VERSION ""

NS_ :

BS_:

BU_: Sound_A Ladegeraet_PAG_PF Motor_EDC17_Pirol PSM_Ant_Derivate GW_Routing_Derivate GW_Applikation_Derivate BMS_Hybrid Getriebe_Derivate LEH_Hybrid Motor_MED17_Hybrid Sound_I Tool Airbag Waehlhebel

BO_ 262 ESP_05_VW: 8 PSM_Ant_Derivate
 SG_ ESP_Status_Anfahrhilfe : 40|1@1+ (1,0) [0|1] ""  Motor_EDC17_Pirol,Motor_MED17_Hybrid,GW_Routing_Derivate
 SG_ ESP_Anforderung_EPB : 62|2@1+ (1,0) [0|3] ""  GW_Routing_Derivate
 SG_ ESP_Lenkeingriff_ADS : 28|1@1+ (1,0) [0|1] ""  GW_Routing_Derivate
 SG_ ESP_Bremsruck_AWV2 : 30|1@1+ (1,0) [0|1] ""  GW_Routing_Derivate
 SG_ ESP_Konsistenz_AWV2 : 31|1@1+ (1,0) [0|1] ""  GW_Routing_Derivate
 SG_ ESP_05_CHK : 0|8@1+ (1,0) [0|255] ""  Motor_EDC17_Pirol,Motor_MED17_Hybrid,GW_Routing_Derivate,Getriebe_Derivate
 SG_ ESP_05_BZ : 8|4@1+ (1,0) [0|15] ""  Motor_EDC17_Pirol,Motor_MED17_Hybrid,GW_Routing_Derivate,Getriebe_Derivate
 SG_ ESP_QBit_Bremsdruck : 12|1@1+ (1,0) [0|1] ""  Motor_EDC17_Pirol,Motor_MED17_Hybrid,GW_Routing_Derivate,Getriebe_Derivate
 SG_ ESP_QBit_Fahrer_bremst : 13|1@1+ (1,0) [0|1] ""  Motor_EDC17_Pirol,Motor_MED17_Hybrid,GW_Routing_Derivate
 SG_ ESP_Schwelle_Unterdruck : 14|2@1+ (1,0) [0|3] ""  Motor_EDC17_Pirol,Motor_MED17_Hybrid,GW_Routing_Derivate
 SG_ ESP_Bremsdruck : 16|10@1+ (0.3,-30) [-30|276.6] "Unit_Bar"  Motor_EDC17_Pirol,Motor_MED17_Hybrid,GW_Routing_Derivate,Getriebe_Derivate
 SG_ ESP_Fahrer_bremst : 26|1@1+ (1,0) [0|1] ""  Motor_EDC17_Pirol,Motor_MED17_Hybrid,GW_Routing_Derivate
 SG_ ESP_Verz_TSK_aktiv : 27|1@1+ (1,0) [0|1] ""  Motor_EDC17_Pirol,Getriebe_Derivate,Motor_MED17_Hybrid,GW_Routing_Derivate
 SG_ ESP_Konsistenz_TSK : 29|1@1+ (1,0) [0|1] ""  Motor_EDC17_Pirol,Motor_MED17_Hybrid,GW_Routing_Derivate
 SG_ ECD_Fehler : 32|1@1+ (1,0) [0|1] ""  Motor_EDC17_Pirol,Motor_MED17_Hybrid,GW_Routing_Derivate
 SG_ ECD_nicht_verfuegbar : 33|1@1+ (1,0) [0|1] ""  Motor_EDC17_Pirol,Motor_MED17_Hybrid,GW_Routing_Derivate
 SG_ ESP_Status_Bremsentemp : 34|1@1+ (1,0) [0|1] ""  Motor_EDC17_Pirol,Motor_MED17_Hybrid,GW_Routing_Derivate
 SG_ ESP_Autohold_Standby : 35|1@1+ (1,0) [0|1] ""  GW_Routing_Derivate
 SG_ ESP_HDC_Standby : 36|1@1+ (1,0) [0|1] ""  Motor_EDC17_Pirol,Motor_MED17_Hybrid,GW_Routing_Derivate
 SG_ ESP_HBA_aktiv : 37|1@1+ (1,0) [0|1] ""  GW_Routing_Derivate
 SG_ ESP_Prefill_ausgeloest : 38|1@1+ (1,0) [0|1] ""  GW_Routing_Derivate
 SG_ ESP_Rueckwaertsfahrt_erkannt : 39|1@1+ (1,0) [0|1] ""  GW_Routing_Derivate
 SG_ ESP_StartStopp_Info : 42|2@1+ (1,0) [0|3] ""  Motor_EDC17_Pirol,Motor_MED17_Hybrid,GW_Routing_Derivate
 SG_ ESP_Eingr_HL : 44|1@1+ (1,0) [0|1] ""  GW_Routing_Derivate
 SG_ ESP_Eingr_HR : 45|1@1+ (1,0) [0|1] ""  GW_Routing_Derivate
 SG_ ESP_Eingr_VL : 46|1@1+ (1,0) [0|1] ""  GW_Routing_Derivate
 SG_ ESP_Eingr_VR : 47|1@1+ (1,0) [0|1] ""  GW_Routing_Derivate
 SG_ ESP_BKV_Unterdruck : 48|8@1+ (4,0) [0|256] "Unit_MilliBar"  Motor_EDC17_Pirol,Motor_MED17_Hybrid,GW_Routing_Derivate
 SG_ ESP_Autohold_aktiv : 56|1@1+ (1,0) [0|1] ""  Motor_EDC17_Pirol,Motor_MED17_Hybrid,GW_Routing_Derivate
 SG_ ESP_FStatus_Anfahrhilfe : 57|1@1+ (1,0) [0|1] ""  GW_Routing_Derivate
 SG_ ESP_Verz_EPB_aktiv : 58|1@1+ (1,0) [0|1] ""  GW_Routing_Derivate,Getriebe_Derivate
 SG_ ECD_Bremslicht : 59|1@1+ (1,0) [0|1] ""  Motor_EDC17_Pirol,Motor_MED17_Hybrid,GW_Routing_Derivate
 SG_ ESP_Verzoeg_EPB_verf : 60|1@1+ (1,0) [0|1] ""  GW_Routing_Derivate
 SG_ ESP_Status_Bremsdruck : 61|1@1+ (1,0) [0|1] ""  Motor_EDC17_Pirol,Motor_MED17_Hybrid,GW_Routing_Derivate

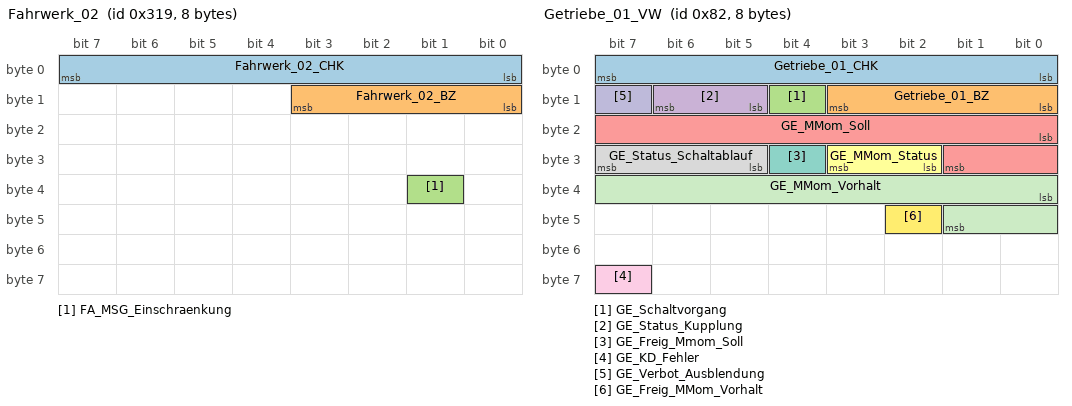
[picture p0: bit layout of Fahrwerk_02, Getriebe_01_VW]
BO_ 793 Fahrwerk_02: 8 GW_Routing_Derivate
 SG_ Fahrwerk_02_CHK : 0|8@1+ (1,0) [0|255] ""  Motor_EDC17_Pirol,Motor_MED17_Hybrid
 SG_ Fahrwerk_02_BZ : 8|4@1+ (1,0) [0|15] ""  Motor_EDC17_Pirol,Motor_MED17_Hybrid
 SG_ FA_MSG_Einschraenkung : 33|1@1+ (1,0) [0|1] ""  Motor_EDC17_Pirol,Motor_MED17_Hybrid

BO_ 924 Gateway_05_VW: 8 GW_Routing_Derivate
 SG_ KL_Beschlagsgefahr : 30|1@1+ (1,0) [0|1] "" Vector__XXX
 SG_ ESP_07_alt : 4|1@1+ (1,0) [0|1] "" Vector__XXX
 SG_ BCM1_GLW_Fernlicht_Anf : 31|1@1+ (1,0) [0|1] "" Vector__XXX
 SG_ BCM1_Gleitende_Leuchtw_Anf : 54|1@1+ (1,0) [0|1] "" Vector__XXX
 SG_ BCM1_Adaptive_Lichtvert_Anf : 53|1@1+ (1,0) [0|1] "" Vector__XXX
 SG_ ESP_Offroad_Modus : 56|1@1+ (1,0) [0|1] ""  Getriebe_Derivate
 SG_ Wischer_vorne_aktiv : 17|1@1+ (1,0) [0|1] ""  Motor_EDC17_Pirol,Motor_MED17_Hybrid
 SG_ HR_Tuer_geoeffnet : 52|1@1+ (1,0) [0|1] ""  Motor_EDC17_Pirol,Motor_MED17_Hybrid
 SG_ HL_Tuer_geoeffnet : 51|1@1+ (1,0) [0|1] ""  Motor_EDC17_Pirol,Motor_MED17_Hybrid
 SG_ FT_Sperrklinke : 35|1@1+ (1,0) [0|1] ""  Motor_EDC17_Pirol,Motor_MED17_Hybrid
 SG_ BT_Tuer_geoeffnet : 50|1@1+ (1,0) [0|1] ""  Motor_EDC17_Pirol,Motor_MED17_Hybrid
 SG_ BCM1_02_alt : 0|1@1+ (1,0) [0|1] ""  Motor_EDC17_Pirol,Motor_MED17_Hybrid
 SG_ BCM1_01_alt : 3|1@1+ (1,0) [0|1] ""  Motor_EDC17_Pirol,Motor_MED17_Hybrid
 SG_ FT_Tuer_geoeffnet : 33|1@1+ (1,0) [0|1] ""  Motor_EDC17_Pirol,Getriebe_Derivate,Motor_MED17_Hybrid
 SG_ BCM1_Rueckfahrlicht_Schalter : 18|1@1+ (1,0) [0|1] ""  Motor_EDC17_Pirol,Motor_MED17_Hybrid
 SG_ BCM1_MH_WIV_Schalter : 16|1@1+ (1,0) [0|1] ""  Motor_EDC17_Pirol,Motor_MED17_Hybrid
 SG_ BCM1_Aussen_Temp_ungef : 40|8@1+ (0.5,-50) [-50|76] "Unit_DegreCelsi"  LEH_Hybrid,BMS_Hybrid,Motor_EDC17_Pirol,Motor_MED17_Hybrid
 SG_ BCM2_03_PAG_alt : 11|1@1+ (1,0) [0|1] "" Vector__XXX
 SG_ Klima_02_alt : 2|1@1+ (1,0) [0|1] "" Vector__XXX
 SG_ KL_Zuheizer_Freigabe : 20|1@1+ (1,0) [0|1] "" Vector__XXX
 SG_ BCM_Handshake_STH : 34|1@1+ (1,0) [0|1] "" Vector__XXX
 SG_ Wischer_01_alt : 1|1@1+ (1,0) [0|1] ""  Motor_EDC17_Pirol,Motor_MED17_Hybrid
 SG_ TSG_BT_1_alt : 5|1@1+ (1,0) [0|1] ""  Motor_EDC17_Pirol,Motor_MED17_Hybrid
 SG_ TSG_HL_1_alt : 6|1@1+ (1,0) [0|1] ""  Motor_EDC17_Pirol,Motor_MED17_Hybrid
 SG_ TSG_HR_1_alt : 7|1@1+ (1,0) [0|1] ""  Motor_EDC17_Pirol,Motor_MED17_Hybrid
 SG_ Klima_Sensor_02_alt : 9|1@1+ (1,0) [0|1] ""  LEH_Hybrid,BMS_Hybrid,Motor_EDC17_Pirol,Motor_MED17_Hybrid
 SG_ TSG_FT_1_alt : 10|1@1+ (1,0) [0|1] ""  Motor_EDC17_Pirol,Getriebe_Derivate,Motor_MED17_Hybrid
 SG_ Parkhilfe_01_alt : 13|1@1+ (1,0) [0|1] ""  Motor_EDC17_Pirol,Motor_MED17_Hybrid
 SG_ Fahrwerk_02_alt : 14|1@1+ (1,0) [0|1] ""  Motor_EDC17_Pirol,Motor_MED17_Hybrid
 SG_ FA_StartStopp_Info : 26|2@1+ (1,0) [0|3] ""  Motor_EDC17_Pirol,Motor_MED17_Hybrid
 SG_ PH_StartStopp_Info : 28|2@1+ (1,0) [0|3] ""  Motor_EDC17_Pirol,Motor_MED17_Hybrid
 SG_ BCM1_OBD_FStatus_ATemp : 36|4@1+ (1,0) [0|15] ""  Motor_EDC17_Pirol,Motor_MED17_Hybrid
 SG_ BCM1_Schalter_StartStopp : 55|1@1+ (1,0) [0|1] ""  Motor_EDC17_Pirol,Motor_MED17_Hybrid

BO_ 1604 Gateway_11_VW: 8 GW_Routing_Derivate
 SG_ ESP_Diagnose : 38|1@1+ (1,0) [0|1] "" Vector__XXX
 SG_ ESP_04_alt : 7|1@1+ (1,0) [0|1] "" Vector__XXX
 SG_ ZV_Tankklappe_offen : 45|1@1+ (1,0) [0|1] "" Vector__XXX
 SG_ BCM_Tankwunsch : 43|2@1+ (1,0) [0|3] "" Vector__XXX
 SG_ ZV_verriegelt_extern_ist : 42|1@1+ (1,0) [0|1] ""  Ladegeraet_PAG_PF
 SG_ BCM2_02_alt : 4|1@1+ (1,0) [0|1] "" Vector__XXX
 SG_ Kessy_01_alt : 8|1@1+ (1,0) [0|1] ""  Ladegeraet_PAG_PF
 SG_ FFB_CarFinder : 41|1@1+ (1,0) [0|1] ""  Ladegeraet_PAG_PF
 SG_ FFB_Auf_Taste : 40|1@1+ (1,0) [0|1] ""  Ladegeraet_PAG_PF
 SG_ Dummy_Blinkmodi_01_alt : 15|1@1+ (1,0) [0|1] "" Vector__XXX
 SG_ BCM1_01_alt : 2|1@1+ (1,0) [0|1] "" Vector__XXX
 SG_ LV_Nebelschlusslicht_Anzeige : 30|1@1+ (1,0) [0|1] "" Vector__XXX
 SG_ LV_Abblendlicht_re_def : 26|1@1+ (1,0) [0|1] "" Vector__XXX
 SG_ LV_Abblendlicht_li_def : 25|1@1+ (1,0) [0|1] "" Vector__XXX
 SG_ BM_Autobahn : 18|1@1+ (1,0) [0|1] "" Vector__XXX
 SG_ BCM1_Touristen_Licht_Anf : 24|1@1+ (1,0) [0|1] "" Vector__XXX
 SG_ BCM1_Linksverkehr : 31|1@1+ (1,0) [0|1] "" Vector__XXX
 SG_ BCM1_Licht_Dunkelheit_aktiv : 29|1@1+ (1,0) [0|1] "" Vector__XXX
 SG_ BCM1_Allwetterlicht_Anf : 36|1@1+ (1,0) [0|1] "" Vector__XXX
 SG_ BCM1_MH_Schalter : 21|1@1+ (1,0) [0|1] ""  Motor_EDC17_Pirol,Motor_MED17_Hybrid
 SG_ BH_Blinker_re : 17|1@1+ (1,0) [0|1] ""  Motor_EDC17_Pirol,Motor_MED17_Hybrid
 SG_ BH_Blinker_li : 16|1@1+ (1,0) [0|1] ""  Motor_EDC17_Pirol,Motor_MED17_Hybrid
 SG_ SMLS_01_alt : 0|1@1+ (1,0) [0|1] ""  Motor_EDC17_Pirol,Motor_MED17_Hybrid
 SG_ BCM1_02_alt : 3|1@1+ (1,0) [0|1] ""  Ladegeraet_PAG_PF,Motor_EDC17_Pirol,Motor_MED17_Hybrid
 SG_ HYB_Anf_E_Mode_alt : 5|1@1+ (1,0) [0|1] ""  Motor_MED17_Hybrid
 SG_ HYB_Anf_E_Mode : 22|1@1+ (1,0) [0|1] ""  Motor_MED17_Hybrid

BO_ 130 Getriebe_01_VW: 8 Getriebe_Derivate
 SG_ Getriebe_01_CHK : 0|8@1+ (1,0) [0|255] ""  Motor_EDC17_Pirol,PSM_Ant_Derivate,GW_Routing_Derivate,Motor_MED17_Hybrid
 SG_ Getriebe_01_BZ : 8|4@1+ (1,0) [0|15] ""  Motor_EDC17_Pirol,PSM_Ant_Derivate,GW_Routing_Derivate,Motor_MED17_Hybrid
 SG_ GE_Schaltvorgang : 12|1@1+ (1,0) [0|1] ""  Motor_EDC17_Pirol,PSM_Ant_Derivate,GW_Routing_Derivate,Motor_MED17_Hybrid
 SG_ GE_Status_Kupplung : 13|2@1+ (1,0) [0|3] ""  Motor_EDC17_Pirol,PSM_Ant_Derivate,GW_Routing_Derivate,Motor_MED17_Hybrid
 SG_ GE_MMom_Soll : 16|10@1+ (1,0) [0|1021] ""  Motor_EDC17_Pirol,PSM_Ant_Derivate,GW_Routing_Derivate,Motor_MED17_Hybrid
 SG_ GE_MMom_Status : 26|2@1+ (1,0) [0|3] ""  Motor_EDC17_Pirol,PSM_Ant_Derivate,GW_Routing_Derivate,Motor_MED17_Hybrid
 SG_ GE_Freig_Mmom_Soll : 28|1@1+ (1,0) [0|1] ""  PSM_Ant_Derivate,GW_Routing_Derivate
 SG_ GE_Status_Schaltablauf : 29|3@1+ (1,0) [0|7] ""  PSM_Ant_Derivate,GW_Routing_Derivate
 SG_ GE_KD_Fehler : 63|1@1+ (1,0) [0|1] ""  PSM_Ant_Derivate,GW_Applikation_Derivate,GW_Routing_Derivate
 SG_ GE_Verbot_Ausblendung : 15|1@1+ (1,0) [0|1] ""  GW_Routing_Derivate,Motor_EDC17_Pirol,Motor_MED17_Hybrid
 SG_ GE_MMom_Vorhalt : 32|10@1+ (1,0) [0|1021] ""  GW_Routing_Derivate,Motor_EDC17_Pirol,Motor_MED17_Hybrid
 SG_ GE_Freig_MMom_Vorhalt : 42|1@1+ (1,0) [0|1] ""  GW_Routing_Derivate,Motor_EDC17_Pirol,Motor_MED17_Hybrid

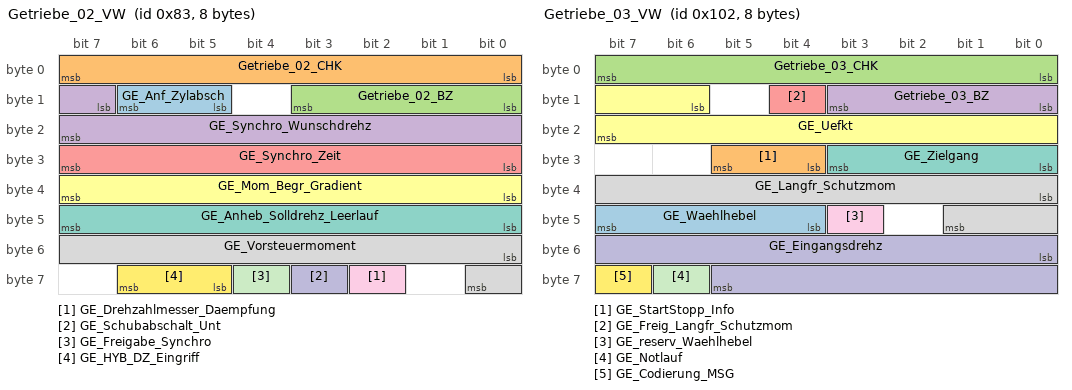
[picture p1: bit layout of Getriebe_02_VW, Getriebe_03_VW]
BO_ 131 Getriebe_02_VW: 8 Getriebe_Derivate
 SG_ GE_Anf_Zylabsch : 13|2@1+ (1,0) [0|3] "" Vector__XXX
 SG_ Getriebe_02_CHK : 0|8@1+ (1,0) [0|255] ""  Motor_EDC17_Pirol,Motor_MED17_Hybrid
 SG_ Getriebe_02_BZ : 8|4@1+ (1,0) [0|15] ""  Motor_EDC17_Pirol,Motor_MED17_Hybrid
 SG_ GE_Synchro_Wunschdrehz : 15|9@1+ (25,0) [0|12750] "Unit_MinutInver"  Motor_EDC17_Pirol,Motor_MED17_Hybrid
 SG_ GE_Synchro_Zeit : 24|8@1+ (20,0) [0|5080] "Unit_MilliSecon"  Motor_EDC17_Pirol,Motor_MED17_Hybrid
 SG_ GE_Mom_Begr_Gradient : 32|8@1+ (10,0) [0|2540] "Unit_NewtoMeterPerSecon"  Motor_EDC17_Pirol,Motor_MED17_Hybrid
 SG_ GE_Anheb_Solldrehz_Leerlauf : 40|8@1+ (10,0) [0|2540] "Unit_MinutInver"  Motor_EDC17_Pirol,Motor_MED17_Hybrid
 SG_ GE_Vorsteuermoment : 48|9@1+ (1,0) [0|509] ""  Motor_EDC17_Pirol,Motor_MED17_Hybrid
 SG_ GE_Drehzahlmesser_Daempfung : 58|1@1+ (1,0) [0|1] ""  Motor_EDC17_Pirol,Motor_MED17_Hybrid
 SG_ GE_Schubabschalt_Unt : 59|1@1+ (1,0) [0|1] ""  Motor_EDC17_Pirol,Motor_MED17_Hybrid
 SG_ GE_Freigabe_Synchro : 60|1@1+ (1,0) [0|1] ""  Motor_EDC17_Pirol,Motor_MED17_Hybrid
 SG_ GE_HYB_DZ_Eingriff : 61|2@1+ (1,0) [0|3] ""  Motor_MED17_Hybrid

BO_ 258 Getriebe_03_VW: 8 Getriebe_Derivate
 SG_ GE_Waehlhebel : 44|4@1+ (1,0) [0|15] ""  Motor_EDC17_Pirol,GW_Routing_Derivate,PSM_Ant_Derivate,Motor_MED17_Hybrid
 SG_ GE_StartStopp_Info : 28|2@1+ (1,0) [0|3] ""  Motor_EDC17_Pirol,GW_Routing_Derivate,PSM_Ant_Derivate,Motor_MED17_Hybrid
 SG_ Getriebe_03_CHK : 0|8@1+ (1,0) [0|255] ""  Motor_EDC17_Pirol,PSM_Ant_Derivate,GW_Routing_Derivate,Motor_MED17_Hybrid
 SG_ Getriebe_03_BZ : 8|4@1+ (1,0) [0|15] ""  Motor_EDC17_Pirol,PSM_Ant_Derivate,GW_Routing_Derivate,Motor_MED17_Hybrid
 SG_ GE_Freig_Langfr_Schutzmom : 12|1@1+ (1,0) [0|1] ""  Motor_EDC17_Pirol,PSM_Ant_Derivate,GW_Routing_Derivate,Motor_MED17_Hybrid
 SG_ GE_Uefkt : 14|10@1+ (0.1,0) [0|102.2] ""  Motor_EDC17_Pirol,PSM_Ant_Derivate,GW_Routing_Derivate,Motor_MED17_Hybrid
 SG_ GE_Zielgang : 24|4@1+ (1,0) [0|15] ""  Motor_EDC17_Pirol,PSM_Ant_Derivate,GW_Routing_Derivate,Motor_MED17_Hybrid
 SG_ GE_Langfr_Schutzmom : 32|10@1+ (1,0) [0|1021] ""  Motor_EDC17_Pirol,PSM_Ant_Derivate,GW_Routing_Derivate,Motor_MED17_Hybrid
 SG_ GE_reserv_Waehlhebel : 43|1@1+ (1,0) [0|1] ""  PSM_Ant_Derivate,GW_Routing_Derivate
 SG_ GE_Eingangsdrehz : 48|14@1+ (1,0) [0|16381] "Unit_MinutInver"  Motor_EDC17_Pirol,PSM_Ant_Derivate,GW_Routing_Derivate,Motor_MED17_Hybrid
 SG_ GE_Notlauf : 62|1@1+ (1,0) [0|1] ""  Motor_EDC17_Pirol,PSM_Ant_Derivate,GW_Routing_Derivate,Motor_MED17_Hybrid
 SG_ GE_Codierung_MSG : 63|1@1+ (1,0) [0|1] ""  PSM_Ant_Derivate,GW_Routing_Derivate

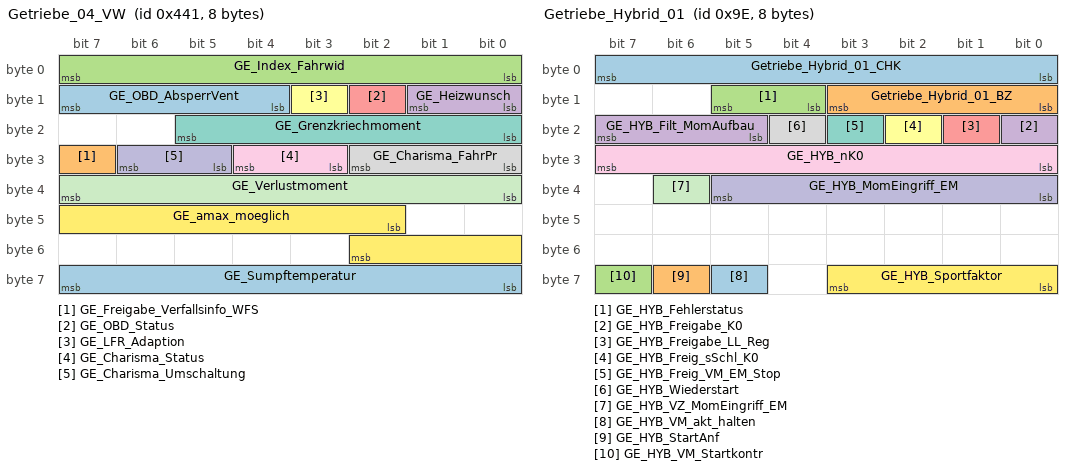
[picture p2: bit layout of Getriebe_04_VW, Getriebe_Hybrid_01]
BO_ 1089 Getriebe_04_VW: 8 Getriebe_Derivate
 SG_ GE_OBD_AbsperrVent : 12|4@1+ (1,0) [0|15] ""  GW_Routing_Derivate,Motor_EDC17_Pirol,Motor_MED17_Hybrid
 SG_ GE_Freigabe_Verfallsinfo_WFS : 31|1@1+ (1,0) [0|1] ""  GW_Routing_Derivate
 SG_ GE_Index_Fahrwid : 0|8@1+ (0.249,-31.623) [-31.623|31.623] ""  GW_Routing_Derivate,Motor_EDC17_Pirol,PSM_Ant_Derivate,Motor_MED17_Hybrid
 SG_ GE_Heizwunsch : 8|2@1+ (1,0) [0|3] ""  GW_Routing_Derivate,PSM_Ant_Derivate,Motor_MED17_Hybrid,Motor_EDC17_Pirol
 SG_ GE_OBD_Status : 10|1@1+ (1,0) [0|1] ""  GW_Routing_Derivate,Motor_EDC17_Pirol,PSM_Ant_Derivate,Motor_MED17_Hybrid
 SG_ GE_LFR_Adaption : 11|1@1+ (1,0) [0|1] ""  GW_Routing_Derivate,Motor_EDC17_Pirol,PSM_Ant_Derivate,Motor_MED17_Hybrid
 SG_ GE_Grenzkriechmoment : 16|6@1+ (2,0) [0|122] ""  GW_Routing_Derivate,PSM_Ant_Derivate
 SG_ GE_Charisma_FahrPr : 24|3@1+ (1,0) [0|7] ""  GW_Routing_Derivate
 SG_ GE_Charisma_Status : 27|2@1+ (1,0) [0|3] ""  GW_Routing_Derivate,PSM_Ant_Derivate
 SG_ GE_Charisma_Umschaltung : 29|2@1+ (1,0) [0|3] ""  GW_Routing_Derivate
 SG_ GE_Verlustmoment : 32|8@1+ (1,0) [0|254] ""  GW_Routing_Derivate,Motor_EDC17_Pirol,PSM_Ant_Derivate,Motor_MED17_Hybrid
 SG_ GE_amax_moeglich : 42|9@1+ (0.024,-2.016) [-2.016|10.224] "Unit_MeterPerSeconSquar"  GW_Routing_Derivate,Motor_EDC17_Pirol,PSM_Ant_Derivate,Motor_MED17_Hybrid
 SG_ GE_Sumpftemperatur : 56|8@1+ (1,-58) [-58|196] "Unit_DegreCelsi"  GW_Routing_Derivate,BMS_Hybrid,Motor_EDC17_Pirol,PSM_Ant_Derivate,Motor_MED17_Hybrid

BO_ 158 Getriebe_Hybrid_01: 8 Getriebe_Derivate
 SG_ Getriebe_Hybrid_01_CHK : 0|8@1+ (1,0) [0|255] "" Vector__XXX
 SG_ Getriebe_Hybrid_01_BZ : 8|4@1+ (1,0) [0|15] ""  Motor_MED17_Hybrid
 SG_ GE_HYB_Fehlerstatus : 12|2@1+ (1,0) [0|3] ""  Motor_MED17_Hybrid
 SG_ GE_HYB_Freigabe_K0 : 16|1@1+ (1,0) [0|1] ""  Motor_MED17_Hybrid
 SG_ GE_HYB_Freigabe_LL_Reg : 17|1@1+ (1,0) [0|1] ""  Motor_MED17_Hybrid
 SG_ GE_HYB_Freig_sSchl_K0 : 18|1@1+ (1,0) [0|1] ""  Motor_MED17_Hybrid
 SG_ GE_HYB_Freig_VM_EM_Stop : 19|1@1+ (1,0) [0|1] ""  Motor_MED17_Hybrid
 SG_ GE_HYB_Wiederstart : 20|1@1+ (1,0) [0|1] ""  Motor_MED17_Hybrid
 SG_ GE_HYB_nK0 : 24|8@1+ (25,0) [0|6350] "Unit_MinutInver" Vector__XXX
 SG_ GE_HYB_MomEingriff_EM : 32|6@1+ (0.5,0) [0|31.5] "Unit_NewtoMeter" Vector__XXX
 SG_ GE_HYB_VZ_MomEingriff_EM : 38|1@1+ (1,0) [0|1] "" Vector__XXX
 SG_ GE_HYB_Sportfaktor : 56|4@1+ (1,0) [0|15] ""  Motor_MED17_Hybrid
 SG_ GE_HYB_VM_akt_halten : 61|1@1+ (1,0) [0|1] ""  Motor_MED17_Hybrid
 SG_ GE_HYB_StartAnf : 62|1@1+ (1,0) [0|1] ""  Motor_MED17_Hybrid
 SG_ GE_HYB_VM_Startkontr : 63|1@1+ (1,0) [0|1] ""  Motor_MED17_Hybrid
 SG_ GE_HYB_Filt_MomAufbau : 21|3@1+ (1,0) [0|7] "" Vector__XXX

BO_ 2022 ISO_EMotor_01_Req: 8 GW_Routing_Derivate
 SG_ ISO_EMotor_01_Req_Data : 0|64@1+ (1,0) [0|1] ""  LEH_Hybrid

BO_ 2030 ISO_EMotor_01_Resp: 8 LEH_Hybrid
 SG_ ISO_EMotor_01_Resp_Data : 0|64@1+ (1,0) [0|1] ""  GW_Routing_Derivate

BO_ 2021 ISO_Hybrid_01_Req: 8 GW_Routing_Derivate
 SG_ ISO_Hybrid_01_Req_Data : 0|64@1+ (1,0) [0|1] ""  BMS_Hybrid

BO_ 2029 ISO_Hybrid_01_Resp: 8 BMS_Hybrid
 SG_ ISO_Hybrid_01_Resp_Data : 0|64@1+ (1,0) [0|1] ""  GW_Routing_Derivate

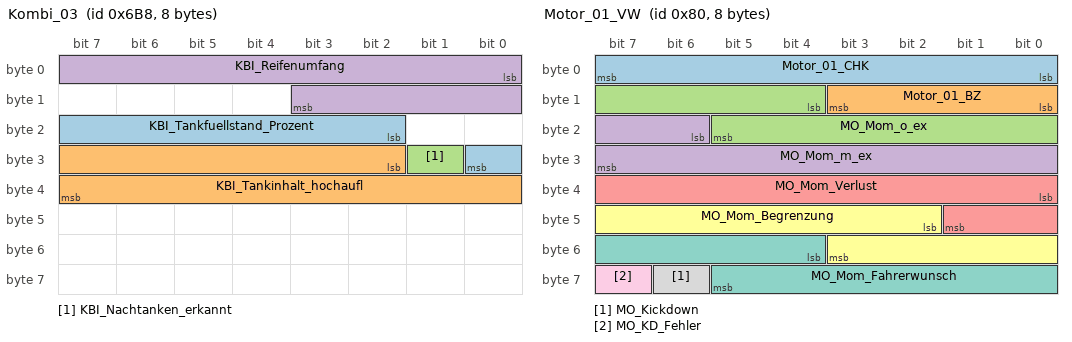
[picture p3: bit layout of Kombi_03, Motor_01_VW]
BO_ 1720 Kombi_03: 8 GW_Routing_Derivate
 SG_ KBI_Tankfuellstand_Prozent : 18|7@1+ (1,0) [0|100] "Unit_PerCent" Vector__XXX
 SG_ KBI_Tankinhalt_hochaufl : 26|14@1+ (0.01,0) [0|163.81] "Unit_Liter"  BMS_Hybrid
 SG_ KBI_Nachtanken_erkannt : 25|1@1+ (1,0) [0|1] ""  BMS_Hybrid
 SG_ KBI_Reifenumfang : 0|12@1+ (1,0) [0|4095] "Unit_MilliMeter"  Motor_MED17_Hybrid,PSM_Ant_Derivate

BO_ 128 Motor_01_VW: 8 Motor_MED17_Hybrid
 SG_ Motor_01_CHK : 0|8@1+ (1,0) [0|255] ""  PSM_Ant_Derivate,GW_Routing_Derivate,Getriebe_Derivate
 SG_ Motor_01_BZ : 8|4@1+ (1,0) [0|15] ""  PSM_Ant_Derivate,GW_Routing_Derivate,Getriebe_Derivate
 SG_ MO_Mom_o_ex : 12|10@1+ (1,0) [0|1021] ""  Sound_A,Sound_I,PSM_Ant_Derivate,GW_Routing_Derivate,Getriebe_Derivate
 SG_ MO_Mom_m_ex : 22|10@1+ (1,0) [0|1021] ""  PSM_Ant_Derivate,GW_Routing_Derivate,Getriebe_Derivate
 SG_ MO_Mom_Verlust : 32|10@1+ (1,0) [0|1021] ""  Sound_A,Sound_I,PSM_Ant_Derivate,GW_Routing_Derivate,Getriebe_Derivate
 SG_ MO_Mom_Begrenzung : 42|10@1+ (1,0) [0|1021] ""  PSM_Ant_Derivate,GW_Routing_Derivate,Getriebe_Derivate
 SG_ MO_Mom_Fahrerwunsch : 52|10@1+ (1,0) [0|1021] ""  PSM_Ant_Derivate,GW_Routing_Derivate,Getriebe_Derivate
 SG_ MO_Kickdown : 62|1@1+ (1,0) [0|1] ""  PSM_Ant_Derivate,GW_Routing_Derivate,Getriebe_Derivate
 SG_ MO_KD_Fehler : 63|1@1+ (1,0) [0|1] ""  PSM_Ant_Derivate,GW_Applikation_Derivate,GW_Routing_Derivate

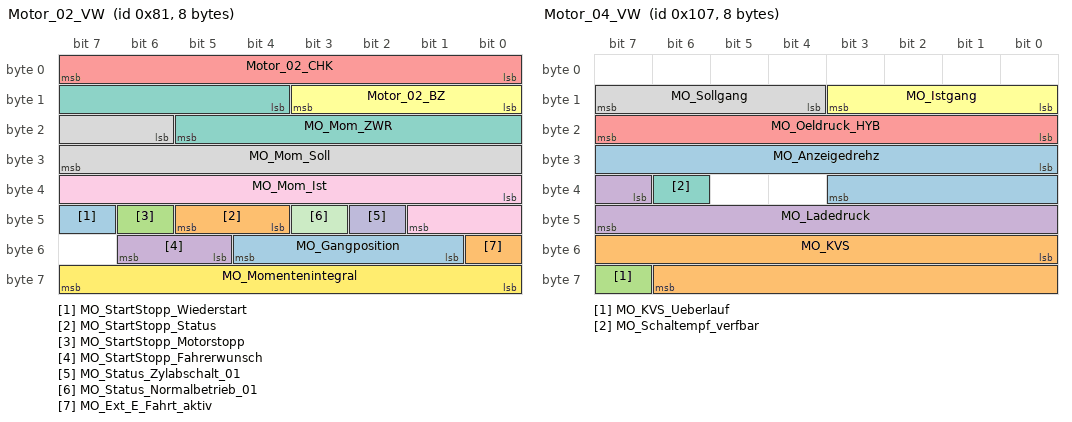
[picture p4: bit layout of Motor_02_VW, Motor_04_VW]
BO_ 129 Motor_02_VW: 8 Motor_MED17_Hybrid
 SG_ MO_StartStopp_Wiederstart : 47|1@1+ (1,0) [0|1] ""  GW_Routing_Derivate,PSM_Ant_Derivate,GW_Applikation_Derivate,Getriebe_Derivate
 SG_ MO_StartStopp_Status : 44|2@1+ (1,0) [0|3] ""  GW_Routing_Derivate,PSM_Ant_Derivate,GW_Applikation_Derivate
 SG_ MO_StartStopp_Motorstopp : 46|1@1+ (1,0) [0|1] ""  GW_Routing_Derivate,LEH_Hybrid,PSM_Ant_Derivate,GW_Applikation_Derivate,Getriebe_Derivate
 SG_ MO_StartStopp_Fahrerwunsch : 53|2@1+ (1,0) [0|3] ""  GW_Routing_Derivate
 SG_ Motor_02_CHK : 0|8@1+ (1,0) [0|255] ""  PSM_Ant_Derivate,GW_Routing_Derivate,Getriebe_Derivate
 SG_ Motor_02_BZ : 8|4@1+ (1,0) [0|15] ""  PSM_Ant_Derivate,GW_Routing_Derivate,Getriebe_Derivate
 SG_ MO_Mom_ZWR : 12|10@1+ (1,0) [0|1021] ""  PSM_Ant_Derivate,Getriebe_Derivate
 SG_ MO_Mom_Soll : 22|10@1+ (1,0) [0|1021] ""  PSM_Ant_Derivate
 SG_ MO_Mom_Ist : 32|10@1+ (1,0) [0|1021] ""  PSM_Ant_Derivate,Getriebe_Derivate
 SG_ MO_Status_Zylabschalt_01 : 42|1@1+ (1,0) [0|1] ""  PSM_Ant_Derivate
 SG_ MO_Status_Normalbetrieb_01 : 43|1@1+ (1,0) [0|1] ""  PSM_Ant_Derivate,Getriebe_Derivate
 SG_ MO_Momentenintegral : 56|8@1+ (0.3921,0) [0|99.9855] ""  PSM_Ant_Derivate,Getriebe_Derivate
 SG_ MO_Gangposition : 49|4@1+ (1,0) [0|15] "" Vector__XXX
 SG_ MO_Ext_E_Fahrt_aktiv : 48|1@1+ (1,0) [0|1] ""  Getriebe_Derivate,GW_Routing_Derivate

BO_ 261 Motor_03_VW: 8 Motor_MED17_Hybrid
 SG_ MO_QBit_Motormomente : 13|1@1+ (1,0) [0|1] ""  Getriebe_Derivate,GW_Routing_Derivate,PSM_Ant_Derivate
 SG_ Motor_03_CHK : 0|8@1+ (1,0) [0|255] ""  BMS_Hybrid,PSM_Ant_Derivate,LEH_Hybrid,GW_Routing_Derivate,Getriebe_Derivate
 SG_ Motor_03_BZ : 8|4@1+ (1,0) [0|15] ""  BMS_Hybrid,PSM_Ant_Derivate,LEH_Hybrid,GW_Routing_Derivate,Getriebe_Derivate
 SG_ MO_QBit_Fahrpedalwerte_01 : 12|1@1+ (1,0) [0|1] ""  BMS_Hybrid,PSM_Ant_Derivate,GW_Routing_Derivate,Getriebe_Derivate
 SG_ MO_QBit_Fahrer_bremst : 14|1@1+ (1,0) [0|1] ""  PSM_Ant_Derivate,GW_Routing_Derivate,Getriebe_Derivate
 SG_ MO_QBit_Drehzahl_01 : 15|1@1+ (1,0) [0|1] ""  PSM_Ant_Derivate,BMS_Hybrid,GW_Routing_Derivate,Getriebe_Derivate,LEH_Hybrid
 SG_ MO_Drehzahl_01 : 16|16@1+ (0.25,0) [0|16383] "Unit_MinutInver"  Sound_A,Sound_I,PSM_Ant_Derivate,BMS_Hybrid,GW_Applikation_Derivate,GW_Routing_Derivate,Getriebe_Derivate,LEH_Hybrid
 SG_ MO_Moment_im_Leerlauf : 32|1@1+ (1,0) [0|1] ""  PSM_Ant_Derivate,GW_Routing_Derivate,Getriebe_Derivate
 SG_ MO_Interlock : 33|1@1+ (1,0) [0|1] ""  PSM_Ant_Derivate,GW_Routing_Derivate
 SG_ MO_BLS : 34|1@1+ (1,0) [0|1] ""  PSM_Ant_Derivate,GW_Routing_Derivate,Getriebe_Derivate
 SG_ MO_Fahrer_bremst : 35|1@1+ (1,0) [0|1] ""  PSM_Ant_Derivate,GW_Routing_Derivate,Getriebe_Derivate
 SG_ MO_Konsistenz_Bremsped : 36|1@1+ (1,0) [0|1] ""  PSM_Ant_Derivate,GW_Routing_Derivate
 SG_ MO_Kuppl_schalter : 37|1@1+ (1,0) [0|1] ""  PSM_Ant_Derivate,GW_Routing_Derivate
 SG_ MO_Timeout_ESP : 38|1@1+ (1,0) [0|1] ""  PSM_Ant_Derivate,GW_Routing_Derivate
 SG_ MO_Motor_laeuft : 39|1@1+ (1,0) [0|1] ""  PSM_Ant_Derivate,GW_Applikation_Derivate,GW_Routing_Derivate,Getriebe_Derivate
 SG_ MO_Solldrehz_Leerlauf : 40|8@1+ (10,0) [0|2540] "Unit_MinutInver"  PSM_Ant_Derivate,GW_Routing_Derivate,Getriebe_Derivate,GW_Applikation_Derivate
 SG_ MO_Fahrpedalrohwert_01 : 48|8@1+ (0.4,0) [0|101.6] "Unit_PerCent"  Sound_A,Sound_I,BMS_Hybrid,PSM_Ant_Derivate,GW_Routing_Derivate,Getriebe_Derivate
 SG_ MO_erste_Ungenauschwelle : 56|1@1+ (1,0) [0|1] ""  PSM_Ant_Derivate,GW_Routing_Derivate,Getriebe_Derivate
 SG_ MO_QBit_Stressfaktor : 57|1@1+ (1,0) [0|1] ""  PSM_Ant_Derivate,GW_Routing_Derivate
 SG_ MO_Stressfaktor : 58|6@1+ (1.6,0) [0|100.8] "Unit_PerCent"  PSM_Ant_Derivate,GW_Routing_Derivate

BO_ 263 Motor_04_VW: 8 Motor_MED17_Hybrid
 SG_ MO_Anzeigedrehz : 24|12@1+ (3,0) [0|12282] "U/min"  PSM_Ant_Derivate,GW_Routing_Derivate
 SG_ MO_KVS : 48|15@1+ (1,0) [0|32767] "Unit_MicroLiter"  BMS_Hybrid,PSM_Ant_Derivate,GW_Routing_Derivate
 SG_ MO_KVS_Ueberlauf : 63|1@1+ (1,0) [0|1] ""  BMS_Hybrid,PSM_Ant_Derivate,GW_Routing_Derivate
 SG_ MO_Ladedruck : 39|9@1+ (0.01,0) [0|5.1] "Unit_Bar"  GW_Routing_Derivate,PSM_Ant_Derivate
 SG_ MO_Oeldruck_HYB : 16|8@1+ (0.04,0) [0|10] "Uni_Bar"  GW_Routing_Derivate
 SG_ MO_Istgang : 8|4@1+ (1,0) [0|15] "" Vector__XXX
 SG_ MO_Schaltempf_verfbar : 38|1@1+ (1,0) [0|1] "" Vector__XXX
 SG_ MO_Sollgang : 12|4@1+ (1,0) [0|15] "" Vector__XXX

BO_ 782 Motor_05_VW: 8 Motor_MED17_Hybrid
 SG_ MO_Handshake_STH : 47|1@1+ (1,0) [0|1] ""  GW_Routing_Derivate
 SG_ Motor_05_CHK : 0|8@1+ (1,0) [0|255] ""  GW_Routing_Derivate,Getriebe_Derivate
 SG_ Motor_05_BZ : 8|4@1+ (1,0) [0|15] ""  GW_Routing_Derivate,Getriebe_Derivate
 SG_ MO_EKlKomLeiRed : 12|2@1+ (1,0) [0|3] ""  GW_Routing_Derivate
 SG_ MO_Freig_Reku : 14|2@1+ (1,0) [0|3] ""  BMS_Hybrid,GW_Routing_Derivate,GW_Applikation_Derivate
 SG_ MO_Klima_Eingr : 16|2@1+ (1,0) [0|3] ""  GW_Routing_Derivate
 SG_ MO_Status_Normalbetrieb_02 : 18|1@1+ (1,0) [0|1] ""  GW_Routing_Derivate
 SG_ MO_Schaltbeeinfl_Leistungsbegr : 19|1@1+ (1,0) [0|1] ""  GW_Routing_Derivate
 SG_ MO_Schaltbeeinfl_Partikelfilter : 20|1@1+ (1,0) [0|1] ""  GW_Routing_Derivate,Getriebe_Derivate
 SG_ MO_Prio_MIN_Wunschdrehzahl : 21|1@1+ (1,0) [0|1] ""  GW_Routing_Derivate,Getriebe_Derivate
 SG_ MO_Freig_Anlass : 22|1@1+ (1,0) [0|1] ""  GW_Routing_Derivate
 SG_ MO_Aussp_Anlass : 23|1@1+ (1,0) [0|1] ""  GW_Routing_Derivate
 SG_ MO_MAX_Wunschdrehzahl : 24|9@1+ (25,0) [0|12750] "Unit_MinutInver"  GW_Routing_Derivate,Getriebe_Derivate
 SG_ MO_Prio_MAX_Wunschdrehzahl : 33|1@1+ (1,0) [0|1] ""  GW_Routing_Derivate,Getriebe_Derivate
 SG_ MO_Luftpfad_aktiv : 34|1@1+ (1,0) [0|1] ""  GW_Routing_Derivate
 SG_ MO_v_Begrenz_Aktiv : 35|1@1+ (1,0) [0|1] ""  GW_Routing_Derivate
 SG_ MO_v_Begrenz_Aktivierbar : 36|1@1+ (1,0) [0|1] ""  GW_Routing_Derivate
 SG_ MO_Verbot_EKP : 37|1@1+ (1,0) [0|1] ""  GW_Routing_Derivate
 SG_ MO_Anf_Pruefimpuls : 38|1@1+ (1,0) [0|1] ""  GW_Routing_Derivate
 SG_ MO_Anf_KL75 : 39|1@1+ (1,0) [0|1] ""  GW_Routing_Derivate
 SG_ MO_Charisma_FahrPr : 40|3@1+ (1,0) [0|7] ""  GW_Routing_Derivate
 SG_ MO_Charisma_Status : 43|2@1+ (1,0) [0|3] ""  PSM_Ant_Derivate,GW_Routing_Derivate
 SG_ MO_Charisma_Umschaltung : 45|2@1+ (1,0) [0|3] ""  GW_Routing_Derivate
 SG_ MO_MIN_Wunschdrehzahl : 48|8@1+ (25,0) [0|6350] "Unit_MinutInver"  GW_Routing_Derivate,Getriebe_Derivate
 SG_ MO_Drehzahlbeeinflussung : 56|8@1+ (0.39,0) [0|99.45] "Unit_PerCent"  GW_Routing_Derivate

BO_ 1088 Motor_06_VW: 8 Motor_MED17_Hybrid
 SG_ MO_Kat_Warnung : 22|1@1+ (1,0) [0|1] ""  GW_Routing_Derivate
 SG_ MO_ITM_Warnung_Pumpe : 11|1@1+ (1,0) [0|1] ""  GW_Routing_Derivate
 SG_ MO_HYB_Text_4 : 31|1@1+ (1,0) [0|1] ""  GW_Routing_Derivate
 SG_ MO_HYB_Status_HV_Ladung : 8|3@1+ (1,0) [0|7] ""  GW_Routing_Derivate
 SG_ MO_Zustand_HWP : 20|2@1+ (1,0) [0|3] ""  GW_Routing_Derivate
 SG_ MO_Kuehlerluefter_MUX M : 0|1@1+ (1,0) [0|1] ""  GW_Routing_Derivate
 SG_ MO_Kuehlerluefter_1 m0 : 1|7@1+ (1,0) [0|100] "Unit_PerCent"  GW_Routing_Derivate
 SG_ MO_Kuehlerluefter_2 m1 : 1|7@1+ (1,0) [0|100] "Unit_PerCent"  GW_Routing_Derivate
 SG_ WIV_Anzeige_aktiv : 12|1@1+ (1,0) [0|1] ""  GW_Routing_Derivate
 SG_ WIV_Oelmin_Warn : 13|1@1+ (1,0) [0|1] ""  GW_Routing_Derivate
 SG_ WIV_Sensorfehler : 14|1@1+ (1,0) [0|1] ""  GW_Routing_Derivate
 SG_ WIV_Schieflage : 15|1@1+ (1,0) [0|1] ""  GW_Routing_Derivate
 SG_ WIV_Oelstand : 16|4@1+ (12.5,0) [0|100] "Unit_PerCent"  GW_Routing_Derivate
 SG_ WIV_Oelsystem_aktiv : 24|1@1+ (1,0) [0|1] ""  GW_Routing_Derivate
 SG_ WIV_nicht_betriebswarm : 25|1@1+ (1,0) [0|1] ""  GW_Routing_Derivate
 SG_ WIV_Ueberfuell_Warn : 26|1@1+ (1,0) [0|1] ""  GW_Routing_Derivate
 SG_ WIV_laufender_Motor : 27|1@1+ (1,0) [0|1] ""  GW_Routing_Derivate
 SG_ MO_Text_Motorstart : 32|4@1+ (1,0) [0|15] ""  GW_Routing_Derivate
 SG_ MO_Text_MSG_Werkstatt : 40|1@1+ (1,0) [0|1] ""  GW_Routing_Derivate
 SG_ MO_Text_Partikelfil_Reg : 41|1@1+ (1,0) [0|1] ""  GW_Routing_Derivate
 SG_ MO_Text_Fehler_Kraftstoffsys : 42|1@1+ (1,0) [0|1] ""  GW_Routing_Derivate
 SG_ WIV_Oelmenge : 43|5@1+ (125,0) [0|3875] "Unit_MilliLiter"  GW_Routing_Derivate
 SG_ MO_Systemlampe : 48|1@1+ (1,0) [0|1] ""  GW_Routing_Derivate
 SG_ MO_OBD2_Lampe : 49|1@1+ (1,0) [0|1] ""  GW_Routing_Derivate
 SG_ MO_Heissleuchte : 50|1@1+ (1,0) [0|1] ""  GW_Routing_Derivate
 SG_ MO_Partikel_Lampe : 51|1@1+ (1,0) [0|1] ""  GW_Routing_Derivate
 SG_ MO_Winterfahrprog : 52|1@1+ (1,0) [0|1] ""  GW_Routing_Derivate
 SG_ WIV_Oelstand_nicht_vorhanden : 53|1@1+ (1,0) [0|1] ""  GW_Routing_Derivate
 SG_ WIV_nachfuellanzeige_ein : 54|1@1+ (1,0) [0|1] ""  GW_Routing_Derivate
 SG_ WIV_Ueberfuell_deaktiv : 55|1@1+ (1,0) [0|1] ""  GW_Routing_Derivate
 SG_ WIV_Unterfuell_Warn : 56|1@1+ (1,0) [0|1] ""  GW_Routing_Derivate
 SG_ MO_Tankdeckel_Lampe : 57|1@1+ (1,0) [0|1] ""  GW_Routing_Derivate
 SG_ MO_Text_Tankdeckelwarn : 58|1@1+ (1,0) [0|1] ""  GW_Routing_Derivate
 SG_ WIV_Enable_Oeldr_Motor : 59|1@1+ (1,0) [0|1] ""  GW_Routing_Derivate
 SG_ WIV_Oeldr_Warn_Motor : 60|1@1+ (1,0) [0|1] ""  GW_Routing_Derivate
 SG_ MO_Avus_Motorschutz : 61|2@1+ (1,0) [0|3] ""  GW_Routing_Derivate
 SG_ MO_HYB_Fahrbereitschaft : 63|1@1+ (1,0) [0|1] ""  Sound_A,Sound_I,BMS_Hybrid,GW_Applikation_Derivate,GW_Routing_Derivate
 SG_ WIV_Oeldyn_avl : 39|1@1+ (1,0) [0|1] ""  GW_Routing_Derivate
 SG_ MO_HYB_Text_7 : 38|1@1+ (1,0) [0|1] ""  GW_Routing_Derivate
 SG_ MO_HYB_Text_6 : 37|1@1+ (1,0) [0|1] ""  GW_Routing_Derivate
 SG_ MO_HYB_Text_5 : 36|1@1+ (1,0) [0|1] ""  GW_Routing_Derivate
 SG_ MO_HYB_Text_3 : 30|1@1+ (1,0) [0|1] ""  GW_Routing_Derivate
 SG_ MO_HYB_Text_2 : 29|1@1+ (1,0) [0|1] ""  GW_Routing_Derivate
 SG_ MO_HYB_Text_1 : 28|1@1+ (1,0) [0|1] ""  GW_Routing_Derivate

BO_ 1600 Motor_07_VW: 8 Motor_MED17_Hybrid
 SG_ MO_Nachlaufzeit_Heizungspumpe : 58|6@1+ (15,0) [0|945] "Unit_Secon"  GW_Routing_Derivate
 SG_ MO_Kennfeldk : 40|1@1+ (1,0) [0|1] ""  GW_Routing_Derivate
 SG_ MO_QBit_Ansaugluft_Temp : 0|1@1+ (1,0) [0|1] ""  GW_Routing_Derivate
 SG_ MO_QBit_Oel_Temp : 1|1@1+ (1,0) [0|1] ""  GW_Routing_Derivate
 SG_ MO_QBit_Kuehlmittel_Temp : 2|1@1+ (1,0) [0|1] ""  GW_Routing_Derivate,Getriebe_Derivate,LEH_Hybrid
 SG_ MO_Stellgliedtest_Soundaktuator : 3|1@1+ (1,0) [0|1] ""  GW_Routing_Derivate
 SG_ MO_HYB_Fehler_HV_Netz : 4|1@1+ (1,0) [0|1] ""  GW_Applikation_Derivate,GW_Routing_Derivate
 SG_ MO_Absperrventil_oeffnen : 6|2@1+ (1,0) [0|3] ""  GW_Routing_Derivate
 SG_ MO_Ansaugluft_Temp : 8|8@1+ (0.75,-48) [-48|141.75] "Unit_DegreCelsi"  GW_Routing_Derivate,Getriebe_Derivate
 SG_ MO_Oel_Temp : 16|8@1+ (1,-60) [-60|193] "Unit_DegreCelsi"  GW_Routing_Derivate
 SG_ MO_Kuehlmittel_Temp : 24|8@1+ (0.75,-48) [-48|141.75] "Unit_DegreCelsi"  BMS_Hybrid,GW_Applikation_Derivate,GW_Routing_Derivate,Getriebe_Derivate,LEH_Hybrid
 SG_ MO_Hoeheninfo : 32|8@1+ (0.00781,0) [0|1.98374] ""  GW_Routing_Derivate,Getriebe_Derivate
 SG_ MO_Versionsinfo : 41|6@1+ (1,0) [0|63] ""  Getriebe_Derivate,GW_Routing_Derivate
 SG_ MO_Getriebe_kuehlen : 47|1@1+ (1,0) [0|1] ""  Getriebe_Derivate,GW_Routing_Derivate
 SG_ MO_Mom_Traegheit_02 : 48|5@1+ (0.01,0) [0|0.31] "Unit_KiloGramMeterSquar"  GW_Routing_Derivate
 SG_ MO_Heizungspumpenansteuerung : 53|4@1+ (10,0) [0|100] "Unit_PerCent"  GW_Routing_Derivate
 SG_ MO_SpannungsAnf : 57|1@1+ (1,0) [0|1] ""  GW_Applikation_Derivate,GW_Routing_Derivate
 SG_ MO_aktives_Getriebeheizen : 5|1@1+ (1,0) [0|1] ""  Getriebe_Derivate,GW_Routing_Derivate

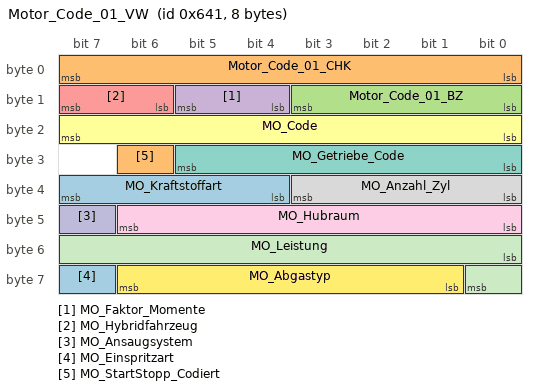
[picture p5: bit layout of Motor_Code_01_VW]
BO_ 1601 Motor_Code_01_VW: 8 Motor_MED17_Hybrid
 SG_ MO_Kraftstoffart : 36|4@1+ (1,0) [0|15] ""  PSM_Ant_Derivate,GW_Routing_Derivate,Getriebe_Derivate
 SG_ Motor_Code_01_CHK : 0|8@1+ (1,0) [0|255] ""  PSM_Ant_Derivate,LEH_Hybrid,GW_Routing_Derivate,Getriebe_Derivate
 SG_ Motor_Code_01_BZ : 8|4@1+ (1,0) [0|15] ""  PSM_Ant_Derivate,LEH_Hybrid,GW_Routing_Derivate,Getriebe_Derivate
 SG_ MO_Faktor_Momente : 12|2@1+ (1,0) [0|3] ""  PSM_Ant_Derivate,GW_Routing_Derivate,Getriebe_Derivate
 SG_ MO_Hybridfahrzeug : 14|2@1+ (1,0) [0|3] ""  PSM_Ant_Derivate,GW_Routing_Derivate
 SG_ MO_Code : 16|8@1+ (1,0) [0|255] ""  PSM_Ant_Derivate,GW_Routing_Derivate,Getriebe_Derivate
 SG_ MO_Getriebe_Code : 24|6@1+ (1,0) [0|63] ""  PSM_Ant_Derivate,GW_Routing_Derivate,Getriebe_Derivate
 SG_ MO_Anzahl_Zyl : 32|4@1+ (1,0) [0|15] ""  GW_Routing_Derivate
 SG_ MO_Hubraum : 40|7@1+ (0.1,0) [0|12.7] "Unit_Liter"  GW_Routing_Derivate
 SG_ MO_Ansaugsystem : 47|1@1+ (1,0) [0|1] ""  GW_Routing_Derivate
 SG_ MO_Leistung : 48|9@1+ (1,0) [0|511] "Unit_KiloWatt"  GW_Routing_Derivate,Getriebe_Derivate
 SG_ MO_Abgastyp : 57|6@1+ (1,0) [0|63] ""  LEH_Hybrid,BMS_Hybrid,GW_Routing_Derivate,Getriebe_Derivate
 SG_ MO_Einspritzart : 63|1@1+ (1,0) [0|1] ""  GW_Routing_Derivate
 SG_ MO_StartStopp_Codiert : 30|1@1+ (1,0) [0|1] ""  GW_Routing_Derivate,Getriebe_Derivate

BO_TX_BU_ 128 : Motor_EDC17_Pirol,Motor_MED17_Hybrid;
BO_TX_BU_ 129 : Motor_EDC17_Pirol,Motor_MED17_Hybrid;
BO_TX_BU_ 261 : Motor_EDC17_Pirol,Motor_MED17_Hybrid;
BO_TX_BU_ 263 : Motor_EDC17_Pirol,Motor_MED17_Hybrid;
BO_TX_BU_ 782 : Motor_EDC17_Pirol,Motor_MED17_Hybrid;
BO_TX_BU_ 1088 : Motor_EDC17_Pirol,Motor_MED17_Hybrid;
BO_TX_BU_ 1600 : Motor_EDC17_Pirol,Motor_MED17_Hybrid;
BO_TX_BU_ 1601 : Motor_EDC17_Pirol,Motor_MED17_Hybrid;
CM_ SG_ 262 ESP_Status_Anfahrhilfe "Funktionsstatus des Berganfahrassistenten
MQB: Auswertung im Getriebe zwecks Standabkopplung";
CM_ SG_ 262 ESP_Anforderung_EPB "ESP fordert von der EPB Öffnen bzw. Schliessen an. Notwendig wegen Hillholder-Funktion im ESP.
";
CM_ SG_ 262 ESP_Lenkeingriff_ADS "Gilt nicht für PAG G1 Hybrid.
Im Falle eines fahrzeugstabilisierenden Lenkeingriffs des ADS-Systems soll ACC/GRA deaktiviert werden.";
CM_ SG_ 262 ESP_Bremsruck_AWV2 "Das Signal dient als Rückmeldung zum ACC, dass ein angeforderter AWV2-Bremsruck durchgeführt wird. Die positive Rückmeldung löst u.a. eine entsprechende Fahrerinformation im Kombiinstrument aus";
CM_ SG_ 262 ESP_Konsistenz_AWV2 "Rückmeldung zum Sender einer AWV-Anforderung (ACC-Steuergerät) bezüglich Prüfung der Checksumme, des Botschaftszählers, des langen Timeout und DLC.
";
CM_ SG_ 262 ESP_05_CHK "Berechnung siehe Lastenheft 'Kommunikationsabsicherung für FlexRay und CAN'
Endwerte siehe 'Kommunikationsabsicherung für FlexRay und CAN / Anhang C: Tabelle S-PDU Kennungen'";
CM_ SG_ 262 ESP_QBit_Bremsdruck "QBit des Bremsdrucks";
CM_ SG_ 262 ESP_QBit_Fahrer_bremst "Gültigkeit der redundanten Bremspedalinformation vom ESP SG

0x1 = eingeschränkte Signalgüte

Im B8 gilt die Signalspezifikation LAH8K0907AF: 05-08-23_Lastenheft_Bremslichtinfo_B8_V6.4_yellow.pdf - Bremslichtinfo

Im D4 gilt die Signalspezifikation ";
CM_ SG_ 262 ESP_Schwelle_Unterdruck "Gilt nicht für PAG G1 Hybrid.
Vorhalt VW für HBV-Projekte";
CM_ SG_ 262 ESP_Bremsdruck "Bremsdruck / Vordruck durch Fahrervorgabe (Pvor). Bei aktivem Druckaufbau (Stabilisierungseingriffe) kein Pvor
";
CM_ SG_ 262 ESP_Fahrer_bremst "Bit gibt die Information aus, ob der Fahrer gebremst hat oder nicht. Redundante Bremsinformation vom ESP, wird bei Audi im B8 bedient!

Schwelle außerhalb Regelung 12bar, in Regelung 30bar

Im B8 gilt die Signalspezifikation LAH8K0907AF: 05-08-23_Last";
CM_ SG_ 262 ESP_Verz_TSK_aktiv "Rückmeldeinformation an den Triebsstrangkoordinator/ACC, dass die ECD-Verzögerungsanforderung aktuell umgesetzt wird";
CM_ SG_ 262 ESP_Konsistenz_TSK "Rückmeldung zum Sender einer Verzögerungsanforderung (Triebstrangskoordinator) bezüglich Prüfung der Checksumme, des Botschaftszählers, des langen Timeout und DLC. Wird auch gesetzt bei Verzögerungsanforderung größer einer applizierbaren Schwelle.
";
CM_ SG_ 262 ECD_Fehler "ESP kann die Verzögerungsregelung/Bremsenregelung aufgrund eines internen Fehlers nicht ausführen, mit Fehlereintrag im ESP.
";
CM_ SG_ 262 ECD_nicht_verfuegbar "ESP kann die Verzögerungsregelung/Bremsenregelung temporär nicht ausführen (z.B. Netzwerkmanagement-Betriebe - KL15 Aus; v<18km/h; ESP in Diagnose, ...), ohne Fehlereintrag im ESP.

";
CM_ SG_ 262 ESP_Status_Bremsentemp "ECD-Bremsscheibentemperaturmodell. Rückmeldung für Sender einer ECD Verzögerungsanforderung, ohne Fehlereintrag im ESP";
CM_ SG_ 262 ESP_Autohold_Standby "Rückmeldung an EPB, dass der Fahrer die Funktion Autohold mindestens einmal angefordert hat. Im Fall eines ESP-Ausfalles oder einer Übernahmeaufforderung erfolgt die EPB-Zuschaltung nur nach Setzen dieses Bits. Bit wird gesetzt nach Betätigung des Autohol";
CM_ SG_ 262 ESP_HDC_Standby "für Q5 und B8 allroad:
Flag wird vom ESP gesetzt, wenn über den HDC-Taster die HDC-Funktion eingeschalten wurde";
CM_ SG_ 262 ESP_HBA_aktiv "Signal gibt an, ob der hydraulische Bremsassistent im Regler aktiviert wurde";
CM_ SG_ 262 ESP_Prefill_ausgeloest "zeigt, ob die Funktion Prefill (aufgrund Fahrpedalgradient) ausgelöst wird; zeigt keinen Funktionszustand bezüglich Fehlerstilllegung";
CM_ SG_ 262 ESP_Rueckwaertsfahrt_erkannt "nur im Q5: ESP gibt Info, ob Rückwärtsfahrt über internen Algorithmus sicher erkannt";
CM_ SG_ 262 ESP_StartStopp_Info "Stopp-Freigabe und Start-Anforderung an den Start-Stopp-Koordinator";
CM_ SG_ 262 ESP_Eingr_HL "Flag wird vom ESP gesetzt, sobald aufgrund eines ESP-Eingriffs am Rad aktiv Druck aufgebaut wird.
Frühestens mit öffnen des Ventils und spätestens bei einem Bremsmoment von 100Nm. Flag bleibt solange gesetzt wie ein Bremsmoment von mehr als 100Nm anliegt";
CM_ SG_ 262 ESP_Eingr_HR "Flag wird vom ESP gesetzt, sobald aufgrund eines ESP-Eingriffs am Rad aktiv Druck aufgebaut wird.
Frühestens mit öffnen des Ventils und spätestens bei einem Bremsmoment von 100Nm. Flag bleibt solange gesetzt wie ein Bremsmoment von mehr als 100Nm anliegt";
CM_ SG_ 262 ESP_Eingr_VL "Flag wird vom ESP gesetzt, sobald aufgrund eines ESP-Eingriffs am Rad aktiv Druck aufgebaut wird.
Frühestens mit öffnen des Ventils und spätestens bei einem Bremsmoment von 100Nm. Flag bleibt solange gesetzt wie ein Bremsmoment von mehr als 100Nm anliegt";
CM_ SG_ 262 ESP_Eingr_VR "Flag wird vom ESP gesetzt, sobald aufgrund eines ESP-Eingriffs am Rad aktiv Druck aufgebaut wird.
Frühestens mit öffnen des Ventils und spätestens bei einem Bremsmoment von 100Nm. Flag bleibt solange gesetzt wie ein Bremsmoment von mehr als 100Nm anliegt";
CM_ SG_ 262 ESP_BKV_Unterdruck "Der maximale Wert wird auf 1016 mbar begrenzr (Vorhalt für HBV-Projekte VW)";
CM_ SG_ 262 ESP_Autohold_aktiv "Rückmeldung an EPB, dass Autohold aktiv ist. Einführung mit Hillholder-Konzept im B8.";
CM_ SG_ 262 ESP_FStatus_Anfahrhilfe "Bei gesetztem Fehler steht die Hillhold-Funktion nicht zur Verfügung
B8: Bit wird nur im Fehlerfall HHC in VL300-Fzg. gesetzt";
CM_ SG_ 262 ESP_Verz_EPB_aktiv "Bei gesetztem Bit wird die Verzögerungsanforderung von EPB umgesetzt.";
CM_ SG_ 262 ECD_Bremslicht "Bremslichtansteuerung durch ECD-Funktion.
Im B8 gilt die Signalspezifikation LAH8K0907AF: 05-08-23_Lastenheft_Bremslichtinfo_B8_V6.4_yellow.pdf - Bremslichtinfo
(in Gateway_01_VW: Signal wird nur im Panamera H/P bedient)";
CM_ SG_ 262 ESP_Verzoeg_EPB_verf "Bei gesetztem Bit ist der Verzögerungsregeler für EPB verfügbar.";
CM_ SG_ 262 ESP_Status_Bremsdruck "Bei gesetztem Bit liegt p > ca. 2 bar an, hervorgerufen durch Fahrer, ASR, FZR, ECD, Bremsregler ... bei Abfall des Bits ist p < X bar, bei aktivem ECD-Eingriff Ende des Eingriffs 
";
CM_ BO_ 793 "wird im G1P+G1H von MED/EDC nicht verwendet";
CM_ SG_ 793 Fahrwerk_02_CHK "Berechnung siehe Lastenheft 'Kommunikationsabsicherung für FlexRay und CAN'
Endwerte siehe 'Kommunikationsabsicherung für FlexRay und CAN / Anhang C: Tabelle S-PDU Kennungen'";
CM_ SG_ 793 FA_MSG_Einschraenkung "Eingriff im Motor-SG (z.B.: v-Begrenzung im Hochniveau)

Wird im D4 nicht bedient";
CM_ SG_ 924 KL_Beschlagsgefahr "Beschlagsgefahr auf der Frontscheibe im Bereich des Spiegelfusses. Dient zur präventiven Ansteuerung der  Kamera-Scheibenheizung, um Kamera-Blindheit zu vermeiden
PHEV: volle Leistungsfreigabe HV Heizer und HV EKK bei Scheibenbeschlag ";
CM_ SG_ 924 ESP_07_alt "Veraltet Bit für die Signale:

Botschaft Gateway_05:
ESP_Codierung_ADS

Botschaft Gateway_06:
ESP_Codierung_ADS
";
CM_ SG_ 924 BCM1_GLW_Fernlicht_Anf "Harte Fernlichtanforderung von BCM1 an die Funktion 'gleitende Leuchtweite' im AFS-SG
(Signal wird im Panamera nicht bedient)";
CM_ SG_ 924 BCM1_Gleitende_Leuchtw_Anf "Funktion 'Gleitende Leuchtweite' im AFS-SG  freischalten
(Signal wird im Panamera nicht bedient)";
CM_ SG_ 924 BCM1_Adaptive_Lichtvert_Anf "Funktion 'Adaptive Lichtverteilung' im AFS-SG  Ein- und Ausschalten
(Signal wird im Panamera nicht bedient)";
CM_ SG_ 924 ESP_Offroad_Modus "Nur VW526: Bei Offroad-Fahrzeugen kann über einen Schalter ein Offroadmodus gewählt werden, dieser wird hier angezeigt. Bei Offroad Plus- Fahrzeugen wird hier der Offroadmodus indirekt durch das Verteilergetriebe vorgegeben (ALR_Offroad = 1) und eingespie";
CM_ SG_ 924 Wischer_vorne_aktiv "Status: Wischer vorne";
CM_ SG_ 924 HR_Tuer_geoeffnet "Tuer HR geoeffnet";
CM_ SG_ 924 HL_Tuer_geoeffnet "Tuer HL geoeffnet";
CM_ SG_ 924 BT_Tuer_geoeffnet "Beifahrertuer geoeffnet";
CM_ SG_ 924 BCM1_02_alt "Veraltet Bit für die Signale:

Botschaft Gateway_05:
BCM1_MH_WIV_Schalter
BCM1_Oeldruck_Schalter
BCM1_Oeldruck_Schalter_2

Botschaft Gateway_11:
LV_Abblendlicht_Anzeige
LV_Abblendlicht_li_def
LV_Abblendlicht_re_def

Botschaft Gateway_07:
LV_F";
CM_ SG_ 924 BCM1_01_alt "Veraltet Bit für die Signale:

Botschaft Gateway_04:
BCM1_Charisma_Text_1
BCM1_Charisma_Text_2

Botschaft Gateway_05:
BCM1_Rueckfahrlicht_Schalter
BCM1_Vorwaertsgang_eingelegt
BCM1_RFahrlicht_Fzg_Anf

Botschaft Gateway_07:
BCM1_Rueckfahrlicht_";
CM_ SG_ 924 FT_Tuer_geoeffnet "Fahrertuer geoeffnet";
CM_ SG_ 924 BCM1_Rueckfahrlicht_Schalter "Rückwärtsganginformation (unabhängig von Automatikgetriebe oder Handschalter)
(Quellsignal ist das Signal 'S_RF_Licht' vom BCM2. Es wird im BCM2 aus dem Signal 'Poshebel' und dem HW-Eingang S_RF_Licht gebildet.)";
CM_ SG_ 924 BCM1_MH_WIV_Schalter "Gilt nicht für PAG Panamera Basis. Wird konstant mit 0 gesendet.
Bewerteter Motorhaubenkontakt fuer WIV";
CM_ SG_ 924 BCM1_Aussen_Temp_ungef "ungefilterter Wert des Aussentemperatursensors
Quelle der Information ist die Bedien-Klimaeinheit BKE mit dem Signal 'KL_Atemp_ungef'
Das BCM1 muss dieses Signal weiterverarbeiten um die Wohlfühlumgebung für die Empfänger (TSG) zu ermöglichen";
CM_ SG_ 924 BCM2_03_PAG_alt "Ungültige Signale

für Botschaft: Gateway_05
BCM_Handshake_STH";
CM_ SG_ 924 Klima_02_alt "Ungueltige Signale:  KL_Zuheizer_Freigabe";
CM_ SG_ 924 KL_Zuheizer_Freigabe "Freigabe Zuheizer";
CM_ SG_ 924 BCM_Handshake_STH "Bestätigung für Kraftstoffpumpenanst
CAN Antr. im G1 nicht weckfähig->Handshake mit STH kann nicht stattfinden
Workaround für Panamera: Signal wird vom BCM2 gesendet
Zum E2 ist CAN Antrieb weckfähig->Signal kann direkt von der DME gesendet werden";
CM_ SG_ 924 Wischer_01_alt "Veraltet Bit für die Signale:

Botschaft Gateway_04:
Wischer_vorne_defekt

Botschaft Gateway_05:
Wischer_vorne_aktiv

Botschaft Gateway_07:
Wischer_vorne_aktiv";
CM_ SG_ 924 TSG_BT_1_alt "Veraltet Bit für die Signale:

Botschaft Gateway_05:
BT_Tuer_geoeffnet";
CM_ SG_ 924 TSG_HL_1_alt "Veraltet Bit für die Signale:

Botschaft Gateway_05:
HL_Tuer_geoeffnet";
CM_ SG_ 924 TSG_HR_1_alt "Veraltet Bit für die Signale:

Botschaft Gateway_05:
HR_Tuer_geoeffnet

MOST:";
CM_ SG_ 924 Klima_Sensor_02_alt "Veraltet Bit für die Signale:
Gateway_04:
BCM1_FStatus_Aussentemp_ungef
BCM1_Aussen_Temp_ungef
Gateway_05:
BCM1_FStatus_Aussentemp_ungef
BCM1_Aussen_Temp_ungef
BCM1_OBD_FStatus_ATemp
Gateway_07:
BCM1_Aussen_Temp_ungef
BCM1_FStatus_Au..";
CM_ SG_ 924 TSG_FT_1_alt "Veraltet Bit für die Signale:

Botschaft Gateway_04:
FT_Kisi_Fehler

Botschaft Gateway_05:
FT_Tuer_geoeffnet
FT_Sperrklinke

Botschaft Gateway_09:
FT_Tuer_geoeffnet";
CM_ SG_ 924 Parkhilfe_01_alt "Veraltet Bit für die Signale:

Botschaft Gateway_09:
PH_Anf_Audioabsenkung
";
CM_ SG_ 924 Fahrwerk_02_alt "Veraltet-Bit für die Signale:

Botschaft Charisma_02:
QS_Charisma_FahrPr
QS_Charisma_Status
QS_Charisma_Umschaltung";
CM_ SG_ 924 FA_StartStopp_Info "Stopp-Freigabe und Start-Anforderung an den Start-Stopp-Koordinator";
CM_ SG_ 924 PH_StartStopp_Info "Stopp-Freigabe und Start-Anforderung an den Start-Stopp-Koordinator";
CM_ SG_ 924 BCM1_OBD_FStatus_ATemp "Fehlerstatus Umgebungstemperatursensor (OBD relevanter Sensor)
";
CM_ SG_ 924 BCM1_Schalter_StartStopp "Deaktivierung Start/Stopp über Fahrer";
CM_ BO_ 1604 "langsame Gatewaybotschaft für den ACAN";
CM_ SG_ 1604 ESP_Diagnose "Nach Diagnoseende wird ein SW-Reset ausgelöst welcher einen Kommunikatiosausfall für max. 150ms verursacht. Dies ist bei SG mit verschärfter Timeoutüberwachung (nicht nach Konzern-LH) zu beachten.";
CM_ SG_ 1604 ESP_04_alt "Veraltet Bit für die Signale:

Botschaft Gateway_02:
ESP_Wegimp_VA
ESP_QBit_Wegimp_VA
ESP_Wegimp_Ueberlauf
ESP_Zaehnezahl
ESP_Diagnose
";
CM_ SG_ 1604 ZV_Tankklappe_offen "Öffnungsstatus der Tankklappe";
CM_ SG_ 1604 BCM_Tankwunsch "Tankwunsch (Fahrer betätigt Tankdeckeltaster)";
CM_ SG_ 1604 ZV_verriegelt_extern_ist "Istzustand: Verriegelung Fahrzeug aussen";
CM_ SG_ 1604 BCM2_02_alt "Veraltet Bit für die Signale:

Botschaft Gateway_11:
BCM2_P_verriegelt
ZV_verriegelt_extern_ist
ZV_Tankklappe_offen
BCM_Tankwunsch";
CM_ SG_ 1604 Kessy_01_alt "Veraltet Bit für die Signale: FFB_Auf_Taste, FFB_CarFinder
";
CM_ SG_ 1604 FFB_CarFinder "Car Finder Funktion (Blinken ohne zu entriegeln)";
CM_ SG_ 1604 FFB_Auf_Taste "Auf-Taste Funkschluessel";
CM_ SG_ 1604 Dummy_Blinkmodi_01_alt "Dummy-Veraltet-Bit für Ausfall Signal BM_Autobahn.
Grund: PAG Gateway benötigt Veraltet-Bit für Ausfall Botschaft Blinkmodi_01, die aber nicht zyklisch gesendet wird
";
CM_ SG_ 1604 BCM1_01_alt "Veraltet Bit für die Signale:

Botschaft Gateway_04:
BCM1_Charisma_Text_1
BCM1_Charisma_Text_2

Botschaft Gateway_05:
BCM1_Rueckfahrlicht_Schalter
BCM1_Vorwaertsgang_eingelegt
BCM1_RFahrlicht_Fzg_Anf

Botschaft Gateway_07:
BCM1_Rueckfahrlicht_";
CM_ SG_ 1604 LV_Nebelschlusslicht_Anzeige "Nebelschlusslicht aktiv";
CM_ SG_ 1604 LV_Abblendlicht_re_def "Fehlerstatus Abblendlicht vorne rechts";
CM_ SG_ 1604 LV_Abblendlicht_li_def "Fehlerstatus Abblendlicht vorne links";
CM_ SG_ 1604 BM_Autobahn "Status Autobahnblinken";
CM_ SG_ 1604 BCM1_Touristen_Licht_Anf "Anforderung: Touristenlicht (Sollzustand)
(Signal wird im Panamera nicht bedient)";
CM_ SG_ 1604 BCM1_Linksverkehr "Information über Aufbauzustand des Fzg:
(Signal wird im Panamera nicht bedient)";
CM_ SG_ 1604 BCM1_Licht_Dunkelheit_aktiv "Licht aktiv aufgrund von Dunkelheit (nicht bei Autobahn-, Tagfahr- oder Regenlicht)
(Signal wird im Panamera nicht bedient)";
CM_ SG_ 1604 BCM1_Allwetterlicht_Anf "Anforderung eines Allwetterlichts (über AFS-SG realisiert) bei AUDI: Licht für schlechte Sichtverhältnisse
(Signal wird im Panamera nicht bedient)";
CM_ SG_ 1604 BCM1_MH_Schalter "Motorhaubenkontakt";
CM_ SG_ 1604 BH_Blinker_re "Blinkerhebel Richtung rechts";
CM_ SG_ 1604 BH_Blinker_li "Blinkerhebel Richtung links";
CM_ SG_ 1604 SMLS_01_alt "Veraltet Bit für die Signale:

Botschaft Gateway_07:
BH_Blinker_li
BH_Blinker_re
LDW_Taster
LDW_Taster_Fehler
LDW_Vib_Lenkrad_Fehler
BH_Fernlicht

Botschaft Gateway_11:
BH_Blinker_li
BH_Blinker_re
";
CM_ SG_ 1604 BCM1_02_alt "Veraltet Bit für die Signale:

Botschaft Gateway_05:
BCM1_MH_WIV_Schalter
BCM1_Oeldruck_Schalter
BCM1_Oeldruck_Schalter_2

Botschaft Gateway_11:
LV_Abblendlicht_Anzeige
LV_Abblendlicht_li_def
LV_Abblendlicht_re_def

Botschaft Gateway_07:
LV_F";
CM_ SG_ 1604 HYB_Anf_E_Mode_alt "funktionales Veraltet-Bit für Hybrid-Taster
Ungueltige Signale: HYB_Anf_E_Mode
";
CM_ SG_ 1604 HYB_Anf_E_Mode "E-Taste (Hybrid)
(Signal wird im Panamera nicht vom BCM1 bedient, sondern von der BKE (Klima_08_PAG))";
CM_ SG_ 130 Getriebe_01_CHK "Berechnung siehe Lastenheft 'Kommunikationsabsicherung für FlexRay und CAN'
Endwerte siehe 'Kommunikationsabsicherung für FlexRay und CAN / Anhang C: Tabelle S-PDU Kennungen'";
CM_ SG_ 130 GE_Status_Kupplung "Auch für Anfahrkupplung beim VL30 und Kupplung beim Ecodrive (geregelt bedeutet in diesem Fall die Kupplung ist nicht vollständig getrennt bzw. hat Schlupf) genutzt; bei starken Verstellwegen wird 'geöffnet' gesendet (VQ250)";
CM_ SG_ 130 GE_MMom_Soll "Achtung:
Einheitenloser CAN-Wert.
Faktor in MO_Faktor_Momente in Motor_Code_01 beachten!

Getriebeeingriff an den Motor. Indiziertes Moment.";
CM_ SG_ 130 GE_MMom_Status "Qualifiziert GE_MMom_Soll";
CM_ SG_ 130 GE_Freig_Mmom_Soll "Entfall des Signals in v698, da nicht mehr benötigt";
CM_ SG_ 130 GE_Verbot_Ausblendung "Verbot Einspritzausblendung für komfortable Schaltungen";
CM_ SG_ 130 GE_MMom_Vorhalt "Anforderung einer Momentenreserve durch das Getriebe, inneres Moment, gilt nur mit Freigabe durch 
GE_Freig_MMom_Vorhalt

Achtung!
Einheitenloser CAN-Wert.
Faktor in MO_Faktor_Momente in Motor_Code_01 beachten!";
CM_ SG_ 130 GE_Freig_MMom_Vorhalt "Freigabe für die Anforderung einer Momentenreserve durch das Getriebe über das Signal GE_MMom_Vorhalt";
CM_ SG_ 131 GE_Anf_Zylabsch "GE_Anforderung_Zylinderabschaltung
Getriebe-Koordination Zylinderumschaltung TMB / VMB (Teilmotorbetrieb / Vollmotorbetrieb)";
CM_ SG_ 131 Getriebe_02_CHK "Berechnung siehe Lastenheft 'Kommunikationsabsicherung für FlexRay und CAN'
Endwerte siehe 'Kommunikationsabsicherung für FlexRay und CAN / Anhang C: Tabelle S-PDU Kennungen'";
CM_ SG_ 131 GE_Mom_Begr_Gradient "Drehmomenten-Gradientenbegrenzung für Teillastanfahrten mit dem VL30-Getriebe und Standabkopplung beim 5HPx, 6HPx. Wird auch während Schaltungen verwendet.";
CM_ SG_ 131 GE_Anheb_Solldrehz_Leerlauf "Wunschvorgabewert des Getriebes an den Motor, die Leerlaufdrehzahl auf den gesendeten Betrag x anzuheben (Vorgabe des Absolutwertes)";
CM_ SG_ 131 GE_Vorsteuermoment "Achtung:
Einheitenloser CAN-Wert.
Faktor in MO_Faktor_Momente in Motor_Code_01 beachten!

Vorsteuermoment für Leerlaufdrehzahlregler im Motor";
CM_ SG_ 131 GE_Drehzahlmesser_Daempfung "Beim DQ-Getriebe kann die Anzeigedämpfung des Drehzahlmessers beim Schalten geändert werden.";
CM_ SG_ 131 GE_Schubabschalt_Unt "Wenn die Schubabschalt-Unterstützung aktiv ist, wird vom VL300-Steuergerät sichergestellt, daß die Kupplung nicht schlagartig geöffnet wird.";
CM_ SG_ 131 GE_Freigabe_Synchro "Freigabe Synchronisations-Wunschdrehzahl und Synchronisationszeit";
CM_ SG_ 131 GE_HYB_DZ_Eingriff "Freigabebedingung für Drehzahleingriff-Hybrid";
CM_ SG_ 258 GE_Waehlhebel "Getriebeposition (Nicht Wählhebelposition!)
Die im Getriebe aktive Fahrstufe entspricht nicht unter allen Umständen der phy. Wählhebelpos.
Unterschied zu 'GE_poshebel' in Getriebe_01 ist die Wertetabelle (= wie VW/Audi für Wohlfuehlumgebung Komf.-SG)";
CM_ SG_ 258 GE_StartStopp_Info "Start/Stop-Info, Veto";
CM_ SG_ 258 Getriebe_03_CHK "Berechnung siehe Lastenheft 'Kommunikationsabsicherung für FlexRay und CAN'
Endwerte siehe 'Kommunikationsabsicherung für FlexRay und CAN / Anhang C: Tabelle S-PDU Kennungen'";
CM_ SG_ 258 GE_Freig_Langfr_Schutzmom "Freigabeflag für das langfristige Schutzmoment";
CM_ SG_ 258 GE_Uefkt "Übertragungsfunktion vom Getriebe

Wandlerverstärkung x Drehzahlverhältnis

Beim Kupplungsautomat (VL, DL) ist der Faktor 1";
CM_ SG_ 258 GE_Zielgang "Zielgang, wenn Schaltung aktiv ist. Ansonsten wird der aktuell eingelegte Gang ausgegeben. 

0x9 - 0xA = tbd
0xD = tbd.
";
CM_ SG_ 258 GE_Langfr_Schutzmom "Achtung:
Einheitenloser CAN-Wert.
Faktor in MO_Faktor_Momente in Motor_Code_01 beachten!

geführter Getriebeschutz";
CM_ SG_ 258 GE_reserv_Waehlhebel "reserviert falls künftig Erweiterung von GE_Waehlhebel nötig";
CM_ SG_ 258 GE_Eingangsdrehz "Wird gesendet, um das Lastschlagverhalten bei Schaltvorgängen zu verbessern.";
CM_ SG_ 258 GE_Codierung_MSG "Wenn das Getriebe bei der Codierplausibilisierung zum Motor einen Fehler erkennt wird das Bit auf 0x1 gesetzt. ESP wirft daraufhin die Funktion ab.";
CM_ SG_ 1089 GE_OBD_AbsperrVent "Das Getriebesteuergerät führt eine elektrische Diagnose des von ihm angesteuerten Absperrventils für den Öl-Wasser-Wärmetauscher durch und übermittelt das Ergebnis an das MSG (Standard-4Bit-OBD-Status, nicht alle Zustände müssen genutzt werden; so sind z.";
CM_ SG_ 1089 GE_Freigabe_Verfallsinfo_WFS "WFS";
CM_ SG_ 1089 GE_Index_Fahrwid "Auf % Steigung am Berg normiert";
CM_ SG_ 1089 GE_OBD_Status "Dieses Bit steuert die MIL-Lampe an (Motorsteuergerät reicht diese Info an Kombi weiter).";
CM_ SG_ 1089 GE_LFR_Adaption "Da das VL30-Getriebe im Stillstand unter gewissen Randbedingungen wechselnde Kupplungsmomente einstellt (z.B. Hillholder), sollte die Leerlaufauffüllungsadaption im Motorsteuergerät für diese Zustände gesperrt werden. 

";
CM_ SG_ 1089 GE_Grenzkriechmoment "Achtung:
Einheitenloser CAN-Wert.
Faktor in MO_Faktor_Momente in Motor_Code_01 beachten!

Es gilt: Signalspec GE_Grenzkriechmoment v1.0

Maximales Kupplungs-/Wandlermoment im Leerlauf. Darin sind motorische Umwelteinflüsse enthalten. CAN-Wert = 0,5 ";
CM_ SG_ 1089 GE_Charisma_FahrPr "Aktuelles Fahrprogramm des Charisma-Teilnehmers

Achtung neue Modusnamen (wie im MMI):

0x1 = Komfort = Comfort
0x2 = Dynamik = Auto
0x3 = Sport = Dynamic";
CM_ SG_ 1089 GE_Charisma_Status "Charisma Systemstatus des Charisma-Teilnehmers";
CM_ SG_ 1089 GE_Charisma_Umschaltung "Erkennung  Umschaltaufforderung des Charisma-Teilnehmers";
CM_ SG_ 1089 GE_Verlustmoment "Achtung:
Einheitenloser CAN-Wert.
Faktor in MO_Faktor_Momente in Motor_Code_01 beachten!

Es gilt: Signalspec GE_Verlustmoment v1.0

Verlustmoment inklusive Pumpenaufnahmemoment (Rechenwert aus CAN-Werten und Kennfeldern ermittelt). Inhalt wird alle";
CM_ SG_ 1089 GE_amax_moeglich "Fzg mit Stufenautomat: Maximale mögliche Beschleunigung bei der jetzigen Übersetzung (Übertragungsfunktion), bezogen auf Begrenzungsmoment, Fahrzeugmasse, Fahrwiderstandsindex und Motor Stressfaktor

Fzg mit stufenlosem Getriebe: Maximale mögliche Besch";
CM_ SG_ 1089 GE_Sumpftemperatur "Getriebesumpftemperatur wird über den Temperatursensor auf der Getriebeplatine ermittelt. Die absolute Sumpftemperatur wird vom Motor empfangen, um entsprechende Kühlleistung für das Getriebe einzustellen.";
CM_ BO_ 158 "Motor - Getriebe - Schnittstelle auf CAN-Antrieb (PL72H)";
CM_ SG_ 158 Getriebe_Hybrid_01_CHK "Berechnung siehe Lastenheft 'Kommunikationsabsicherung für FlexRay und CAN'
Endwerte siehe 'Kommunikationsabsicherung für FlexRay und CAN / Anhang C: Tabelle S-PDU Kennungen'


";
CM_ SG_ 158 Getriebe_Hybrid_01_BZ "überlaufender 4bit Botschaftszaehler; wird in jeder Sendebotschaft inkrementiert";
CM_ SG_ 158 GE_HYB_Fehlerstatus "Hybrid-spezifische Fehlerstati
PQ3x: Fehlerstatus x1b signalisiert, dass der Druck zum Öffnen der K0 nicht ausreicht (nach Kl15 ein)
PL71: Fehlerstatus x1b signalisiert eine unzureichende Druckversorgung durch die EOP.
Fehlerstatus 1xb : Verhinderung u";
CM_ SG_ 158 GE_HYB_Freigabe_K0 "PQ3x: Bit ist Zwangsanforderung für Status der K0
0 = K0 auf
1 = K0 zu
PL72: Übergang von 0 nach 1 (bzw von 1 nach 0) ist Teil des Wiederstart- (Stop-) Handshakes
0 = Freigabe K0 öffnen
1 = Freigabe K0 schließen";
CM_ SG_ 158 GE_HYB_Freigabe_LL_Reg "GSG gibt hier die Aktivierung einer DZ-Regelung von VM und/oder EM frei. (Verhinderung Selbstbeschleuniger)";
CM_ SG_ 158 GE_HYB_Freig_sSchl_K0 "PL72 Hybrid: GSG zeigt an, dass K0 bei Wiederstart schnell geschlossen werden soll (Zweck: Verwendung des folgenden DZ-Sprunges zur Synchronisierung)";
CM_ SG_ 158 GE_HYB_Freig_VM_EM_Stop "Signalisiert Bereitschaft GSG, dass VM gestoppt werden darf (Soft Stop) oder dass EM gestoppt werden darf (Übergang EM-Fahren => EMFahrbereitschaft)";
CM_ SG_ 158 GE_HYB_Wiederstart "Getriebe zeigt an, ob Wiederstart aktiv ist.";
CM_ SG_ 158 GE_HYB_nK0 "Nur PQ3x Hybrid:
GSG teilt MSG mit, auf welcher DZ die EM nach schnellem Schließen der K0 und nach DZAngleichung durch das GSG landen wird.
Wenn Signal 'Wiederstart' nicht aktiv: EM-Drehzahl wird gespiegelt.
Wenn Signal 'Wiederstart' aktiv: DZ, auf der";
CM_ SG_ 158 GE_HYB_MomEingriff_EM "Nur PQ3x Hybrid: Direkter Eingriff des GSG auf EM.
Ist der Betrag des Absolutwertes des Eingriffsmomentes in Nm. Verwendet zur Dämpfung des Triebstranges nach Impulsstart, wenn VM-Momente noch ungenau sind.
E-Gas-Sicherheit: begrenzt auf 30 Nm, zusätzli";
CM_ SG_ 158 GE_HYB_VZ_MomEingriff_EM "PQ3x Hybrid:Vorzeichen für Getriebeeingriff auf EM (MomEingriff_EM)";
CM_ SG_ 158 GE_HYB_Sportfaktor "Sportlichkeitsfaktor Getriebe, zur Verwendung in der Hybrid-Fahrstrategie
0 = nicht sportlich
1..15 = sportlich";
CM_ SG_ 158 GE_HYB_VM_akt_halten "Im elektrischen Fahren/Tipp: Übergang von 0 auf 1 zeigt VM-Startanforderung des GSG an.
Empfehlung GSG an MSG, dass VM aktiv gehalten werden soll. Verwendbar z.B. bei den Funktionen 'fast off (Gang halten)' oder bei 'Rückschaltung bei Bremsen'.";
CM_ SG_ 158 GE_HYB_StartAnf "Auslösen des VM_Widerstart bei EM-Betrieb";
CM_ SG_ 158 GE_HYB_VM_Startkontr "Freigabe der Wiederstartkontrolle";
CM_ SG_ 158 GE_HYB_Filt_MomAufbau "Faktor, der im MSG zur Berechnung der Filterkonstanten für den Fahrerwunschmomentenaufbau im Impulsstart verwendet wird.";
CM_ SG_ 1720 KBI_Tankfuellstand_Prozent "Tankfüllstand in %";
CM_ SG_ 1720 KBI_Tankinhalt_hochaufl "angezeigter Tankinhalt hochauflösend zur Restreichweitenberechnung";
CM_ SG_ 1720 KBI_Nachtanken_erkannt "Statusinformation Nachtankmodus";
CM_ SG_ 1720 KBI_Reifenumfang "Mittlerer Radumfang aus der K-Zahl gerechnet in Millimeter.  Byte 2 Bit 5,4 reserviert, Byte 2 Bit 3..0 und Byte 1 Bit 7..0; Wertebereich 0..4096 mm
";
CM_ SG_ 128 Motor_01_CHK "Berechnung siehe Lastenheft 'Kommunikationsabsicherung für FlexRay und CAN'
Endwerte siehe 'Kommunikationsabsicherung für FlexRay und CAN / Anhang C: Tabelle S-PDU Kennungen'";
CM_ SG_ 128 MO_Mom_o_ex "Achtung:
Einheitenloser CAN-Wert.
Faktor in MO_Faktor_Momente in Motor_Code_01 beachten!

Indiziertes Motormoment ohne externe Eingriffe (ASR, MSR, Getriebe ...) aber inklusive integrierter GRA";
CM_ SG_ 128 MO_Mom_m_ex "Achtung:
Einheitenloser CAN-Wert.
Faktor in MO_Faktor_Momente in Motor_Code_01 beachten!

Indiziertes Motormoment, d.h. idealisiertes berechnetes Moment ohne mechanische Verluste, aber mit externen Eingriffen.";
CM_ SG_ 128 MO_Mom_Verlust "Achtung:
Einheitenloser CAN-Wert.
Faktor in MO_Faktor_Momente in Motor_Code_01 beachten!

Beinhaltet z.Zt. Reibung vom Motor und Klimakompressor, beim TDI z.T. auch die Generatorverluste";
CM_ SG_ 128 MO_Mom_Begrenzung "Achtung:
Einheitenloser CAN-Wert.
Faktor in MO_Faktor_Momente in Motor_Code_01 beachten!

Inneres maximal mögliches Moment bei einer Drehzahl (z.B. Rauchbegrenzung oder Fehlerfall)";
CM_ SG_ 128 MO_Mom_Fahrerwunsch "Achtung:
Einheitenloser CAN-Wert.
Faktor in MO_Faktor_Momente in Motor_Code_01 beachten!

Moment vor Filter, nutzbar zur Zug- / Schuberkennung beim Getriebe (beim Diesel identisch mit innerem Moment ohne externe Eingriffe)";
CM_ SG_ 128 MO_Kickdown "Es gilt: Signalspec MO_Kickdown v1.0";
CM_ SG_ 128 MO_KD_Fehler "Kundendienstfehlerspeicherbit";
CM_ SG_ 129 MO_StartStopp_Wiederstart "Motorwiederstart durch Start/Stopp-Koordinator";
CM_ SG_ 129 MO_StartStopp_Status "St/St-Koordinator Systemstatus
zu Wert=1: Fehlerstatus erkannt oder Sicherheitsabschaltung aktiv (zeitabh. Grösse 1. innerhalb von 500ms kein Verbau St/St-Funktion 2. Nach Ablauf der Zeit kein St/St im aktuellen Fahrzyklus)
Initialwert ab Matrix 5.2=2";
CM_ SG_ 129 MO_StartStopp_Motorstopp "Motor-Stopp durch Start/Stopp-Koordinator";
CM_ SG_ 129 MO_StartStopp_Fahrerwunsch "Fahreraktivität Start/Stop";
CM_ SG_ 129 Motor_02_CHK "Berechnung siehe Lastenheft 'Kommunikationsabsicherung für FlexRay und CAN'
Endwerte siehe 'Kommunikationsabsicherung für FlexRay und CAN / Anhang C: Tabelle S-PDU Kennungen'";
CM_ SG_ 129 MO_Mom_ZWR "Minimales Motormoment bei Zündwinkelrücknahme.

Achtung:
Einheitenloser CAN-Wert.
Faktor in MO_Faktor_Momente in Motor_Code_01 beachten!";
CM_ SG_ 129 MO_Mom_Soll "Achtung:
Einheitenloser CAN-Wert.
Faktor in MO_Faktor_Momente in Motor_Code_01 beachten!

Sollmoment ohne P und D Anteil des Leerlaufreglers, ohne Antiruckelfunktion und ohne Getriebeeingriff";
CM_ SG_ 129 MO_Mom_Ist "Achtung:
Einheitenloser CAN-Wert.
Faktor in MO_Faktor_Momente in Motor_Code_01 beachten!

Istmoment ohne P und D Anteil des Leerlaufreglers, ohne Antiruckelfunktion und ohne Getriebeeingriff";
CM_ SG_ 129 MO_Status_Zylabschalt_01 "Statusbit: Motor ist in Zylinderabschaltregelung";
CM_ SG_ 129 MO_Status_Normalbetrieb_01 "Das Motorsteuergerät sendet das Informationsbit, wenn die Initialisierungsphase des Steuergerätes abgeschlossen ist. Zusätzlich muss die Klemme 15 eingeschalten sein und eine applizierbare Mindestdrehzahlschwelle (Kennlinie in Abh. von der Kühlwassertempe";
CM_ SG_ 129 MO_Momentenintegral "100 %  entspricht volle Verfügbarkeit aktuell vorhanden. 0 % entspricht Integral bis Limit gefüllt, erhöhender Eingriff kann aktuell nicht berücksichtigt werden oder erhöhender Eingriff ist in diesem Projekt nicht möglich (applikativ deaktiviert) oder auf";
CM_ SG_ 129 MO_Gangposition "Stellung des Wählhebels in der Schaltgasse des Handschaltgetriebes.
(Signal wird im Panamera nicht bedient)";
CM_ SG_ 129 MO_Ext_E_Fahrt_aktiv "Rückmeldung E-Taster (Hybrid-Signal, wird im E2H in der Motor_K_02 gesendet.)
(Signal wird nur im Panamera Hybrid bedient)";
CM_ BO_ 261 "Motor_03:

Im B8/Q5: 20ms

sonst: 10ms";
CM_ SG_ 261 MO_QBit_Motormomente "AUDI D4: Zykluszeit: 10ms (siehe Zykluszeit schnell/Cycletime Fast)

Ungenaue Momentenangaben, weil die Momente aus Ersatzwerten berechnet wurden (z.B. HFM ausgefallen). Qualifizierungsbit für die Motormomente.

Achtung:
Reduktion der Zykluszeit Moto";
CM_ SG_ 261 Motor_03_CHK "Berechnung siehe Lastenheft 'Kommunikationsabsicherung für FlexRay und CAN'
Endwerte siehe 'Kommunikationsabsicherung für FlexRay und CAN / Anhang C: Tabelle S-PDU Kennungen'";
CM_ SG_ 261 Motor_03_BZ "AUDI D4: Zykluszeit: 10ms (siehe Zykluszeit schnell/Cycletime Fast)

Achtung:
Reduktion der Zykluszeit Motor_03 auf 10ms geplant.
Projektabhängig soll künftig mit 10ms gesendet werden.
Empfänger die in weiteren Konzern-Projekten eingesetzt werden müs";
CM_ SG_ 261 MO_QBit_Fahrpedalwerte_01 "AUDI D4: Zykluszeit: 10ms (siehe Zykluszeit schnell/Cycletime Fast)

QBit für beide Fahrpedalwerte des Motors (Fahrpedalrohsignal für ESP, EPB, ACC; Fahrpedalwert für Getriebe)

Achtung:
Reduktion der Zykluszeit Motor_03 auf 10ms geplant.
Projektabh";
CM_ SG_ 261 MO_QBit_Fahrer_bremst "AUDI D4: Zykluszeit: 10ms (siehe Zykluszeit schnell/Cycletime Fast)

Achtung:
Reduktion der Zykluszeit Motor_03 auf 10ms geplant.
Projektabhängig soll künftig mit 10ms gesendet werden.
Empfänger die in weiteren Konzern-Projekten eingesetzt werden müs";
CM_ SG_ 261 MO_QBit_Drehzahl_01 "AUDI D4: Zykluszeit: 10ms (siehe Zykluszeit schnell/Cycletime Fast)

Achtung:
Reduktion der Zykluszeit Motor_03 auf 10ms geplant.
Projektabhängig soll künftig mit 10ms gesendet werden.
Empfänger die in weiteren Konzern-Projekten eingesetzt werden müs";
CM_ SG_ 261 MO_Drehzahl_01 "AUDI D4: Zykluszeit: 10ms (siehe Zykluszeit schnell/Cycletime Fast)

Im Fehlerfall wird die Motordrehzahl über die Nockenwellendrehzahl als Ersatzgrösse ausgegeben

Achtung:
Reduktion der Zykluszeit Motor_03 auf 10ms geplant.
Projektabhängig soll kü";
CM_ SG_ 261 MO_Moment_im_Leerlauf "AUDI D4: Zykluszeit: 10ms (siehe Zykluszeit schnell/Cycletime Fast)

Achtung:
Einheitenloser CAN-Wert.
Faktor in MO_Faktor_Momente in Motor_Code_01 beachten!

Motorbetriebszustand ist Leerlauf, keine Momentenerhöhung durch Fahrpedal, ACC, GRA+

Ac";
CM_ SG_ 261 MO_Interlock "Das Motorsteuergerät gibt die Information aus, ab wann der Kupplungsschalter durch das Motorsteuergerät als getreten gesehen wird.
Bei Systemen für Start Stopp muss das Interlocksignal für einen Start durch das MSG generiert werden, sobald der Schalthebe";
CM_ SG_ 261 MO_BLS "AUDI D4: Zykluszeit: 10ms (siehe Zykluszeit schnell/Cycletime Fast)

Ungefiltertes Rohsignal des Bremslichtschalters, nur wenn HW-Eingang bestückt und ausgewertet wird. Bei Motoren ohne genutzten HW-Eingang wird kein Ersatzwert (bspw. SW-Signal über CAN";
CM_ SG_ 261 MO_Fahrer_bremst "Redundante Bremsinformation vom Motor. Im B8 wird in diesem Bit der Wert der ESP-CAN-Information 'ESP_Fahrer_bremst' ausgegeben.
Achtung:
Reduktion der Zykluszeit Motor_03 auf 10ms
(in Gateway_01_VW: Signal wird nur im Panamera H/P bedient)";
CM_ SG_ 261 MO_Konsistenz_Bremsped "AUDI D4: Zykluszeit: 10ms (siehe Zykluszeit schnell/Cycletime Fast)

Siehe 'Funktionsspezifikation Bremslichtinfo B8'

Achtung:
Reduktion der Zykluszeit Motor_03 auf 10ms geplant.
Projektabhängig soll künftig mit 10ms gesendet werden.
Empfänger die";
CM_ SG_ 261 MO_Kuppl_schalter "AUDI D4: Zykluszeit: 10ms (siehe Zykluszeit schnell/Cycletime Fast)

Nur Handschalter; aktiv, wenn Schalter verbaut; sonst konstant auf '0' gesetzt; Bit wird gesetzt, wenn Kupplungspedal betätigt wird (Kupplungsschalter hoch), Triebstrang kann noch eing";
CM_ SG_ 261 MO_Timeout_ESP "AUDI D4: Zykluszeit: 10ms (siehe Zykluszeit schnell/Cycletime Fast)

500 ms Timeout auf Bremsen-Botschaft ist >= 1 mal aufgelaufen, Löschen des Bits nach Neustart (KL15).

Achtung:
Reduktion der Zykluszeit Motor_03 auf 10ms geplant.
Projektabhängig ";
CM_ SG_ 261 MO_Motor_laeuft "AUDI D4: Zykluszeit: 10ms (siehe Zykluszeit schnell/Cycletime Fast)

Es gilt: Signalspec MO_Motor_laeuft v1.0

Dieses Bit signalisiert, dass der Motor autark läuft und mechanisch belastbar ist. Das Bit wird abhängig von den Umgebungsbedingungen gesetz";
CM_ SG_ 261 MO_Solldrehz_Leerlauf "AUDI D4: Zykluszeit: 10ms (siehe Zykluszeit schnell/Cycletime Fast)

Leerlaufsolldrehzahl, die im Motor eingestellt ist. Der Motor paßt aufgrund der Anforderung von anderen
Steuergeräten seine Leerlaufsolldrehzahl an, bspw. Kat-Heizen, Anforderung vom ";
CM_ SG_ 261 MO_Fahrpedalrohwert_01 "AUDI D4: Zykluszeit: 10ms (siehe Zykluszeit schnell/Cycletime Fast)

Stellung des Fahrpedales (Rohwert, ohne Überlagerung durch GRA-Eingriffe etc.)

Die Funktionen zur Berechung des Fahrpedalrohwerts laufen im 10ms Raster. Der Fahrpedalwert berechnet ";
CM_ SG_ 261 MO_erste_Ungenauschwelle "AUDI D4: Zykluszeit: 10ms (siehe Zykluszeit schnell/Cycletime Fast)

Zusätzliche Ungenauigkeit (zur Grundungenauigkeit). Motormomente ungenau >8% (kleinste Ungenauschwelle)

Achtung:
Reduktion der Zykluszeit Motor_03 auf 10ms geplant.
Projektabhängi";
CM_ SG_ 261 MO_QBit_Stressfaktor "AUDI D4: Zykluszeit: 10ms (siehe Zykluszeit schnell/Cycletime Fast)

Achtung:
Reduktion der Zykluszeit Motor_03 auf 10ms geplant.
Projektabhängig soll künftig mit 10ms gesendet werden.
Empfänger die in weiteren Konzern-Projekten eingesetzt werden müs";
CM_ SG_ 261 MO_Stressfaktor "AUDI D4: Zykluszeit: 10ms (siehe Zykluszeit schnell/Cycletime Fast)

Berücksichtigung von Höhe und Ansauglufttemperatur im aktuellen Betriebspunkt. Berücksichtigung bei Berechnung der ACC-Sollbeschleunigung. Fehlerwert existiert nicht, 0x3F ist gültiger";
CM_ SG_ 263 MO_Anzeigedrehz "Ausgabe einer gefilterten Anzeigendrehzahl während des Starts für die Ausgabe im Drehzahlmesser des Kombiinstruments.";
CM_ SG_ 263 MO_KVS "Motorsteuergerätinterner Verbrauchszähler, der vom Kombi zyklisch ausgelesen wird, um die Einspritzmenge zur Verbrauchsmessung aufzusummieren; aus diesem Zählerstand werden Momentan- und Durchschnittsverbrauch berechnet; das Überlauf-Bit ist zu berücksich";
CM_ SG_ 263 MO_KVS_Ueberlauf "Der motorsteuergeräteinterne Verbrauchszähler ist mindestens einmal übergelaufen. Dieses Bit wird genutzt, um erkennen zu können, daß das Motorsteuergerät aus dem Reset-Zustand hochläuft.";
CM_ SG_ 263 MO_Ladedruck "Zur Anzeige im Kombi, z.Zt. nur Porsche Colorado und PQ35 Biturbo, ab B8 Vorhalt";
CM_ SG_ 263 MO_Oeldruck_HYB "Öldruck analog zur Anzeige
(Signal wird im Panamera nicht bedient)";
CM_ SG_ 263 MO_Istgang "Wenn Motor die WBA-Botschaft sendet wird in diesem Signal der aktuelle Gang ausgegeben (= Istgang des Schaltgetriebes). Nur falls WBA_Senderkennung = 01 (MSG).
(Signal wird im Panamera nicht bedient)";
CM_ SG_ 263 MO_Schaltempf_verfbar "Info, ob Schaltempfehlung im Fzg. verfügbar. Statischer Wert, ändert sich für ein Fzg nicht - nur falls WBA_Senderkennung = 01 (MSG)
(Signal wird im Panamera nicht bedient)";
CM_ SG_ 263 MO_Sollgang "Motor sendet den Sollgang in den der Fahrer schalten soll. Wird im Kombi als Hochschaltempfehlung hervorgehoben. Nur falls WBA_Senderkennung = 01 (MSG)
(Signal wird im Panamera nicht bedient)";
CM_ SG_ 782 MO_Handshake_STH "Es gilt: Signalspec MO_Handshake v1.0

Handshake zwischen MSG und STH. Wenn das MSG die EKP aufgrund einer STH-Anforderung ansteuert und kein Fehlereintrag bzgl. EKP/KPE/NDR vorliegt, wird das Bit gesetzt.";
CM_ SG_ 782 Motor_05_CHK "Berechnung siehe Lastenheft 'Kommunikationsabsicherung für FlexRay und CAN'
Endwerte siehe 'Kommunikationsabsicherung für FlexRay und CAN / Anhang C: Tabelle S-PDU Kennungen'";
CM_ SG_ 782 MO_EKlKomLeiRed "Anforderung an die Klimasteuerung, die Leistungsaufnahme des E-Kompressors bei schlechtem SOC und in bestimmten Fahrsituationen zu begrenzen...
(Signal wird nur im Hybrid bedient)";
CM_ SG_ 782 MO_Freig_Reku "Empfehlung des Motor-SG's zur Spannungsabsenkung/-anhebung für den Rekuperationsbetrieb";
CM_ SG_ 782 MO_Klima_Eingr "Eingriffe des Motor bei der Klima";
CM_ SG_ 782 MO_Status_Normalbetrieb_02 "Signal ausschließlich für AUDI B8.
Auch im B8 nur GSG Empfänger dieses Signales.
Alle weiteren Fahrzeuge verwenden das Signal in Motor_02.
(Signal wird im Panamera nicht bedient)";
CM_ SG_ 782 MO_Schaltbeeinfl_Leistungsbegr "Schaltbeeinflussung an das Getriebe wegen Leistungsbegrenzung";
CM_ SG_ 782 MO_Schaltbeeinfl_Partikelfilter "Schaltbeeinflussung an das Getriebe wegen Partikelfilter-Regeneration
(Signal wird nur im Panamera Pirol bedient)
";
CM_ SG_ 782 MO_Prio_MIN_Wunschdrehzahl "Motorwunschdrehzahl ist als Zwang oder als Wunsch an das Getriebe zu interpretieren";
CM_ SG_ 782 MO_Freig_Anlass "Bit wird gesetzt, wenn der Motor beim Automatikstart gestartet werden darf (Motorstillstand, Emissionsmaßnahmen sind erfüllt).";
CM_ SG_ 782 MO_Aussp_Anlass "Bit wird gesetzt, wenn der Motorhochlauf ohne Anlasserunterstützung beendet werden kann oder ein Start-Timeout erreicht wurde.
(in Gateway_01_VW: Signal wird nur im Panamera H/P bedient)";
CM_ SG_ 782 MO_MAX_Wunschdrehzahl "Wenn das Bit 'MO_Prio_MAX_Wunschdrehzahl' gesetzt wird, wird hier vom Motor-SG eine wegen Partikelfilterregeneration bedingte minimale Motordrehzahl ausgegeben, die das Getriebe-SG nicht unterschreiten darf...
(Signal wird nur im Panamera Pirol bedient)";
CM_ SG_ 782 MO_Prio_MAX_Wunschdrehzahl "Motorwunschdrehzahl in Byte 4 ist als Zwang oder als Wunsch an das Getriebe zu interpretieren
(Signal wird nur im Panamera Pirol bedient)";
CM_ SG_ 782 MO_Luftpfad_aktiv "Getriebeeingriff wird zusätzlich zum Zündungspfad auch über den Luftpfad umgesetzt, kommt zu B8 neu in die PL48-Getriebe";
CM_ SG_ 782 MO_v_Begrenz_Aktiv "Motor begrenzt aktuell die Geschwindigkeit des Fahrzeugs; Reaktion auf externe oder interne Anforderung
(Signal wird im Panamera nicht bedient)";
CM_ SG_ 782 MO_v_Begrenz_Aktivierbar "Fehlerbit wird vom Motor-SG gesetzt, wenn dieses nicht in dieGeschwindigkeits-begrenzung gehen kann, ein Fehler während der v-Begrenzung auftritt oder v > v_Begrenzung - v_Delta";
CM_ SG_ 782 MO_Verbot_EKP "Es gilt: Signalspec MO_Verbot_EKP V1.1
MSG sendet Verbot der EKP-Ansteuerung an das BCM
(Signal wird im Panamera nicht bedient)";
CM_ SG_ 782 MO_Anf_Pruefimpuls "Es gilt: Signalspec MO_Anf_Pruefimpuls v1.1
Anforderung des MSG an das BCM  zum Senden eines Prüfimpulses zur Diagnose der Wakeup-Leitung auf Dauerlow
(Signal wird im Panamera nicht bedient)";
CM_ SG_ 782 MO_Anf_KL75 "Information wann die Kl. 75 während des Startvorgangs abgeschaltet werden soll. Umsetzung durch BCM2.";
CM_ SG_ 782 MO_Charisma_FahrPr "Aktuelles Fahrprogramm des Charisma-Teilnehmers

Achtung neue Modusnamen (wie im MMI):

0x1 = Komfort = Comfort
0x2 = Dynamik = Auto
0x3 = Sport = Dynamic";
CM_ SG_ 782 MO_Charisma_Status "Charisma Systemstatus des Charisma-Teilnehmers";
CM_ SG_ 782 MO_Charisma_Umschaltung "Erkennung  Umschaltaufforderung des Charisma-Teilnehmers";
CM_ SG_ 782 MO_MIN_Wunschdrehzahl "Wenn das Bit 'MO_Prio_MIN_Wunschdrehzahl' gesetzt wird, wird vom Motor-SG wegen Partikelfilterregeneration wird eine minimale Motordrehzahl ausgegeben, die das Getriebe-SG nicht unterschreiten darf.
(Signal wird nur im Panamera Pirol bedient)";
CM_ SG_ 782 MO_Drehzahlbeeinflussung "Mit diesem Faktor kann das Motorsteuergerät die vom CVT-Getriebe einzustellende Sollmotodrehzahl beeinflussen. Im CVT-Steuergerät ist ein verbrauchsoptimales Kennfeld und ein abgasoptimiertes Kennfeld abgelegt. Mit dem Wert von 0-100% wird zwischen diesen";
CM_ BO_ 1088 "Botschaft von MED17 (G1Hybrid)";
CM_ SG_ 1088 MO_Kat_Warnung "Das Signal lässt im Kombi des LB83x eine Warnlampe angehen um eine Überhitzung des Katalysators zu signalisieren
(Signal wird im Panamera nicht bedient)";
CM_ SG_ 1088 MO_ITM_Warnung_Pumpe "Textanzeige: 'Motor sofort abstellen, geschaltete Wasserpumpe defekt / klemmt'";
CM_ SG_ 1088 MO_HYB_Text_4 "Textanzeige: E-Mode unterbrochen (passiv)
(Signal wird nur im Panamera Hybrid bedient)";
CM_ SG_ 1088 MO_HYB_Status_HV_Ladung "Statusanzeige für Funktion HV-Ladung über 12V-Seite
(Signal wird im Panamera nicht bedient)";
CM_ SG_ 1088 MO_Zustand_HWP "Rückmeldung des  Ansteuerzustand der Hauptwasserpumpe an das Klima-SG .
Der Zustand 'HWP fördert' wird übermittelt, wenn die Schaufeln der Hauptwasserpumpe frei drehen können und die Motordrehzahl und damit die Wasserpumpendrehzahl größer als Null ist. B";
CM_ SG_ 1088 MO_Kuehlerluefter_MUX "Multiplexer für das Signal 'MO_Kuehlerlüfter'";
CM_ SG_ 1088 MO_Kuehlerluefter_1 "Ansteuertastverhaeltnis (PWM) der Kuehlerluefterendstufe 1";
CM_ SG_ 1088 MO_Kuehlerluefter_2 "Ansteuertastverhaeltnis (PWM) der Kuehlerluefterendstufe 2";
CM_ SG_ 1088 WIV_Anzeige_aktiv "Peilstabsanzeigefunktion aktiv";
CM_ SG_ 1088 WIV_Oelmin_Warn "Min-Warnung";
CM_ SG_ 1088 WIV_Sensorfehler "Ölstand/Öltemperatursensor (TOG) defekt";
CM_ SG_ 1088 WIV_Schieflage "Fahrzeug steht nicht waagerecht, Messung ungenau";
CM_ SG_ 1088 WIV_Oelstand "8 Segmente zur Balkenanzeige des Ölstands";
CM_ SG_ 1088 WIV_Oelsystem_aktiv "Gesamtölsystem aktiv (entspricht Ölsensor verbaut)";
CM_ SG_ 1088 WIV_nicht_betriebswarm "Motor nicht betriebswarm, Messung ungenau";
CM_ SG_ 1088 WIV_Ueberfuell_Warn "Überfüllungswarnung";
CM_ SG_ 1088 WIV_laufender_Motor "Messung bei laufendem Motor nicht möglich";
CM_ SG_ 1088 MO_Text_Motorstart "Anzeigetexte für Start/Stopp und Motor-Start
";
CM_ SG_ 1088 MO_Text_MSG_Werkstatt "Über dieses Bit wird im Kombi ein Fehlerklartextanzeige erzeugt werden: 'Motorsteuergerät Werkstatt'.
(Signal wird im Panamera nicht bedient)
";
CM_ SG_ 1088 MO_Text_Partikelfil_Reg "Über dieses Bit im Kombi wird ein Klartextanzeige erzeugt werden: 'Partikelfilter benötigt Regeneration'.
(Signal wird nur im Panamera Pirol bedient)
";
CM_ SG_ 1088 MO_Text_Fehler_Kraftstoffsys "Über dieses Bit wird im Kombi ein Fehlerklartextanzeige erzeugt wird: 'Fehler im Kraftstoffsystem'.	
(Signal wird im Panamera nicht bedient)";
CM_ SG_ 1088 WIV_Oelmenge "Ölmenge zwischen Min und Max";
CM_ SG_ 1088 MO_Systemlampe "EGas Systemlampe (EPC) oder Vorglühlampe im Kombi, Kombi steuert immer gleiche
LED an, nur über Ziffernblatt wird die EPC von der Vorglühlampe differenziert";
CM_ SG_ 1088 MO_OBD2_Lampe "OBD bzw. MIL-Lampe wird vom Motorsteuergerät angesteuert, die Information in der Getriebe1 Botschaft (Byte 6, Bit 7...4) wird 
vom Motorsteuergerät an das Kombi weitergereicht";
CM_ SG_ 1088 MO_Heissleuchte "Ansteuerung der Kühlwassertemperatur-Heißleuchte (Sensor nur noch am Motorsteuergerät): Temperaturschaltschwellen mit Hysterese (bei VW D1/Colorado Kombi derzeit noch nicht genutzt).";
CM_ SG_ 1088 MO_Partikel_Lampe "Partikelfilter-Lampe wird eingeschaltet
(Signal wird nur im Panamera Pirol bedient)";
CM_ SG_ 1088 WIV_Oelstand_nicht_vorhanden "Kein aktueller Ölstand vorhanden";
CM_ SG_ 1088 WIV_nachfuellanzeige_ein "Steuert das Aufblenden der Nachfüllanzeige im Kombi, nach Klemme 15 ein und geöffneter Motorhaube";
CM_ SG_ 1088 WIV_Ueberfuell_deaktiv "Anzeige 'Check Oil' im Kombiinstrument ohne Aufruf durch Kunden
Signalbezeichnung in NIP 5.0 'WIV_Check_Oil'

";
CM_ SG_ 1088 WIV_Unterfuell_Warn "Unterfüllungswarnung";
CM_ SG_ 1088 MO_Tankdeckel_Lampe "Ansteuerung Tankdeckel-Warnlampe Kombiinstrument (nur Ottomotoren) z.Zt. Vorhalt VW
(Signal wird nur im Panamera Hybrid bedient)";
CM_ SG_ 1088 MO_Text_Tankdeckelwarn "Textbit der Tankdeckelwarnung, z.Zt. Vorhalt VW
(Signal wird nur im Panamera Hybrid bedient)";
CM_ SG_ 1088 WIV_Enable_Oeldr_Motor "Schaltet die interne Öldruckauswertung im Kombiinstrument ab und aktiviert die Auswertung des Bits 'WIV_Oeldr_Warn_Motor'";
CM_ SG_ 1088 WIV_Oeldr_Warn_Motor "Löst im Kombiinstrument die rote Prio1-Öldruckwarnung (inkl. 3xBeep) aus; die Warnauslösung erfolgt nur bei gleichzeitig gesetztem 'WIV_Enable_Oeldr_Motor'";
CM_ SG_ 1088 MO_Avus_Motorschutz "Warntexten zum Kombi für den Fall des Avus-Notlauf. Priowarnung, kann parallel mit anderen Warnungen 
im Mitteldisplay angezeigt werden.";
CM_ SG_ 1088 MO_HYB_Fahrbereitschaft "Signal steuert u.a. in der Lenkhilfe zusammen mit weiteren Informationen den Modewechsel in den 'Drivemode'
Grüne Anzeige im Kombiinstrument zur Signalisierung der Bereitschaft des Hybridsystems.
(Signal wird nur im Panamera Hybrid bedient)";
CM_ SG_ 1088 WIV_Oeldyn_avl "Ölstand aus dynamischer Messung vorhanden
(Signal wird im Panamera nicht bedient)";
CM_ SG_ 1088 MO_HYB_Text_7 "Textanzeige: Traktionsbatterie wird geladen bitte Motor nicht abstellen
(Signal wird nur im Panamera Hybrid bedient)";
CM_ SG_ 1088 MO_HYB_Text_6 "Textanzeige: Elektrisches Fahren zur Zeit nicht möglich
(Signal wird nur im Panamera Hybrid bedient)";
CM_ SG_ 1088 MO_HYB_Text_5 "Textanzeige: Hybrid-Funktionen nicht verfügbar
(Signal wird nur im Panamera Hybrid bedient)";
CM_ SG_ 1088 MO_HYB_Text_3 "Textanzeige: Bitte Motor erneut Starten
(Signal wird nur im Panamera Hybrid bedient)";
CM_ SG_ 1088 MO_HYB_Text_2 "Textanzeige: Fehler Hybridystem
bitte Werkstatt aufsuchen
(Signal wird nur im Panamera Hybrid bedient)";
CM_ SG_ 1088 MO_HYB_Text_1 "Textanzeige: Fehler Hybridsystem
bitte Fahrzeug an sicherem Ort anhalten
(Signal wird nur im Panamera Hybrid bedient)";
CM_ SG_ 1600 MO_Nachlaufzeit_Heizungspumpe "Nachlaufzeit für Heizungspumpe für Turboladerschutz";
CM_ SG_ 1600 MO_Kennfeldk "Die Kennfeldkühlung ist in diesem Fahrzeug verbaut und hat keinen Systemfehler";
CM_ SG_ 1600 MO_QBit_Ansaugluft_Temp "
";
CM_ SG_ 1600 MO_QBit_Kuehlmittel_Temp "
";
CM_ SG_ 1600 MO_Stellgliedtest_Soundaktuator "Ansteuerung des Stellgliedtest
(Signal wird im Panamera nicht bedient)";
CM_ SG_ 1600 MO_HYB_Fehler_HV_Netz "Im HV-Bordnetz ist fehlerbedingt kein generatorischer Betrieb möglich. Das 12V-Bordnetz wird über den DC/DC-Wandler allein aus der Traktionsbatterie gespeist. Um diesen Zustand möglichst lange...
(Signal wird nur im Panamera Hybrid bedient)";
CM_ SG_ 1600 MO_Absperrventil_oeffnen "Signal an Klima-SG das Absperrrventil anzusteuern. Ab D4 auch 0x3 Ventil_schließen.";
CM_ SG_ 1600 MO_Ansaugluft_Temp "In Fahrzeugen ohne Außentemperatur vom Kombi kann aus der Ansauglufttemperatur auf die Außentemperatur geschlossen werden. Beim SDI ist das mit einer gewissen Genauigkeit gegeben. Genutzt wird es vom ASG.";
CM_ SG_ 1600 MO_Oel_Temp "Realer Meßbereich ca. -40..150 Grad";
CM_ SG_ 1600 MO_Kuehlmittel_Temp "Kuehlmitteltemperatur";
CM_ SG_ 1600 MO_Hoeheninfo "Korrekturfaktor Höhe (1 entspricht 1013 mbar)";
CM_ SG_ 1600 MO_Versionsinfo "Versioninformation vom Motor zur Steuerung bei inkompatiblen KMatrix-Änderung bzw. Einführung von neuen Funktionen, die in den Empfängern verriegelt werden müssen. Freilaufender Zähler, der nach Änderungsereignis festgelegt wird. Zu jedem Ereignis wird ei";
CM_ SG_ 1600 MO_Getriebe_kuehlen "Anforderung Getriebekühlventilansteuerung";
CM_ SG_ 1600 MO_Mom_Traegheit_02 "Massenträgheit des Motors (J) in kgm²
Bei Handschaltern wird das Zweimassenschwungrad mit berücksichtigt.
Bei eingebautem Getriebesteuergerät wird nur das Motorträgheitsmoment angegeben (Ohne Anteile des Massenschwungrades).";
CM_ SG_ 1600 MO_Heizungspumpenansteuerung "Anforderung Heizungspumpenansteuerung ";
CM_ SG_ 1600 MO_SpannungsAnf "Forderung des Motor-SGs zur Spannungsanhebung";
CM_ SG_ 1600 MO_aktives_Getriebeheizen "Information für Getriebe, ob ein Ventil für Getriebheizen angesteuert werden muss";
CM_ SG_ 1601 MO_Kraftstoffart "Kraftstoffart";
CM_ SG_ 1601 Motor_Code_01_CHK "Berechnung siehe Lastenheft 'Kommunikationsabsicherung für FlexRay und CAN'
Endwerte siehe 'Kommunikationsabsicherung für FlexRay und CAN / Anhang C: Tabelle S-PDU Kennungen'


";
CM_ SG_ 1601 MO_Faktor_Momente "Dieses Bit schaltet den Wertebereich aller Momente vom Motor, Getriebe, TSK, ESP ... um! Die Momente besitzen somit einen variablen Wertebereich, weil sich durch den Faktor die Momente sowohl in Auflösung als auch Maximalwerten ändert.

Defaultwert ist ";
CM_ SG_ 1601 MO_Hybridfahrzeug "Anhand dieses Signals plausibilisiert die Lenkhilfe das Bit Fahrbereitschaft
(Signal wird nur im Panamera Hybrid bedient)";
CM_ SG_ 1601 MO_Code "Motorcodierinformation für Getriebe. Überwachung auf Falschverbau.






";
CM_ SG_ 1601 MO_Getriebe_Code "Getriebecodierung des Motors 

0x0 - 0x1 = tbd. 
0x3 = tbd. 
0x5 - 0x9 = tbd. 
0xB - 0xE = tbd.
0x10 - 3F =tbd.";
CM_ SG_ 1601 MO_Abgastyp "Bit 0:

0x0 = kein EOBD
0x1 = EOBD

Bit 1:

0x0 = kein OBD (US-Norm)
0x1 = OBD (US-Norm)

0x4 -0x3f=tdb. 
";
CM_ SG_ 1601 MO_StartStopp_Codiert "Funktion 'StartStopp' im aktuellen Klemmenzyklus verbaut
(entspricht Status LV_VAR_STST)";
BA_DEF_ SG_  "DERIVATE_Pruefung" ENUM  "offen","geprüft";
BA_DEF_ SG_  "HYB_Rx_Baureihe" ENUM  "G1+Derivate","nur G1","nur Derivate";
BA_DEF_ SG_  "HYB_Rx_Verwendung" ENUM  "DERIV_Rout","DERIV_Calc","DERIV_Rout+DERIV_Calc";
BA_DEF_ SG_  "GenSigSwitchedByIgnition" ENUM  "No","Yes";
BA_DEF_ SG_  "GenSigEnvVarType" ENUM  "int","float","undef";
BA_DEF_ SG_  "GenSigAutoGenSnd" ENUM  "No","Yes";
BA_DEF_ SG_  "GenSigAutoGenDsp" ENUM  "No","Yes";
BA_DEF_ SG_  "GenSigActiveRepetitions" INT -2147483648 2147483647;
BA_DEF_ SG_  "GenSigFuncType" ENUM  "NoFunction","MsgCounter","CRC-8","XOR","XOR-2","DatedBit","SW-Kl15","CHK","Constant","Protocol";
BA_DEF_ SG_  "Info_BCM_HutHut_Kommunikation" ENUM  "Nein","Ja";
BA_DEF_ SG_  "NWM-WakeupAllowed" ENUM  "No","Yes";
BA_DEF_ SG_  "GenSigInactiveValue" STRING ;
BA_DEF_ SG_  "GenSigMissingSourceValue" INT 0 2147483647;
BA_DEF_ SG_  "GenSigStartValue" INT 0 0;
BA_DEF_ SG_  "Fehlerwert" HEX 0 2147483647;
BA_DEF_ SG_  "Bemerkung" STRING ;
BA_DEF_ SG_  "GenSigSendType" ENUM  "Cyclic","OnWrite","OnWriteWithRepetition","OnChange","OnChangeWithRepetition","IfActive","IfActiveWithRepetition","NoSigSendType";
BA_DEF_ BO_  "NmMessage" ENUM  "No","Yes";
BA_DEF_ BO_  "GenMsgAutoGenSnd" ENUM  "No","Yes";
BA_DEF_ BO_  "GenMsgAutoGenDsp" ENUM  "No","Yes";
BA_DEF_ BO_  "MsgType" ENUM  "Broadcast","Event","NM ","NMH","TP2.0","ISO-TP ","BAP","EID";
BA_DEF_ BO_  "GenMsgChkConstant" HEX 0 4095;
BA_DEF_ BO_  "sim_GenMsgILSupport" ENUM  "No","Yes";
BA_DEF_ BO_  "NWM-Botschaft" ENUM  "No","Yes";
BA_DEF_ BO_  "VAGTP20_StatConnection" ENUM  "No","Yes";
BA_DEF_ BO_  "VAGTP20_DynSetup" ENUM  "No","Yes";
BA_DEF_ BO_  "VAGTP20_DynConnection" ENUM  "No","Yes";
BA_DEF_ BO_  "VAGTP20_API" HEX 0 255;
BA_DEF_ BO_  "Direkt_1zu1" ENUM  "Nein","Ja";
BA_DEF_ BO_  "GenMsgSendType" ENUM  "Cyclic","NotUsed","NotUsed","NotUsed","NotUsed","NotUsed","NotUsed","IfActive","NoMsgSendType","NotUsed";
BA_DEF_ BO_  "DiagResponse" ENUM  "No","Yes";
BA_DEF_ BO_  "DiagRequest" ENUM  "No","Yes";
BA_DEF_ BO_  "GenMsgDelayTime" INT 0 65535;
BA_DEF_ BO_  "GenMsgStartDelayTime" INT 0 65535;
BA_DEF_ BO_  "GenMsgILSupport" ENUM  "No","Yes";
BA_DEF_ BO_  "NmhMessage" ENUM  "No","Yes";
BA_DEF_ BO_  "GenMsgNrOfRepetition" INT 0 65535;
BA_DEF_ BO_  "GenMsgCycleTimeFast" INT 0 65535;
BA_DEF_ BO_  "DiagState" ENUM  "No","Yes";
BA_DEF_ BO_  "GenMsgCycleTime" INT 0 65535;
BA_DEF_REL_ BU_BO_REL_  "HYB_Tx_Verwendung" ENUM  "Rout","Calc";
BA_DEF_REL_ BU_BO_REL_  "HYB_Tx_Baureihe" ENUM  "G1+Derivate","G1","Derivate","vector_leerstring";
BA_DEF_REL_ BU_SG_REL_  "GenSigTimeoutTime" INT 0 65535;
BA_DEF_DEF_REL_ "HYB_Tx_Verwendung" "Rout";
BA_DEF_DEF_REL_ "HYB_Tx_Baureihe" "G1+Derivate";
BA_DEF_DEF_  "DERIVATE_Pruefung" "offen";
BA_DEF_DEF_  "HYB_Rx_Baureihe" "G1+Derivate";
BA_DEF_DEF_  "HYB_Rx_Verwendung" "DERIV_Rout";
BA_DEF_DEF_  "GenSigSwitchedByIgnition" "No";
BA_DEF_DEF_  "GenSigEnvVarType" "undef";
BA_DEF_DEF_  "GenSigAutoGenSnd" "No";
BA_DEF_DEF_  "GenSigAutoGenDsp" "No";
BA_DEF_DEF_  "GenSigActiveRepetitions" 0;
BA_DEF_DEF_  "GenSigFuncType" "NoFunction";
BA_DEF_DEF_  "Info_BCM_HutHut_Kommunikation" "Nein";
BA_DEF_DEF_  "NWM-WakeupAllowed" "Yes";
BA_DEF_DEF_  "GenSigInactiveValue" "0";
BA_DEF_DEF_  "GenSigMissingSourceValue" 0;
BA_DEF_DEF_  "GenSigStartValue" 0;
BA_DEF_DEF_  "Fehlerwert" 0;
BA_DEF_DEF_  "Bemerkung" "";
BA_DEF_DEF_  "GenSigSendType" "Cyclic";
BA_DEF_DEF_  "NmMessage" "No";
BA_DEF_DEF_  "GenMsgAutoGenSnd" "Yes";
BA_DEF_DEF_  "GenMsgAutoGenDsp" "Yes";
BA_DEF_DEF_  "MsgType" "Broadcast";
BA_DEF_DEF_  "GenMsgChkConstant" 0;
BA_DEF_DEF_  "sim_GenMsgILSupport" "No";
BA_DEF_DEF_  "NWM-Botschaft" "No";
BA_DEF_DEF_  "VAGTP20_StatConnection" "No";
BA_DEF_DEF_  "VAGTP20_DynSetup" "No";
BA_DEF_DEF_  "VAGTP20_DynConnection" "No";
BA_DEF_DEF_  "VAGTP20_API" 1;
BA_DEF_DEF_  "Direkt_1zu1" "Nein";
BA_DEF_DEF_  "GenMsgSendType" "Cyclic";
BA_DEF_DEF_  "DiagResponse" "No";
BA_DEF_DEF_  "DiagRequest" "No";
BA_DEF_DEF_  "GenMsgDelayTime" 0;
BA_DEF_DEF_  "GenMsgStartDelayTime" 0;
BA_DEF_DEF_  "GenMsgILSupport" "No";
BA_DEF_DEF_  "NmhMessage" "No";
BA_DEF_DEF_  "GenMsgNrOfRepetition" 0;
BA_DEF_DEF_  "GenMsgCycleTimeFast" 0;
BA_DEF_DEF_  "DiagState" "No";
BA_DEF_DEF_  "GenMsgCycleTime" 0;
BA_DEF_DEF_REL_ "GenSigTimeoutTime" 0;
BA_ "GenMsgChkConstant" BO_ 262 7;
BA_ "sim_GenMsgILSupport" BO_ 262 1;
BA_ "VAGTP20_API" BO_ 262 0;
BA_ "Direkt_1zu1" BO_ 262 1;
BA_ "GenMsgILSupport" BO_ 262 1;
BA_ "GenMsgCycleTime" BO_ 262 20;
BA_ "GenMsgChkConstant" BO_ 793 26;
BA_ "VAGTP20_API" BO_ 793 0;
BA_ "Direkt_1zu1" BO_ 793 1;
BA_ "GenMsgILSupport" BO_ 793 1;
BA_ "GenMsgCycleTime" BO_ 793 40;
BA_ "VAGTP20_API" BO_ 924 0;
BA_ "GenMsgDelayTime" BO_ 924 10;
BA_ "GenMsgILSupport" BO_ 924 1;
BA_ "GenMsgCycleTime" BO_ 924 100;
BA_ "VAGTP20_API" BO_ 1604 0;
BA_ "GenMsgDelayTime" BO_ 1604 50;
BA_ "GenMsgILSupport" BO_ 1604 1;
BA_ "GenMsgCycleTime" BO_ 1604 500;
BA_ "GenMsgChkConstant" BO_ 130 130;
BA_ "sim_GenMsgILSupport" BO_ 130 1;
BA_ "VAGTP20_API" BO_ 130 0;
BA_ "Direkt_1zu1" BO_ 130 1;
BA_ "GenMsgILSupport" BO_ 130 1;
BA_ "GenMsgCycleTime" BO_ 130 10;
BA_ "GenMsgChkConstant" BO_ 131 131;
BA_ "sim_GenMsgILSupport" BO_ 131 1;
BA_ "VAGTP20_API" BO_ 131 0;
BA_ "Direkt_1zu1" BO_ 131 1;
BA_ "GenMsgILSupport" BO_ 131 1;
BA_ "GenMsgCycleTime" BO_ 131 10;
BA_ "GenMsgChkConstant" BO_ 258 3;
BA_ "sim_GenMsgILSupport" BO_ 258 1;
BA_ "VAGTP20_API" BO_ 258 0;
BA_ "Direkt_1zu1" BO_ 258 1;
BA_ "GenMsgILSupport" BO_ 258 1;
BA_ "GenMsgCycleTime" BO_ 258 20;
BA_ "sim_GenMsgILSupport" BO_ 1089 1;
BA_ "VAGTP20_API" BO_ 1089 0;
BA_ "GenMsgILSupport" BO_ 1089 1;
BA_ "GenMsgCycleTime" BO_ 1089 100;
BA_ "GenMsgChkConstant" BO_ 158 158;
BA_ "sim_GenMsgILSupport" BO_ 158 1;
BA_ "VAGTP20_API" BO_ 158 0;
BA_ "Direkt_1zu1" BO_ 158 1;
BA_ "GenMsgILSupport" BO_ 158 1;
BA_ "GenMsgCycleTime" BO_ 158 20;
BA_ "MsgType" BO_ 2022 5;
BA_ "VAGTP20_API" BO_ 2022 0;
BA_ "Direkt_1zu1" BO_ 2022 1;
BA_ "GenMsgSendType" BO_ 2022 8;
BA_ "DiagRequest" BO_ 2022 1;
BA_ "MsgType" BO_ 2030 5;
BA_ "VAGTP20_API" BO_ 2030 0;
BA_ "Direkt_1zu1" BO_ 2030 1;
BA_ "GenMsgSendType" BO_ 2030 8;
BA_ "DiagResponse" BO_ 2030 1;
BA_ "MsgType" BO_ 2021 5;
BA_ "VAGTP20_API" BO_ 2021 0;
BA_ "Direkt_1zu1" BO_ 2021 1;
BA_ "GenMsgSendType" BO_ 2021 8;
BA_ "DiagRequest" BO_ 2021 1;
BA_ "MsgType" BO_ 2029 5;
BA_ "VAGTP20_API" BO_ 2029 0;
BA_ "Direkt_1zu1" BO_ 2029 1;
BA_ "GenMsgSendType" BO_ 2029 8;
BA_ "DiagResponse" BO_ 2029 1;
BA_ "VAGTP20_API" BO_ 1720 0;
BA_ "GenMsgILSupport" BO_ 1720 1;
BA_ "GenMsgCycleTime" BO_ 1720 1000;
BA_ "GenMsgChkConstant" BO_ 128 128;
BA_ "sim_GenMsgILSupport" BO_ 128 1;
BA_ "VAGTP20_API" BO_ 128 0;
BA_ "Direkt_1zu1" BO_ 128 1;
BA_ "GenMsgILSupport" BO_ 128 1;
BA_ "GenMsgCycleTime" BO_ 128 10;
BA_ "GenMsgChkConstant" BO_ 129 129;
BA_ "sim_GenMsgILSupport" BO_ 129 1;
BA_ "VAGTP20_API" BO_ 129 0;
BA_ "Direkt_1zu1" BO_ 129 1;
BA_ "GenMsgILSupport" BO_ 129 1;
BA_ "GenMsgCycleTime" BO_ 129 10;
BA_ "GenMsgChkConstant" BO_ 261 4;
BA_ "sim_GenMsgILSupport" BO_ 261 1;
BA_ "VAGTP20_API" BO_ 261 0;
BA_ "Direkt_1zu1" BO_ 261 1;
BA_ "GenMsgILSupport" BO_ 261 1;
BA_ "GenMsgCycleTime" BO_ 261 10;
BA_ "sim_GenMsgILSupport" BO_ 263 1;
BA_ "VAGTP20_API" BO_ 263 0;
BA_ "GenMsgILSupport" BO_ 263 1;
BA_ "GenMsgCycleTime" BO_ 263 20;
BA_ "GenMsgChkConstant" BO_ 782 13;
BA_ "sim_GenMsgILSupport" BO_ 782 1;
BA_ "VAGTP20_API" BO_ 782 0;
BA_ "Direkt_1zu1" BO_ 782 1;
BA_ "GenMsgILSupport" BO_ 782 1;
BA_ "GenMsgCycleTime" BO_ 782 50;
BA_ "sim_GenMsgILSupport" BO_ 1088 1;
BA_ "VAGTP20_API" BO_ 1088 0;
BA_ "GenMsgILSupport" BO_ 1088 1;
BA_ "GenMsgCycleTime" BO_ 1088 100;
BA_ "sim_GenMsgILSupport" BO_ 1600 1;
BA_ "VAGTP20_API" BO_ 1600 0;
BA_ "GenMsgILSupport" BO_ 1600 1;
BA_ "GenMsgCycleTime" BO_ 1600 500;
BA_ "GenMsgChkConstant" BO_ 1601 71;
BA_ "sim_GenMsgILSupport" BO_ 1601 1;
BA_ "VAGTP20_API" BO_ 1601 0;
BA_ "Direkt_1zu1" BO_ 1601 1;
BA_ "GenMsgILSupport" BO_ 1601 1;
BA_ "GenMsgCycleTime" BO_ 1601 1000;
BA_ "NWM-WakeupAllowed" SG_ 262 ESP_Status_Anfahrhilfe 0;
BA_ "GenSigFuncType" SG_ 262 ESP_05_CHK 3;
BA_ "GenSigFuncType" SG_ 262 ESP_05_BZ 1;
BA_ "GenSigStartValue" SG_ 262 ESP_QBit_Bremsdruck 1;
BA_ "GenSigStartValue" SG_ 262 ESP_QBit_Fahrer_bremst 1;
BA_ "GenSigStartValue" SG_ 262 ESP_Bremsdruck 100;
BA_ "Fehlerwert" SG_ 262 ESP_Bremsdruck 1023;
BA_ "GenSigStartValue" SG_ 262 ECD_nicht_verfuegbar 1;
BA_ "Fehlerwert" SG_ 262 ESP_BKV_Unterdruck 255;
BA_ "GenSigFuncType" SG_ 793 Fahrwerk_02_CHK 4;
BA_ "GenSigFuncType" SG_ 793 Fahrwerk_02_BZ 1;
BA_ "NWM-WakeupAllowed" SG_ 924 KL_Beschlagsgefahr 0;
BA_ "GenSigFuncType" SG_ 924 ESP_07_alt 5;
BA_ "NWM-WakeupAllowed" SG_ 924 ESP_07_alt 0;
BA_ "GenSigStartValue" SG_ 924 ESP_07_alt 1;
BA_ "NWM-WakeupAllowed" SG_ 924 BCM1_GLW_Fernlicht_Anf 0;
BA_ "NWM-WakeupAllowed" SG_ 924 BCM1_Gleitende_Leuchtw_Anf 0;
BA_ "NWM-WakeupAllowed" SG_ 924 BCM1_Adaptive_Lichtvert_Anf 0;
BA_ "NWM-WakeupAllowed" SG_ 924 ESP_Offroad_Modus 0;
BA_ "GenSigSendType" SG_ 924 Wischer_vorne_aktiv 3;
BA_ "GenSigSendType" SG_ 924 HR_Tuer_geoeffnet 3;
BA_ "GenSigSendType" SG_ 924 HL_Tuer_geoeffnet 3;
BA_ "GenSigSendType" SG_ 924 BT_Tuer_geoeffnet 3;
BA_ "GenSigStartValue" SG_ 924 BCM1_02_alt 1;
BA_ "GenSigStartValue" SG_ 924 BCM1_01_alt 1;
BA_ "GenSigSendType" SG_ 924 FT_Tuer_geoeffnet 3;
BA_ "GenSigSendType" SG_ 924 BCM1_MH_WIV_Schalter 3;
BA_ "GenSigStartValue" SG_ 924 BCM1_Aussen_Temp_ungef 254;
BA_ "Fehlerwert" SG_ 924 BCM1_Aussen_Temp_ungef 255;
BA_ "GenSigStartValue" SG_ 924 BCM2_03_PAG_alt 1;
BA_ "GenSigStartValue" SG_ 924 Klima_02_alt 1;
BA_ "GenSigSendType" SG_ 924 KL_Zuheizer_Freigabe 3;
BA_ "GenSigSendType" SG_ 924 BCM_Handshake_STH 3;
BA_ "GenSigStartValue" SG_ 924 Wischer_01_alt 1;
BA_ "GenSigStartValue" SG_ 924 TSG_BT_1_alt 1;
BA_ "GenSigStartValue" SG_ 924 TSG_HL_1_alt 1;
BA_ "GenSigStartValue" SG_ 924 TSG_HR_1_alt 1;
BA_ "GenSigStartValue" SG_ 924 Klima_Sensor_02_alt 1;
BA_ "GenSigStartValue" SG_ 924 TSG_FT_1_alt 1;
BA_ "GenSigStartValue" SG_ 924 Parkhilfe_01_alt 1;
BA_ "GenSigStartValue" SG_ 924 Fahrwerk_02_alt 1;
BA_ "GenSigSendType" SG_ 924 PH_StartStopp_Info 3;
BA_ "GenSigStartValue" SG_ 924 BCM1_Schalter_StartStopp 1;
BA_ "NWM-WakeupAllowed" SG_ 1604 ESP_04_alt 0;
BA_ "GenSigStartValue" SG_ 1604 ESP_04_alt 1;
BA_ "GenSigSendType" SG_ 1604 ZV_Tankklappe_offen 3;
BA_ "NWM-WakeupAllowed" SG_ 1604 ZV_Tankklappe_offen 0;
BA_ "GenSigSendType" SG_ 1604 BCM_Tankwunsch 3;
BA_ "NWM-WakeupAllowed" SG_ 1604 BCM_Tankwunsch 0;
BA_ "GenSigSendType" SG_ 1604 ZV_verriegelt_extern_ist 3;
BA_ "GenSigStartValue" SG_ 1604 BCM2_02_alt 1;
BA_ "NWM-WakeupAllowed" SG_ 1604 Kessy_01_alt 0;
BA_ "GenSigStartValue" SG_ 1604 Kessy_01_alt 1;
BA_ "GenSigSendType" SG_ 1604 FFB_CarFinder 3;
BA_ "GenSigActiveRepetitions" SG_ 1604 FFB_CarFinder 10;
BA_ "NWM-WakeupAllowed" SG_ 1604 FFB_CarFinder 0;
BA_ "GenSigSendType" SG_ 1604 FFB_Auf_Taste 3;
BA_ "GenSigActiveRepetitions" SG_ 1604 FFB_Auf_Taste 10;
BA_ "GenSigStartValue" SG_ 1604 Dummy_Blinkmodi_01_alt 1;
BA_ "GenSigStartValue" SG_ 1604 BCM1_01_alt 1;
BA_ "NWM-WakeupAllowed" SG_ 1604 BCM1_Linksverkehr 0;
BA_ "NWM-WakeupAllowed" SG_ 1604 BCM1_Licht_Dunkelheit_aktiv 0;
BA_ "NWM-WakeupAllowed" SG_ 1604 BCM1_Allwetterlicht_Anf 0;
BA_ "GenSigSendType" SG_ 1604 BCM1_MH_Schalter 3;
BA_ "GenSigSendType" SG_ 1604 BH_Blinker_re 3;
BA_ "GenSigSendType" SG_ 1604 BH_Blinker_li 3;
BA_ "GenSigStartValue" SG_ 1604 SMLS_01_alt 1;
BA_ "GenSigStartValue" SG_ 1604 BCM1_02_alt 1;
BA_ "GenSigStartValue" SG_ 1604 HYB_Anf_E_Mode_alt 1;
BA_ "GenSigSendType" SG_ 1604 HYB_Anf_E_Mode 3;
BA_ "GenSigFuncType" SG_ 130 Getriebe_01_CHK 4;
BA_ "GenSigFuncType" SG_ 130 Getriebe_01_BZ 1;
BA_ "Fehlerwert" SG_ 130 GE_Status_Kupplung 3;
BA_ "GenSigStartValue" SG_ 130 GE_MMom_Soll 1022;
BA_ "Fehlerwert" SG_ 130 GE_MMom_Soll 1023;
BA_ "NWM-WakeupAllowed" SG_ 130 GE_Verbot_Ausblendung 0;
BA_ "NWM-WakeupAllowed" SG_ 130 GE_MMom_Vorhalt 0;
BA_ "GenSigStartValue" SG_ 130 GE_MMom_Vorhalt 1022;
BA_ "Fehlerwert" SG_ 130 GE_MMom_Vorhalt 1023;
BA_ "NWM-WakeupAllowed" SG_ 130 GE_Freig_MMom_Vorhalt 0;
BA_ "NWM-WakeupAllowed" SG_ 131 GE_Anf_Zylabsch 0;
BA_ "GenSigFuncType" SG_ 131 Getriebe_02_CHK 4;
BA_ "GenSigFuncType" SG_ 131 Getriebe_02_BZ 1;
BA_ "Fehlerwert" SG_ 131 GE_Synchro_Wunschdrehz 511;
BA_ "Fehlerwert" SG_ 131 GE_Synchro_Zeit 255;
BA_ "GenSigStartValue" SG_ 131 GE_Mom_Begr_Gradient 255;
BA_ "Fehlerwert" SG_ 131 GE_Anheb_Solldrehz_Leerlauf 255;
BA_ "GenSigStartValue" SG_ 131 GE_Vorsteuermoment 510;
BA_ "Fehlerwert" SG_ 131 GE_Vorsteuermoment 511;
BA_ "GenSigMissingSourceValue" SG_ 258 GE_Waehlhebel 15;
BA_ "GenSigStartValue" SG_ 258 GE_Waehlhebel 1;
BA_ "Fehlerwert" SG_ 258 GE_Waehlhebel 15;
BA_ "Bemerkung" SG_ 258 GE_Waehlhebel "Die im Getriebe aktive Fahrstufe entspricht nicht unter allen Umständen der physikalischen Wählhebelposition.";
BA_ "GenSigFuncType" SG_ 258 Getriebe_03_CHK 4;
BA_ "GenSigFuncType" SG_ 258 Getriebe_03_BZ 1;
BA_ "Fehlerwert" SG_ 258 GE_Uefkt 1023;
BA_ "Fehlerwert" SG_ 258 GE_Zielgang 15;
BA_ "GenSigStartValue" SG_ 258 GE_Langfr_Schutzmom 1022;
BA_ "Fehlerwert" SG_ 258 GE_Langfr_Schutzmom 1023;
BA_ "GenSigStartValue" SG_ 258 GE_Eingangsdrehz 16382;
BA_ "Fehlerwert" SG_ 258 GE_Eingangsdrehz 16383;
BA_ "NWM-WakeupAllowed" SG_ 1089 GE_OBD_AbsperrVent 0;
BA_ "NWM-WakeupAllowed" SG_ 1089 GE_Freigabe_Verfallsinfo_WFS 0;
BA_ "GenSigStartValue" SG_ 1089 GE_Index_Fahrwid 127;
BA_ "Fehlerwert" SG_ 1089 GE_Index_Fahrwid 255;
BA_ "GenSigStartValue" SG_ 1089 GE_Heizwunsch 1;
BA_ "GenSigStartValue" SG_ 1089 GE_Grenzkriechmoment 62;
BA_ "Fehlerwert" SG_ 1089 GE_Grenzkriechmoment 63;
BA_ "Fehlerwert" SG_ 1089 GE_Verlustmoment 255;
BA_ "GenSigStartValue" SG_ 1089 GE_amax_moeglich 84;
BA_ "Fehlerwert" SG_ 1089 GE_Sumpftemperatur 255;
BA_ "GenSigFuncType" SG_ 158 Getriebe_Hybrid_01_CHK 4;
BA_ "GenSigFuncType" SG_ 158 Getriebe_Hybrid_01_BZ 1;
BA_ "Fehlerwert" SG_ 158 GE_HYB_nK0 255;
BA_ "NWM-WakeupAllowed" SG_ 158 GE_HYB_Filt_MomAufbau 0;
BA_ "GenSigSendType" SG_ 2022 ISO_EMotor_01_Req_Data 7;
BA_ "GenSigSendType" SG_ 2030 ISO_EMotor_01_Resp_Data 7;
BA_ "GenSigSendType" SG_ 2021 ISO_Hybrid_01_Req_Data 7;
BA_ "GenSigSendType" SG_ 2029 ISO_Hybrid_01_Resp_Data 7;
BA_ "NWM-WakeupAllowed" SG_ 1720 KBI_Tankfuellstand_Prozent 0;
BA_ "GenSigStartValue" SG_ 1720 KBI_Tankfuellstand_Prozent 126;
BA_ "Fehlerwert" SG_ 1720 KBI_Tankfuellstand_Prozent 127;
BA_ "GenSigAutoGenSnd" SG_ 1720 KBI_Tankinhalt_hochaufl 1;
BA_ "GenSigAutoGenDsp" SG_ 1720 KBI_Tankinhalt_hochaufl 1;
BA_ "NWM-WakeupAllowed" SG_ 1720 KBI_Tankinhalt_hochaufl 0;
BA_ "GenSigStartValue" SG_ 1720 KBI_Tankinhalt_hochaufl 16382;
BA_ "Fehlerwert" SG_ 1720 KBI_Tankinhalt_hochaufl 16383;
BA_ "GenSigAutoGenSnd" SG_ 1720 KBI_Nachtanken_erkannt 1;
BA_ "GenSigAutoGenDsp" SG_ 1720 KBI_Nachtanken_erkannt 1;
BA_ "NWM-WakeupAllowed" SG_ 1720 KBI_Nachtanken_erkannt 0;
BA_ "GenSigFuncType" SG_ 128 Motor_01_CHK 4;
BA_ "GenSigFuncType" SG_ 128 Motor_01_BZ 1;
BA_ "GenSigStartValue" SG_ 128 MO_Mom_o_ex 1022;
BA_ "Fehlerwert" SG_ 128 MO_Mom_o_ex 1023;
BA_ "GenSigStartValue" SG_ 128 MO_Mom_m_ex 1022;
BA_ "Fehlerwert" SG_ 128 MO_Mom_m_ex 1023;
BA_ "GenSigStartValue" SG_ 128 MO_Mom_Verlust 1022;
BA_ "Fehlerwert" SG_ 128 MO_Mom_Verlust 1023;
BA_ "GenSigStartValue" SG_ 128 MO_Mom_Begrenzung 1022;
BA_ "Fehlerwert" SG_ 128 MO_Mom_Begrenzung 1023;
BA_ "GenSigStartValue" SG_ 128 MO_Mom_Fahrerwunsch 1022;
BA_ "Fehlerwert" SG_ 128 MO_Mom_Fahrerwunsch 1023;
BA_ "GenSigStartValue" SG_ 129 MO_StartStopp_Status 2;
BA_ "NWM-WakeupAllowed" SG_ 129 MO_StartStopp_Fahrerwunsch 0;
BA_ "GenSigFuncType" SG_ 129 Motor_02_CHK 4;
BA_ "GenSigFuncType" SG_ 129 Motor_02_BZ 1;
BA_ "GenSigStartValue" SG_ 129 MO_Mom_ZWR 1022;
BA_ "Fehlerwert" SG_ 129 MO_Mom_ZWR 1023;
BA_ "GenSigStartValue" SG_ 129 MO_Mom_Soll 1022;
BA_ "Fehlerwert" SG_ 129 MO_Mom_Soll 1023;
BA_ "GenSigStartValue" SG_ 129 MO_Mom_Ist 1022;
BA_ "Fehlerwert" SG_ 129 MO_Mom_Ist 1023;
BA_ "NWM-WakeupAllowed" SG_ 129 MO_Gangposition 0;
BA_ "GenSigStartValue" SG_ 129 MO_Gangposition 14;
BA_ "Fehlerwert" SG_ 129 MO_Gangposition 15;
BA_ "GenSigStartValue" SG_ 261 MO_QBit_Motormomente 1;
BA_ "GenSigFuncType" SG_ 261 Motor_03_CHK 4;
BA_ "GenSigFuncType" SG_ 261 Motor_03_BZ 1;
BA_ "GenSigStartValue" SG_ 261 MO_QBit_Fahrpedalwerte_01 1;
BA_ "GenSigStartValue" SG_ 261 MO_QBit_Fahrer_bremst 1;
BA_ "GenSigStartValue" SG_ 261 MO_QBit_Drehzahl_01 1;
BA_ "Fehlerwert" SG_ 261 MO_Drehzahl_01 65535;
BA_ "Fehlerwert" SG_ 261 MO_Solldrehz_Leerlauf 255;
BA_ "Fehlerwert" SG_ 261 MO_Fahrpedalrohwert_01 255;
BA_ "GenSigStartValue" SG_ 261 MO_QBit_Stressfaktor 1;
BA_ "Fehlerwert" SG_ 263 MO_Anzeigedrehz 4095;
BA_ "Fehlerwert" SG_ 263 MO_Ladedruck 511;
BA_ "NWM-WakeupAllowed" SG_ 263 MO_Oeldruck_HYB 0;
BA_ "GenSigStartValue" SG_ 263 MO_Oeldruck_HYB 254;
BA_ "Fehlerwert" SG_ 263 MO_Oeldruck_HYB 255;
BA_ "NWM-WakeupAllowed" SG_ 782 MO_Handshake_STH 0;
BA_ "GenSigFuncType" SG_ 782 Motor_05_CHK 4;
BA_ "GenSigFuncType" SG_ 782 Motor_05_BZ 1;
BA_ "Fehlerwert" SG_ 782 MO_MAX_Wunschdrehzahl 511;
BA_ "GenSigStartValue" SG_ 782 MO_Anf_KL75 1;
BA_ "Fehlerwert" SG_ 782 MO_MIN_Wunschdrehzahl 255;
BA_ "NWM-WakeupAllowed" SG_ 1088 MO_Kat_Warnung 0;
BA_ "NWM-WakeupAllowed" SG_ 1088 MO_ITM_Warnung_Pumpe 0;
BA_ "NWM-WakeupAllowed" SG_ 1088 MO_HYB_Text_4 0;
BA_ "NWM-WakeupAllowed" SG_ 1088 MO_HYB_Status_HV_Ladung 0;
BA_ "NWM-WakeupAllowed" SG_ 1088 MO_Zustand_HWP 0;
BA_ "GenSigStartValue" SG_ 1088 MO_Zustand_HWP 1;
BA_ "GenSigStartValue" SG_ 1088 MO_Kuehlerluefter_1 126;
BA_ "Fehlerwert" SG_ 1088 MO_Kuehlerluefter_1 127;
BA_ "GenSigStartValue" SG_ 1088 MO_Kuehlerluefter_2 126;
BA_ "Fehlerwert" SG_ 1088 MO_Kuehlerluefter_2 127;
BA_ "NWM-WakeupAllowed" SG_ 1088 WIV_Oeldyn_avl 0;
BA_ "NWM-WakeupAllowed" SG_ 1088 MO_HYB_Text_7 0;
BA_ "NWM-WakeupAllowed" SG_ 1088 MO_HYB_Text_6 0;
BA_ "NWM-WakeupAllowed" SG_ 1088 MO_HYB_Text_5 0;
BA_ "NWM-WakeupAllowed" SG_ 1088 MO_HYB_Text_3 0;
BA_ "NWM-WakeupAllowed" SG_ 1088 MO_HYB_Text_2 0;
BA_ "NWM-WakeupAllowed" SG_ 1088 MO_HYB_Text_1 0;
BA_ "NWM-WakeupAllowed" SG_ 1600 MO_Nachlaufzeit_Heizungspumpe 0;
BA_ "Bemerkung" SG_ 1600 MO_Kennfeldk "0=keine Kennfeldkühlung vorhanden; 1=Kennfeldkühlung vorhanden";
BA_ "GenSigStartValue" SG_ 1600 MO_QBit_Ansaugluft_Temp 1;
BA_ "GenSigStartValue" SG_ 1600 MO_QBit_Oel_Temp 1;
BA_ "GenSigStartValue" SG_ 1600 MO_QBit_Kuehlmittel_Temp 1;
BA_ "GenSigStartValue" SG_ 1600 MO_Ansaugluft_Temp 254;
BA_ "Fehlerwert" SG_ 1600 MO_Ansaugluft_Temp 255;
BA_ "GenSigStartValue" SG_ 1600 MO_Oel_Temp 254;
BA_ "Fehlerwert" SG_ 1600 MO_Oel_Temp 255;
BA_ "GenSigStartValue" SG_ 1600 MO_Kuehlmittel_Temp 254;
BA_ "Fehlerwert" SG_ 1600 MO_Kuehlmittel_Temp 255;
BA_ "Fehlerwert" SG_ 1600 MO_Hoeheninfo 255;
BA_ "GenSigStartValue" SG_ 1600 MO_Heizungspumpenansteuerung 14;
BA_ "NWM-WakeupAllowed" SG_ 1600 MO_SpannungsAnf 0;
BA_ "NWM-WakeupAllowed" SG_ 1600 MO_aktives_Getriebeheizen 0;
BA_ "GenSigFuncType" SG_ 1601 Motor_Code_01_CHK 4;
BA_ "GenSigFuncType" SG_ 1601 Motor_Code_01_BZ 1;
BA_REL_ "GenSigTimeoutTime" BU_SG_REL_ Motor_EDC17_Pirol SG_ 262 ESP_Status_Anfahrhilfe 500;
BA_REL_ "GenSigTimeoutTime" BU_SG_REL_ Motor_MED17_Hybrid SG_ 262 ESP_Status_Anfahrhilfe 500;
BA_REL_ "GenSigTimeoutTime" BU_SG_REL_ GW_Routing_Derivate SG_ 262 ESP_Status_Anfahrhilfe 500;
BA_REL_ "GenSigTimeoutTime" BU_SG_REL_ GW_Routing_Derivate SG_ 262 ESP_Anforderung_EPB 500;
BA_REL_ "GenSigTimeoutTime" BU_SG_REL_ GW_Routing_Derivate SG_ 262 ESP_Lenkeingriff_ADS 500;
BA_REL_ "GenSigTimeoutTime" BU_SG_REL_ GW_Routing_Derivate SG_ 262 ESP_Bremsruck_AWV2 500;
BA_REL_ "GenSigTimeoutTime" BU_SG_REL_ GW_Routing_Derivate SG_ 262 ESP_Konsistenz_AWV2 500;
BA_REL_ "GenSigTimeoutTime" BU_SG_REL_ Motor_EDC17_Pirol SG_ 262 ESP_05_CHK 500;
BA_REL_ "GenSigTimeoutTime" BU_SG_REL_ Motor_MED17_Hybrid SG_ 262 ESP_05_CHK 500;
BA_REL_ "GenSigTimeoutTime" BU_SG_REL_ GW_Routing_Derivate SG_ 262 ESP_05_CHK 500;
BA_REL_ "GenSigTimeoutTime" BU_SG_REL_ Getriebe_Derivate SG_ 262 ESP_05_CHK 500;
BA_REL_ "GenSigTimeoutTime" BU_SG_REL_ Motor_EDC17_Pirol SG_ 262 ESP_05_BZ 500;
BA_REL_ "GenSigTimeoutTime" BU_SG_REL_ Motor_MED17_Hybrid SG_ 262 ESP_05_BZ 500;
BA_REL_ "GenSigTimeoutTime" BU_SG_REL_ GW_Routing_Derivate SG_ 262 ESP_05_BZ 500;
BA_REL_ "GenSigTimeoutTime" BU_SG_REL_ Getriebe_Derivate SG_ 262 ESP_05_BZ 500;
BA_REL_ "GenSigTimeoutTime" BU_SG_REL_ Motor_EDC17_Pirol SG_ 262 ESP_QBit_Bremsdruck 500;
BA_REL_ "GenSigTimeoutTime" BU_SG_REL_ Motor_MED17_Hybrid SG_ 262 ESP_QBit_Bremsdruck 500;
BA_REL_ "GenSigTimeoutTime" BU_SG_REL_ GW_Routing_Derivate SG_ 262 ESP_QBit_Bremsdruck 500;
BA_REL_ "GenSigTimeoutTime" BU_SG_REL_ Getriebe_Derivate SG_ 262 ESP_QBit_Bremsdruck 500;
BA_REL_ "GenSigTimeoutTime" BU_SG_REL_ Motor_EDC17_Pirol SG_ 262 ESP_QBit_Fahrer_bremst 500;
BA_REL_ "GenSigTimeoutTime" BU_SG_REL_ Motor_MED17_Hybrid SG_ 262 ESP_QBit_Fahrer_bremst 500;
BA_REL_ "GenSigTimeoutTime" BU_SG_REL_ GW_Routing_Derivate SG_ 262 ESP_QBit_Fahrer_bremst 500;
BA_REL_ "GenSigTimeoutTime" BU_SG_REL_ Motor_EDC17_Pirol SG_ 262 ESP_Schwelle_Unterdruck 500;
BA_REL_ "GenSigTimeoutTime" BU_SG_REL_ Motor_MED17_Hybrid SG_ 262 ESP_Schwelle_Unterdruck 500;
BA_REL_ "GenSigTimeoutTime" BU_SG_REL_ GW_Routing_Derivate SG_ 262 ESP_Schwelle_Unterdruck 500;
BA_REL_ "GenSigTimeoutTime" BU_SG_REL_ Motor_EDC17_Pirol SG_ 262 ESP_Bremsdruck 500;
BA_REL_ "GenSigTimeoutTime" BU_SG_REL_ Motor_MED17_Hybrid SG_ 262 ESP_Bremsdruck 500;
BA_REL_ "GenSigTimeoutTime" BU_SG_REL_ GW_Routing_Derivate SG_ 262 ESP_Bremsdruck 500;
BA_REL_ "GenSigTimeoutTime" BU_SG_REL_ Getriebe_Derivate SG_ 262 ESP_Bremsdruck 500;
BA_REL_ "GenSigTimeoutTime" BU_SG_REL_ Motor_EDC17_Pirol SG_ 262 ESP_Fahrer_bremst 500;
BA_REL_ "GenSigTimeoutTime" BU_SG_REL_ Motor_MED17_Hybrid SG_ 262 ESP_Fahrer_bremst 500;
BA_REL_ "GenSigTimeoutTime" BU_SG_REL_ GW_Routing_Derivate SG_ 262 ESP_Fahrer_bremst 500;
BA_REL_ "GenSigTimeoutTime" BU_SG_REL_ Motor_EDC17_Pirol SG_ 262 ESP_Verz_TSK_aktiv 500;
BA_REL_ "GenSigTimeoutTime" BU_SG_REL_ Getriebe_Derivate SG_ 262 ESP_Verz_TSK_aktiv 500;
BA_REL_ "GenSigTimeoutTime" BU_SG_REL_ Motor_MED17_Hybrid SG_ 262 ESP_Verz_TSK_aktiv 500;
BA_REL_ "GenSigTimeoutTime" BU_SG_REL_ GW_Routing_Derivate SG_ 262 ESP_Verz_TSK_aktiv 500;
BA_REL_ "GenSigTimeoutTime" BU_SG_REL_ Motor_EDC17_Pirol SG_ 262 ESP_Konsistenz_TSK 500;
BA_REL_ "GenSigTimeoutTime" BU_SG_REL_ Motor_MED17_Hybrid SG_ 262 ESP_Konsistenz_TSK 500;
BA_REL_ "GenSigTimeoutTime" BU_SG_REL_ GW_Routing_Derivate SG_ 262 ESP_Konsistenz_TSK 500;
BA_REL_ "GenSigTimeoutTime" BU_SG_REL_ Motor_EDC17_Pirol SG_ 262 ECD_Fehler 500;
BA_REL_ "GenSigTimeoutTime" BU_SG_REL_ Motor_MED17_Hybrid SG_ 262 ECD_Fehler 500;
BA_REL_ "GenSigTimeoutTime" BU_SG_REL_ GW_Routing_Derivate SG_ 262 ECD_Fehler 500;
BA_REL_ "GenSigTimeoutTime" BU_SG_REL_ Motor_EDC17_Pirol SG_ 262 ECD_nicht_verfuegbar 500;
BA_REL_ "GenSigTimeoutTime" BU_SG_REL_ Motor_MED17_Hybrid SG_ 262 ECD_nicht_verfuegbar 500;
BA_REL_ "GenSigTimeoutTime" BU_SG_REL_ GW_Routing_Derivate SG_ 262 ECD_nicht_verfuegbar 500;
BA_REL_ "GenSigTimeoutTime" BU_SG_REL_ Motor_EDC17_Pirol SG_ 262 ESP_Status_Bremsentemp 500;
BA_REL_ "GenSigTimeoutTime" BU_SG_REL_ Motor_MED17_Hybrid SG_ 262 ESP_Status_Bremsentemp 500;
BA_REL_ "GenSigTimeoutTime" BU_SG_REL_ GW_Routing_Derivate SG_ 262 ESP_Status_Bremsentemp 500;
BA_REL_ "GenSigTimeoutTime" BU_SG_REL_ GW_Routing_Derivate SG_ 262 ESP_Autohold_Standby 500;
BA_REL_ "GenSigTimeoutTime" BU_SG_REL_ Motor_EDC17_Pirol SG_ 262 ESP_HDC_Standby 500;
BA_REL_ "GenSigTimeoutTime" BU_SG_REL_ Motor_MED17_Hybrid SG_ 262 ESP_HDC_Standby 500;
BA_REL_ "GenSigTimeoutTime" BU_SG_REL_ GW_Routing_Derivate SG_ 262 ESP_HDC_Standby 500;
BA_REL_ "GenSigTimeoutTime" BU_SG_REL_ GW_Routing_Derivate SG_ 262 ESP_HBA_aktiv 500;
BA_REL_ "GenSigTimeoutTime" BU_SG_REL_ GW_Routing_Derivate SG_ 262 ESP_Prefill_ausgeloest 500;
BA_REL_ "GenSigTimeoutTime" BU_SG_REL_ GW_Routing_Derivate SG_ 262 ESP_Rueckwaertsfahrt_erkannt 500;
BA_REL_ "GenSigTimeoutTime" BU_SG_REL_ Motor_EDC17_Pirol SG_ 262 ESP_StartStopp_Info 500;
BA_REL_ "GenSigTimeoutTime" BU_SG_REL_ Motor_MED17_Hybrid SG_ 262 ESP_StartStopp_Info 500;
BA_REL_ "GenSigTimeoutTime" BU_SG_REL_ GW_Routing_Derivate SG_ 262 ESP_StartStopp_Info 500;
BA_REL_ "GenSigTimeoutTime" BU_SG_REL_ GW_Routing_Derivate SG_ 262 ESP_Eingr_HL 500;
BA_REL_ "GenSigTimeoutTime" BU_SG_REL_ GW_Routing_Derivate SG_ 262 ESP_Eingr_HR 500;
BA_REL_ "GenSigTimeoutTime" BU_SG_REL_ GW_Routing_Derivate SG_ 262 ESP_Eingr_VL 500;
BA_REL_ "GenSigTimeoutTime" BU_SG_REL_ GW_Routing_Derivate SG_ 262 ESP_Eingr_VR 500;
BA_REL_ "GenSigTimeoutTime" BU_SG_REL_ Motor_EDC17_Pirol SG_ 262 ESP_BKV_Unterdruck 500;
BA_REL_ "GenSigTimeoutTime" BU_SG_REL_ Motor_MED17_Hybrid SG_ 262 ESP_BKV_Unterdruck 500;
BA_REL_ "GenSigTimeoutTime" BU_SG_REL_ GW_Routing_Derivate SG_ 262 ESP_BKV_Unterdruck 500;
BA_REL_ "GenSigTimeoutTime" BU_SG_REL_ Motor_EDC17_Pirol SG_ 262 ESP_Autohold_aktiv 500;
BA_REL_ "GenSigTimeoutTime" BU_SG_REL_ Motor_MED17_Hybrid SG_ 262 ESP_Autohold_aktiv 500;
BA_REL_ "GenSigTimeoutTime" BU_SG_REL_ GW_Routing_Derivate SG_ 262 ESP_Autohold_aktiv 500;
BA_REL_ "GenSigTimeoutTime" BU_SG_REL_ GW_Routing_Derivate SG_ 262 ESP_FStatus_Anfahrhilfe 500;
BA_REL_ "GenSigTimeoutTime" BU_SG_REL_ GW_Routing_Derivate SG_ 262 ESP_Verz_EPB_aktiv 500;
BA_REL_ "GenSigTimeoutTime" BU_SG_REL_ Getriebe_Derivate SG_ 262 ESP_Verz_EPB_aktiv 500;
BA_REL_ "GenSigTimeoutTime" BU_SG_REL_ Motor_EDC17_Pirol SG_ 262 ECD_Bremslicht 500;
BA_REL_ "GenSigTimeoutTime" BU_SG_REL_ Motor_MED17_Hybrid SG_ 262 ECD_Bremslicht 500;
BA_REL_ "GenSigTimeoutTime" BU_SG_REL_ GW_Routing_Derivate SG_ 262 ECD_Bremslicht 500;
BA_REL_ "GenSigTimeoutTime" BU_SG_REL_ GW_Routing_Derivate SG_ 262 ESP_Verzoeg_EPB_verf 500;
BA_REL_ "GenSigTimeoutTime" BU_SG_REL_ Motor_EDC17_Pirol SG_ 262 ESP_Status_Bremsdruck 500;
BA_REL_ "GenSigTimeoutTime" BU_SG_REL_ Motor_MED17_Hybrid SG_ 262 ESP_Status_Bremsdruck 500;
BA_REL_ "GenSigTimeoutTime" BU_SG_REL_ GW_Routing_Derivate SG_ 262 ESP_Status_Bremsdruck 500;
BA_REL_ "GenSigTimeoutTime" BU_SG_REL_ Motor_EDC17_Pirol SG_ 793 Fahrwerk_02_CHK 500;
BA_REL_ "GenSigTimeoutTime" BU_SG_REL_ Motor_MED17_Hybrid SG_ 793 Fahrwerk_02_CHK 500;
BA_REL_ "GenSigTimeoutTime" BU_SG_REL_ Motor_EDC17_Pirol SG_ 793 Fahrwerk_02_BZ 500;
BA_REL_ "GenSigTimeoutTime" BU_SG_REL_ Motor_MED17_Hybrid SG_ 793 Fahrwerk_02_BZ 500;
BA_REL_ "GenSigTimeoutTime" BU_SG_REL_ Motor_EDC17_Pirol SG_ 793 FA_MSG_Einschraenkung 500;
BA_REL_ "GenSigTimeoutTime" BU_SG_REL_ Motor_MED17_Hybrid SG_ 793 FA_MSG_Einschraenkung 500;
BA_REL_ "GenSigTimeoutTime" BU_SG_REL_ Getriebe_Derivate SG_ 924 ESP_Offroad_Modus 1000;
BA_REL_ "GenSigTimeoutTime" BU_SG_REL_ Motor_EDC17_Pirol SG_ 924 Wischer_vorne_aktiv 1000;
BA_REL_ "GenSigTimeoutTime" BU_SG_REL_ Motor_MED17_Hybrid SG_ 924 Wischer_vorne_aktiv 1000;
BA_REL_ "GenSigTimeoutTime" BU_SG_REL_ Motor_EDC17_Pirol SG_ 924 HR_Tuer_geoeffnet 1000;
BA_REL_ "GenSigTimeoutTime" BU_SG_REL_ Motor_MED17_Hybrid SG_ 924 HR_Tuer_geoeffnet 1000;
BA_REL_ "GenSigTimeoutTime" BU_SG_REL_ Motor_EDC17_Pirol SG_ 924 HL_Tuer_geoeffnet 1000;
BA_REL_ "GenSigTimeoutTime" BU_SG_REL_ Motor_MED17_Hybrid SG_ 924 HL_Tuer_geoeffnet 1000;
BA_REL_ "GenSigTimeoutTime" BU_SG_REL_ Motor_EDC17_Pirol SG_ 924 FT_Sperrklinke 1000;
BA_REL_ "GenSigTimeoutTime" BU_SG_REL_ Motor_MED17_Hybrid SG_ 924 FT_Sperrklinke 1000;
BA_REL_ "GenSigTimeoutTime" BU_SG_REL_ Motor_EDC17_Pirol SG_ 924 BT_Tuer_geoeffnet 1000;
BA_REL_ "GenSigTimeoutTime" BU_SG_REL_ Motor_MED17_Hybrid SG_ 924 BT_Tuer_geoeffnet 1000;
BA_REL_ "GenSigTimeoutTime" BU_SG_REL_ Motor_EDC17_Pirol SG_ 924 BCM1_02_alt 1000;
BA_REL_ "GenSigTimeoutTime" BU_SG_REL_ Motor_MED17_Hybrid SG_ 924 BCM1_02_alt 1000;
BA_REL_ "GenSigTimeoutTime" BU_SG_REL_ Motor_EDC17_Pirol SG_ 924 BCM1_01_alt 1000;
BA_REL_ "GenSigTimeoutTime" BU_SG_REL_ Motor_MED17_Hybrid SG_ 924 BCM1_01_alt 1000;
BA_REL_ "GenSigTimeoutTime" BU_SG_REL_ Motor_EDC17_Pirol SG_ 924 FT_Tuer_geoeffnet 1000;
BA_REL_ "GenSigTimeoutTime" BU_SG_REL_ Getriebe_Derivate SG_ 924 FT_Tuer_geoeffnet 1000;
BA_REL_ "GenSigTimeoutTime" BU_SG_REL_ Motor_MED17_Hybrid SG_ 924 FT_Tuer_geoeffnet 1000;
BA_REL_ "GenSigTimeoutTime" BU_SG_REL_ Motor_EDC17_Pirol SG_ 924 BCM1_Rueckfahrlicht_Schalter 1000;
BA_REL_ "GenSigTimeoutTime" BU_SG_REL_ Motor_MED17_Hybrid SG_ 924 BCM1_Rueckfahrlicht_Schalter 1000;
BA_REL_ "GenSigTimeoutTime" BU_SG_REL_ Motor_EDC17_Pirol SG_ 924 BCM1_MH_WIV_Schalter 1000;
BA_REL_ "GenSigTimeoutTime" BU_SG_REL_ Motor_MED17_Hybrid SG_ 924 BCM1_MH_WIV_Schalter 1000;
BA_REL_ "GenSigTimeoutTime" BU_SG_REL_ LEH_Hybrid SG_ 924 BCM1_Aussen_Temp_ungef 1000;
BA_REL_ "GenSigTimeoutTime" BU_SG_REL_ BMS_Hybrid SG_ 924 BCM1_Aussen_Temp_ungef 1000;
BA_REL_ "GenSigTimeoutTime" BU_SG_REL_ Motor_EDC17_Pirol SG_ 924 BCM1_Aussen_Temp_ungef 1000;
BA_REL_ "GenSigTimeoutTime" BU_SG_REL_ Motor_MED17_Hybrid SG_ 924 BCM1_Aussen_Temp_ungef 1000;
BA_REL_ "GenSigTimeoutTime" BU_SG_REL_ Motor_EDC17_Pirol SG_ 924 Wischer_01_alt 1000;
BA_REL_ "GenSigTimeoutTime" BU_SG_REL_ Motor_MED17_Hybrid SG_ 924 Wischer_01_alt 1000;
BA_REL_ "GenSigTimeoutTime" BU_SG_REL_ Motor_EDC17_Pirol SG_ 924 TSG_BT_1_alt 1000;
BA_REL_ "GenSigTimeoutTime" BU_SG_REL_ Motor_MED17_Hybrid SG_ 924 TSG_BT_1_alt 1000;
BA_REL_ "GenSigTimeoutTime" BU_SG_REL_ Motor_EDC17_Pirol SG_ 924 TSG_HL_1_alt 1000;
BA_REL_ "GenSigTimeoutTime" BU_SG_REL_ Motor_MED17_Hybrid SG_ 924 TSG_HL_1_alt 1000;
BA_REL_ "GenSigTimeoutTime" BU_SG_REL_ Motor_EDC17_Pirol SG_ 924 TSG_HR_1_alt 1000;
BA_REL_ "GenSigTimeoutTime" BU_SG_REL_ Motor_MED17_Hybrid SG_ 924 TSG_HR_1_alt 1000;
BA_REL_ "GenSigTimeoutTime" BU_SG_REL_ LEH_Hybrid SG_ 924 Klima_Sensor_02_alt 1000;
BA_REL_ "GenSigTimeoutTime" BU_SG_REL_ BMS_Hybrid SG_ 924 Klima_Sensor_02_alt 1000;
BA_REL_ "GenSigTimeoutTime" BU_SG_REL_ Motor_EDC17_Pirol SG_ 924 Klima_Sensor_02_alt 1000;
BA_REL_ "GenSigTimeoutTime" BU_SG_REL_ Motor_MED17_Hybrid SG_ 924 Klima_Sensor_02_alt 1000;
BA_REL_ "GenSigTimeoutTime" BU_SG_REL_ Motor_EDC17_Pirol SG_ 924 TSG_FT_1_alt 1000;
BA_REL_ "GenSigTimeoutTime" BU_SG_REL_ Getriebe_Derivate SG_ 924 TSG_FT_1_alt 1000;
BA_REL_ "GenSigTimeoutTime" BU_SG_REL_ Motor_MED17_Hybrid SG_ 924 TSG_FT_1_alt 1000;
BA_REL_ "GenSigTimeoutTime" BU_SG_REL_ Motor_EDC17_Pirol SG_ 924 Parkhilfe_01_alt 1000;
BA_REL_ "GenSigTimeoutTime" BU_SG_REL_ Motor_MED17_Hybrid SG_ 924 Parkhilfe_01_alt 1000;
BA_REL_ "GenSigTimeoutTime" BU_SG_REL_ Motor_EDC17_Pirol SG_ 924 Fahrwerk_02_alt 1000;
BA_REL_ "GenSigTimeoutTime" BU_SG_REL_ Motor_MED17_Hybrid SG_ 924 Fahrwerk_02_alt 1000;
BA_REL_ "GenSigTimeoutTime" BU_SG_REL_ Motor_EDC17_Pirol SG_ 924 FA_StartStopp_Info 1000;
BA_REL_ "GenSigTimeoutTime" BU_SG_REL_ Motor_MED17_Hybrid SG_ 924 FA_StartStopp_Info 1000;
BA_REL_ "GenSigTimeoutTime" BU_SG_REL_ Motor_EDC17_Pirol SG_ 924 PH_StartStopp_Info 1000;
BA_REL_ "GenSigTimeoutTime" BU_SG_REL_ Motor_MED17_Hybrid SG_ 924 PH_StartStopp_Info 1000;
BA_REL_ "GenSigTimeoutTime" BU_SG_REL_ Motor_EDC17_Pirol SG_ 924 BCM1_OBD_FStatus_ATemp 1000;
BA_REL_ "GenSigTimeoutTime" BU_SG_REL_ Motor_MED17_Hybrid SG_ 924 BCM1_OBD_FStatus_ATemp 1000;
BA_REL_ "GenSigTimeoutTime" BU_SG_REL_ Motor_EDC17_Pirol SG_ 924 BCM1_Schalter_StartStopp 1000;
BA_REL_ "GenSigTimeoutTime" BU_SG_REL_ Motor_MED17_Hybrid SG_ 924 BCM1_Schalter_StartStopp 1000;
BA_REL_ "GenSigTimeoutTime" BU_SG_REL_ Ladegeraet_PAG_PF SG_ 1604 ZV_verriegelt_extern_ist 5000;
BA_REL_ "GenSigTimeoutTime" BU_SG_REL_ Ladegeraet_PAG_PF SG_ 1604 Kessy_01_alt 5000;
BA_REL_ "GenSigTimeoutTime" BU_SG_REL_ Ladegeraet_PAG_PF SG_ 1604 FFB_CarFinder 5000;
BA_REL_ "GenSigTimeoutTime" BU_SG_REL_ Ladegeraet_PAG_PF SG_ 1604 FFB_Auf_Taste 5000;
BA_REL_ "GenSigTimeoutTime" BU_SG_REL_ Motor_EDC17_Pirol SG_ 1604 BCM1_MH_Schalter 5000;
BA_REL_ "GenSigTimeoutTime" BU_SG_REL_ Motor_MED17_Hybrid SG_ 1604 BCM1_MH_Schalter 5000;
BA_REL_ "GenSigTimeoutTime" BU_SG_REL_ Motor_EDC17_Pirol SG_ 1604 BH_Blinker_re 5000;
BA_REL_ "GenSigTimeoutTime" BU_SG_REL_ Motor_MED17_Hybrid SG_ 1604 BH_Blinker_re 5000;
BA_REL_ "GenSigTimeoutTime" BU_SG_REL_ Motor_EDC17_Pirol SG_ 1604 BH_Blinker_li 5000;
BA_REL_ "GenSigTimeoutTime" BU_SG_REL_ Motor_MED17_Hybrid SG_ 1604 BH_Blinker_li 5000;
BA_REL_ "GenSigTimeoutTime" BU_SG_REL_ Motor_EDC17_Pirol SG_ 1604 SMLS_01_alt 5000;
BA_REL_ "GenSigTimeoutTime" BU_SG_REL_ Motor_MED17_Hybrid SG_ 1604 SMLS_01_alt 5000;
BA_REL_ "GenSigTimeoutTime" BU_SG_REL_ Ladegeraet_PAG_PF SG_ 1604 BCM1_02_alt 5000;
BA_REL_ "GenSigTimeoutTime" BU_SG_REL_ Motor_EDC17_Pirol SG_ 1604 BCM1_02_alt 5000;
BA_REL_ "GenSigTimeoutTime" BU_SG_REL_ Motor_MED17_Hybrid SG_ 1604 BCM1_02_alt 5000;
BA_REL_ "GenSigTimeoutTime" BU_SG_REL_ Motor_MED17_Hybrid SG_ 1604 HYB_Anf_E_Mode_alt 5000;
BA_REL_ "GenSigTimeoutTime" BU_SG_REL_ Motor_MED17_Hybrid SG_ 1604 HYB_Anf_E_Mode 5000;
BA_REL_ "GenSigTimeoutTime" BU_SG_REL_ Motor_EDC17_Pirol SG_ 130 Getriebe_01_CHK 500;
BA_REL_ "GenSigTimeoutTime" BU_SG_REL_ PSM_Ant_Derivate SG_ 130 Getriebe_01_CHK 500;
BA_REL_ "GenSigTimeoutTime" BU_SG_REL_ GW_Routing_Derivate SG_ 130 Getriebe_01_CHK 500;
BA_REL_ "GenSigTimeoutTime" BU_SG_REL_ Motor_MED17_Hybrid SG_ 130 Getriebe_01_CHK 500;
BA_REL_ "GenSigTimeoutTime" BU_SG_REL_ Motor_EDC17_Pirol SG_ 130 Getriebe_01_BZ 500;
BA_REL_ "GenSigTimeoutTime" BU_SG_REL_ PSM_Ant_Derivate SG_ 130 Getriebe_01_BZ 500;
BA_REL_ "GenSigTimeoutTime" BU_SG_REL_ GW_Routing_Derivate SG_ 130 Getriebe_01_BZ 500;
BA_REL_ "GenSigTimeoutTime" BU_SG_REL_ Motor_MED17_Hybrid SG_ 130 Getriebe_01_BZ 500;
BA_REL_ "GenSigTimeoutTime" BU_SG_REL_ Motor_EDC17_Pirol SG_ 130 GE_Schaltvorgang 500;
BA_REL_ "GenSigTimeoutTime" BU_SG_REL_ PSM_Ant_Derivate SG_ 130 GE_Schaltvorgang 500;
BA_REL_ "GenSigTimeoutTime" BU_SG_REL_ GW_Routing_Derivate SG_ 130 GE_Schaltvorgang 500;
BA_REL_ "GenSigTimeoutTime" BU_SG_REL_ Motor_MED17_Hybrid SG_ 130 GE_Schaltvorgang 500;
BA_REL_ "GenSigTimeoutTime" BU_SG_REL_ Motor_EDC17_Pirol SG_ 130 GE_Status_Kupplung 500;
BA_REL_ "GenSigTimeoutTime" BU_SG_REL_ PSM_Ant_Derivate SG_ 130 GE_Status_Kupplung 500;
BA_REL_ "GenSigTimeoutTime" BU_SG_REL_ GW_Routing_Derivate SG_ 130 GE_Status_Kupplung 500;
BA_REL_ "GenSigTimeoutTime" BU_SG_REL_ Motor_MED17_Hybrid SG_ 130 GE_Status_Kupplung 500;
BA_REL_ "GenSigTimeoutTime" BU_SG_REL_ Motor_EDC17_Pirol SG_ 130 GE_MMom_Soll 500;
BA_REL_ "GenSigTimeoutTime" BU_SG_REL_ PSM_Ant_Derivate SG_ 130 GE_MMom_Soll 500;
BA_REL_ "GenSigTimeoutTime" BU_SG_REL_ GW_Routing_Derivate SG_ 130 GE_MMom_Soll 500;
BA_REL_ "GenSigTimeoutTime" BU_SG_REL_ Motor_MED17_Hybrid SG_ 130 GE_MMom_Soll 500;
BA_REL_ "GenSigTimeoutTime" BU_SG_REL_ Motor_EDC17_Pirol SG_ 130 GE_MMom_Status 500;
BA_REL_ "GenSigTimeoutTime" BU_SG_REL_ PSM_Ant_Derivate SG_ 130 GE_MMom_Status 500;
BA_REL_ "GenSigTimeoutTime" BU_SG_REL_ GW_Routing_Derivate SG_ 130 GE_MMom_Status 500;
BA_REL_ "GenSigTimeoutTime" BU_SG_REL_ Motor_MED17_Hybrid SG_ 130 GE_MMom_Status 500;
BA_REL_ "GenSigTimeoutTime" BU_SG_REL_ PSM_Ant_Derivate SG_ 130 GE_Freig_Mmom_Soll 500;
BA_REL_ "GenSigTimeoutTime" BU_SG_REL_ GW_Routing_Derivate SG_ 130 GE_Freig_Mmom_Soll 500;
BA_REL_ "GenSigTimeoutTime" BU_SG_REL_ PSM_Ant_Derivate SG_ 130 GE_Status_Schaltablauf 500;
BA_REL_ "GenSigTimeoutTime" BU_SG_REL_ GW_Routing_Derivate SG_ 130 GE_Status_Schaltablauf 500;
BA_REL_ "GenSigTimeoutTime" BU_SG_REL_ PSM_Ant_Derivate SG_ 130 GE_KD_Fehler 500;
BA_REL_ "GenSigTimeoutTime" BU_SG_REL_ GW_Applikation_Derivate SG_ 130 GE_KD_Fehler 500;
BA_REL_ "GenSigTimeoutTime" BU_SG_REL_ GW_Routing_Derivate SG_ 130 GE_KD_Fehler 500;
BA_REL_ "GenSigTimeoutTime" BU_SG_REL_ GW_Routing_Derivate SG_ 130 GE_Verbot_Ausblendung 500;
BA_REL_ "GenSigTimeoutTime" BU_SG_REL_ Motor_EDC17_Pirol SG_ 130 GE_Verbot_Ausblendung 500;
BA_REL_ "GenSigTimeoutTime" BU_SG_REL_ Motor_MED17_Hybrid SG_ 130 GE_Verbot_Ausblendung 500;
BA_REL_ "GenSigTimeoutTime" BU_SG_REL_ GW_Routing_Derivate SG_ 130 GE_MMom_Vorhalt 500;
BA_REL_ "GenSigTimeoutTime" BU_SG_REL_ Motor_EDC17_Pirol SG_ 130 GE_MMom_Vorhalt 500;
BA_REL_ "GenSigTimeoutTime" BU_SG_REL_ Motor_MED17_Hybrid SG_ 130 GE_MMom_Vorhalt 500;
BA_REL_ "GenSigTimeoutTime" BU_SG_REL_ GW_Routing_Derivate SG_ 130 GE_Freig_MMom_Vorhalt 500;
BA_REL_ "GenSigTimeoutTime" BU_SG_REL_ Motor_EDC17_Pirol SG_ 130 GE_Freig_MMom_Vorhalt 500;
BA_REL_ "GenSigTimeoutTime" BU_SG_REL_ Motor_MED17_Hybrid SG_ 130 GE_Freig_MMom_Vorhalt 500;
BA_REL_ "GenSigTimeoutTime" BU_SG_REL_ Motor_EDC17_Pirol SG_ 131 Getriebe_02_CHK 500;
BA_REL_ "GenSigTimeoutTime" BU_SG_REL_ Motor_MED17_Hybrid SG_ 131 Getriebe_02_CHK 500;
BA_REL_ "GenSigTimeoutTime" BU_SG_REL_ Motor_EDC17_Pirol SG_ 131 Getriebe_02_BZ 500;
BA_REL_ "GenSigTimeoutTime" BU_SG_REL_ Motor_MED17_Hybrid SG_ 131 Getriebe_02_BZ 500;
BA_REL_ "GenSigTimeoutTime" BU_SG_REL_ Motor_EDC17_Pirol SG_ 131 GE_Synchro_Wunschdrehz 500;
BA_REL_ "GenSigTimeoutTime" BU_SG_REL_ Motor_MED17_Hybrid SG_ 131 GE_Synchro_Wunschdrehz 500;
BA_REL_ "GenSigTimeoutTime" BU_SG_REL_ Motor_EDC17_Pirol SG_ 131 GE_Synchro_Zeit 500;
BA_REL_ "GenSigTimeoutTime" BU_SG_REL_ Motor_MED17_Hybrid SG_ 131 GE_Synchro_Zeit 500;
BA_REL_ "GenSigTimeoutTime" BU_SG_REL_ Motor_EDC17_Pirol SG_ 131 GE_Mom_Begr_Gradient 500;
BA_REL_ "GenSigTimeoutTime" BU_SG_REL_ Motor_MED17_Hybrid SG_ 131 GE_Mom_Begr_Gradient 500;
BA_REL_ "GenSigTimeoutTime" BU_SG_REL_ Motor_EDC17_Pirol SG_ 131 GE_Anheb_Solldrehz_Leerlauf 500;
BA_REL_ "GenSigTimeoutTime" BU_SG_REL_ Motor_MED17_Hybrid SG_ 131 GE_Anheb_Solldrehz_Leerlauf 500;
BA_REL_ "GenSigTimeoutTime" BU_SG_REL_ Motor_EDC17_Pirol SG_ 131 GE_Vorsteuermoment 500;
BA_REL_ "GenSigTimeoutTime" BU_SG_REL_ Motor_MED17_Hybrid SG_ 131 GE_Vorsteuermoment 500;
BA_REL_ "GenSigTimeoutTime" BU_SG_REL_ Motor_EDC17_Pirol SG_ 131 GE_Drehzahlmesser_Daempfung 500;
BA_REL_ "GenSigTimeoutTime" BU_SG_REL_ Motor_MED17_Hybrid SG_ 131 GE_Drehzahlmesser_Daempfung 500;
BA_REL_ "GenSigTimeoutTime" BU_SG_REL_ Motor_EDC17_Pirol SG_ 131 GE_Schubabschalt_Unt 500;
BA_REL_ "GenSigTimeoutTime" BU_SG_REL_ Motor_MED17_Hybrid SG_ 131 GE_Schubabschalt_Unt 500;
BA_REL_ "GenSigTimeoutTime" BU_SG_REL_ Motor_EDC17_Pirol SG_ 131 GE_Freigabe_Synchro 500;
BA_REL_ "GenSigTimeoutTime" BU_SG_REL_ Motor_MED17_Hybrid SG_ 131 GE_Freigabe_Synchro 500;
BA_REL_ "GenSigTimeoutTime" BU_SG_REL_ Motor_MED17_Hybrid SG_ 131 GE_HYB_DZ_Eingriff 500;
BA_REL_ "GenSigTimeoutTime" BU_SG_REL_ Motor_EDC17_Pirol SG_ 258 GE_Waehlhebel 500;
BA_REL_ "GenSigTimeoutTime" BU_SG_REL_ GW_Routing_Derivate SG_ 258 GE_Waehlhebel 500;
BA_REL_ "GenSigTimeoutTime" BU_SG_REL_ PSM_Ant_Derivate SG_ 258 GE_Waehlhebel 500;
BA_REL_ "GenSigTimeoutTime" BU_SG_REL_ Motor_MED17_Hybrid SG_ 258 GE_Waehlhebel 500;
BA_REL_ "GenSigTimeoutTime" BU_SG_REL_ Motor_EDC17_Pirol SG_ 258 GE_StartStopp_Info 500;
BA_REL_ "GenSigTimeoutTime" BU_SG_REL_ GW_Routing_Derivate SG_ 258 GE_StartStopp_Info 500;
BA_REL_ "GenSigTimeoutTime" BU_SG_REL_ PSM_Ant_Derivate SG_ 258 GE_StartStopp_Info 500;
BA_REL_ "GenSigTimeoutTime" BU_SG_REL_ Motor_MED17_Hybrid SG_ 258 GE_StartStopp_Info 500;
BA_REL_ "GenSigTimeoutTime" BU_SG_REL_ Motor_EDC17_Pirol SG_ 258 Getriebe_03_CHK 500;
BA_REL_ "GenSigTimeoutTime" BU_SG_REL_ PSM_Ant_Derivate SG_ 258 Getriebe_03_CHK 500;
BA_REL_ "GenSigTimeoutTime" BU_SG_REL_ GW_Routing_Derivate SG_ 258 Getriebe_03_CHK 500;
BA_REL_ "GenSigTimeoutTime" BU_SG_REL_ Motor_MED17_Hybrid SG_ 258 Getriebe_03_CHK 500;
BA_REL_ "GenSigTimeoutTime" BU_SG_REL_ Motor_EDC17_Pirol SG_ 258 Getriebe_03_BZ 500;
BA_REL_ "GenSigTimeoutTime" BU_SG_REL_ PSM_Ant_Derivate SG_ 258 Getriebe_03_BZ 500;
BA_REL_ "GenSigTimeoutTime" BU_SG_REL_ GW_Routing_Derivate SG_ 258 Getriebe_03_BZ 500;
BA_REL_ "GenSigTimeoutTime" BU_SG_REL_ Motor_MED17_Hybrid SG_ 258 Getriebe_03_BZ 500;
BA_REL_ "GenSigTimeoutTime" BU_SG_REL_ Motor_EDC17_Pirol SG_ 258 GE_Freig_Langfr_Schutzmom 500;
BA_REL_ "GenSigTimeoutTime" BU_SG_REL_ PSM_Ant_Derivate SG_ 258 GE_Freig_Langfr_Schutzmom 500;
BA_REL_ "GenSigTimeoutTime" BU_SG_REL_ GW_Routing_Derivate SG_ 258 GE_Freig_Langfr_Schutzmom 500;
BA_REL_ "GenSigTimeoutTime" BU_SG_REL_ Motor_MED17_Hybrid SG_ 258 GE_Freig_Langfr_Schutzmom 500;
BA_REL_ "GenSigTimeoutTime" BU_SG_REL_ Motor_EDC17_Pirol SG_ 258 GE_Uefkt 500;
BA_REL_ "GenSigTimeoutTime" BU_SG_REL_ PSM_Ant_Derivate SG_ 258 GE_Uefkt 500;
BA_REL_ "GenSigTimeoutTime" BU_SG_REL_ GW_Routing_Derivate SG_ 258 GE_Uefkt 500;
BA_REL_ "GenSigTimeoutTime" BU_SG_REL_ Motor_MED17_Hybrid SG_ 258 GE_Uefkt 500;
BA_REL_ "GenSigTimeoutTime" BU_SG_REL_ Motor_EDC17_Pirol SG_ 258 GE_Zielgang 500;
BA_REL_ "GenSigTimeoutTime" BU_SG_REL_ PSM_Ant_Derivate SG_ 258 GE_Zielgang 500;
BA_REL_ "GenSigTimeoutTime" BU_SG_REL_ GW_Routing_Derivate SG_ 258 GE_Zielgang 500;
BA_REL_ "GenSigTimeoutTime" BU_SG_REL_ Motor_MED17_Hybrid SG_ 258 GE_Zielgang 500;
BA_REL_ "GenSigTimeoutTime" BU_SG_REL_ Motor_EDC17_Pirol SG_ 258 GE_Langfr_Schutzmom 500;
BA_REL_ "GenSigTimeoutTime" BU_SG_REL_ PSM_Ant_Derivate SG_ 258 GE_Langfr_Schutzmom 500;
BA_REL_ "GenSigTimeoutTime" BU_SG_REL_ GW_Routing_Derivate SG_ 258 GE_Langfr_Schutzmom 500;
BA_REL_ "GenSigTimeoutTime" BU_SG_REL_ Motor_MED17_Hybrid SG_ 258 GE_Langfr_Schutzmom 500;
BA_REL_ "GenSigTimeoutTime" BU_SG_REL_ PSM_Ant_Derivate SG_ 258 GE_reserv_Waehlhebel 500;
BA_REL_ "GenSigTimeoutTime" BU_SG_REL_ GW_Routing_Derivate SG_ 258 GE_reserv_Waehlhebel 500;
BA_REL_ "GenSigTimeoutTime" BU_SG_REL_ Motor_EDC17_Pirol SG_ 258 GE_Eingangsdrehz 500;
BA_REL_ "GenSigTimeoutTime" BU_SG_REL_ PSM_Ant_Derivate SG_ 258 GE_Eingangsdrehz 500;
BA_REL_ "GenSigTimeoutTime" BU_SG_REL_ GW_Routing_Derivate SG_ 258 GE_Eingangsdrehz 500;
BA_REL_ "GenSigTimeoutTime" BU_SG_REL_ Motor_MED17_Hybrid SG_ 258 GE_Eingangsdrehz 500;
BA_REL_ "GenSigTimeoutTime" BU_SG_REL_ Motor_EDC17_Pirol SG_ 258 GE_Notlauf 500;
BA_REL_ "GenSigTimeoutTime" BU_SG_REL_ PSM_Ant_Derivate SG_ 258 GE_Notlauf 500;
BA_REL_ "GenSigTimeoutTime" BU_SG_REL_ GW_Routing_Derivate SG_ 258 GE_Notlauf 500;
BA_REL_ "GenSigTimeoutTime" BU_SG_REL_ Motor_MED17_Hybrid SG_ 258 GE_Notlauf 500;
BA_REL_ "GenSigTimeoutTime" BU_SG_REL_ PSM_Ant_Derivate SG_ 258 GE_Codierung_MSG 500;
BA_REL_ "GenSigTimeoutTime" BU_SG_REL_ GW_Routing_Derivate SG_ 258 GE_Codierung_MSG 500;
BA_REL_ "GenSigTimeoutTime" BU_SG_REL_ GW_Routing_Derivate SG_ 1089 GE_OBD_AbsperrVent 1000;
BA_REL_ "GenSigTimeoutTime" BU_SG_REL_ Motor_EDC17_Pirol SG_ 1089 GE_OBD_AbsperrVent 1000;
BA_REL_ "GenSigTimeoutTime" BU_SG_REL_ Motor_MED17_Hybrid SG_ 1089 GE_OBD_AbsperrVent 1000;
BA_REL_ "GenSigTimeoutTime" BU_SG_REL_ GW_Routing_Derivate SG_ 1089 GE_Freigabe_Verfallsinfo_WFS 1000;
BA_REL_ "GenSigTimeoutTime" BU_SG_REL_ GW_Routing_Derivate SG_ 1089 GE_Index_Fahrwid 1000;
BA_REL_ "GenSigTimeoutTime" BU_SG_REL_ Motor_EDC17_Pirol SG_ 1089 GE_Index_Fahrwid 1000;
BA_REL_ "GenSigTimeoutTime" BU_SG_REL_ PSM_Ant_Derivate SG_ 1089 GE_Index_Fahrwid 1000;
BA_REL_ "GenSigTimeoutTime" BU_SG_REL_ Motor_MED17_Hybrid SG_ 1089 GE_Index_Fahrwid 1000;
BA_REL_ "GenSigTimeoutTime" BU_SG_REL_ GW_Routing_Derivate SG_ 1089 GE_Heizwunsch 1000;
BA_REL_ "GenSigTimeoutTime" BU_SG_REL_ PSM_Ant_Derivate SG_ 1089 GE_Heizwunsch 1000;
BA_REL_ "GenSigTimeoutTime" BU_SG_REL_ Motor_MED17_Hybrid SG_ 1089 GE_Heizwunsch 1000;
BA_REL_ "GenSigTimeoutTime" BU_SG_REL_ Motor_EDC17_Pirol SG_ 1089 GE_Heizwunsch 1000;
BA_REL_ "GenSigTimeoutTime" BU_SG_REL_ GW_Routing_Derivate SG_ 1089 GE_OBD_Status 1000;
BA_REL_ "GenSigTimeoutTime" BU_SG_REL_ Motor_EDC17_Pirol SG_ 1089 GE_OBD_Status 1000;
BA_REL_ "GenSigTimeoutTime" BU_SG_REL_ PSM_Ant_Derivate SG_ 1089 GE_OBD_Status 1000;
BA_REL_ "GenSigTimeoutTime" BU_SG_REL_ Motor_MED17_Hybrid SG_ 1089 GE_OBD_Status 1000;
BA_REL_ "GenSigTimeoutTime" BU_SG_REL_ GW_Routing_Derivate SG_ 1089 GE_LFR_Adaption 1000;
BA_REL_ "GenSigTimeoutTime" BU_SG_REL_ Motor_EDC17_Pirol SG_ 1089 GE_LFR_Adaption 1000;
BA_REL_ "GenSigTimeoutTime" BU_SG_REL_ PSM_Ant_Derivate SG_ 1089 GE_LFR_Adaption 1000;
BA_REL_ "GenSigTimeoutTime" BU_SG_REL_ Motor_MED17_Hybrid SG_ 1089 GE_LFR_Adaption 1000;
BA_REL_ "GenSigTimeoutTime" BU_SG_REL_ GW_Routing_Derivate SG_ 1089 GE_Grenzkriechmoment 1000;
BA_REL_ "GenSigTimeoutTime" BU_SG_REL_ PSM_Ant_Derivate SG_ 1089 GE_Grenzkriechmoment 1000;
BA_REL_ "GenSigTimeoutTime" BU_SG_REL_ GW_Routing_Derivate SG_ 1089 GE_Charisma_FahrPr 1000;
BA_REL_ "GenSigTimeoutTime" BU_SG_REL_ GW_Routing_Derivate SG_ 1089 GE_Charisma_Status 1000;
BA_REL_ "GenSigTimeoutTime" BU_SG_REL_ PSM_Ant_Derivate SG_ 1089 GE_Charisma_Status 1000;
BA_REL_ "GenSigTimeoutTime" BU_SG_REL_ GW_Routing_Derivate SG_ 1089 GE_Charisma_Umschaltung 1000;
BA_REL_ "GenSigTimeoutTime" BU_SG_REL_ GW_Routing_Derivate SG_ 1089 GE_Verlustmoment 1000;
BA_REL_ "GenSigTimeoutTime" BU_SG_REL_ Motor_EDC17_Pirol SG_ 1089 GE_Verlustmoment 1000;
BA_REL_ "GenSigTimeoutTime" BU_SG_REL_ PSM_Ant_Derivate SG_ 1089 GE_Verlustmoment 1000;
BA_REL_ "GenSigTimeoutTime" BU_SG_REL_ Motor_MED17_Hybrid SG_ 1089 GE_Verlustmoment 1000;
BA_REL_ "GenSigTimeoutTime" BU_SG_REL_ GW_Routing_Derivate SG_ 1089 GE_amax_moeglich 1000;
BA_REL_ "GenSigTimeoutTime" BU_SG_REL_ Motor_EDC17_Pirol SG_ 1089 GE_amax_moeglich 1000;
BA_REL_ "GenSigTimeoutTime" BU_SG_REL_ PSM_Ant_Derivate SG_ 1089 GE_amax_moeglich 1000;
BA_REL_ "GenSigTimeoutTime" BU_SG_REL_ Motor_MED17_Hybrid SG_ 1089 GE_amax_moeglich 1000;
BA_REL_ "GenSigTimeoutTime" BU_SG_REL_ GW_Routing_Derivate SG_ 1089 GE_Sumpftemperatur 1000;
BA_REL_ "GenSigTimeoutTime" BU_SG_REL_ BMS_Hybrid SG_ 1089 GE_Sumpftemperatur 1000;
BA_REL_ "GenSigTimeoutTime" BU_SG_REL_ Motor_EDC17_Pirol SG_ 1089 GE_Sumpftemperatur 1000;
BA_REL_ "GenSigTimeoutTime" BU_SG_REL_ PSM_Ant_Derivate SG_ 1089 GE_Sumpftemperatur 1000;
BA_REL_ "GenSigTimeoutTime" BU_SG_REL_ Motor_MED17_Hybrid SG_ 1089 GE_Sumpftemperatur 1000;
BA_REL_ "GenSigTimeoutTime" BU_SG_REL_ Motor_MED17_Hybrid SG_ 158 Getriebe_Hybrid_01_BZ 500;
BA_REL_ "GenSigTimeoutTime" BU_SG_REL_ Motor_MED17_Hybrid SG_ 158 GE_HYB_Fehlerstatus 500;
BA_REL_ "GenSigTimeoutTime" BU_SG_REL_ Motor_MED17_Hybrid SG_ 158 GE_HYB_Freigabe_K0 500;
BA_REL_ "GenSigTimeoutTime" BU_SG_REL_ Motor_MED17_Hybrid SG_ 158 GE_HYB_Freigabe_LL_Reg 500;
BA_REL_ "GenSigTimeoutTime" BU_SG_REL_ Motor_MED17_Hybrid SG_ 158 GE_HYB_Freig_sSchl_K0 500;
BA_REL_ "GenSigTimeoutTime" BU_SG_REL_ Motor_MED17_Hybrid SG_ 158 GE_HYB_Freig_VM_EM_Stop 500;
BA_REL_ "GenSigTimeoutTime" BU_SG_REL_ Motor_MED17_Hybrid SG_ 158 GE_HYB_Wiederstart 500;
BA_REL_ "GenSigTimeoutTime" BU_SG_REL_ Motor_MED17_Hybrid SG_ 158 GE_HYB_Sportfaktor 500;
BA_REL_ "GenSigTimeoutTime" BU_SG_REL_ Motor_MED17_Hybrid SG_ 158 GE_HYB_VM_akt_halten 500;
BA_REL_ "GenSigTimeoutTime" BU_SG_REL_ Motor_MED17_Hybrid SG_ 158 GE_HYB_StartAnf 500;
BA_REL_ "GenSigTimeoutTime" BU_SG_REL_ Motor_MED17_Hybrid SG_ 158 GE_HYB_VM_Startkontr 500;
BA_REL_ "GenSigTimeoutTime" BU_SG_REL_ LEH_Hybrid SG_ 2022 ISO_EMotor_01_Req_Data 500;
BA_REL_ "GenSigTimeoutTime" BU_SG_REL_ GW_Routing_Derivate SG_ 2030 ISO_EMotor_01_Resp_Data 500;
BA_REL_ "GenSigTimeoutTime" BU_SG_REL_ BMS_Hybrid SG_ 2021 ISO_Hybrid_01_Req_Data 500;
BA_REL_ "GenSigTimeoutTime" BU_SG_REL_ GW_Routing_Derivate SG_ 2029 ISO_Hybrid_01_Resp_Data 500;
BA_REL_ "GenSigTimeoutTime" BU_SG_REL_ BMS_Hybrid SG_ 1720 KBI_Tankinhalt_hochaufl 5000;
BA_REL_ "GenSigTimeoutTime" BU_SG_REL_ BMS_Hybrid SG_ 1720 KBI_Nachtanken_erkannt 5000;
BA_REL_ "GenSigTimeoutTime" BU_SG_REL_ Motor_MED17_Hybrid SG_ 1720 KBI_Reifenumfang 5000;
BA_REL_ "GenSigTimeoutTime" BU_SG_REL_ PSM_Ant_Derivate SG_ 1720 KBI_Reifenumfang 5000;
BA_REL_ "GenSigTimeoutTime" BU_SG_REL_ PSM_Ant_Derivate SG_ 128 Motor_01_CHK 500;
BA_REL_ "GenSigTimeoutTime" BU_SG_REL_ GW_Routing_Derivate SG_ 128 Motor_01_CHK 500;
BA_REL_ "GenSigTimeoutTime" BU_SG_REL_ Getriebe_Derivate SG_ 128 Motor_01_CHK 500;
BA_REL_ "GenSigTimeoutTime" BU_SG_REL_ PSM_Ant_Derivate SG_ 128 Motor_01_BZ 500;
BA_REL_ "GenSigTimeoutTime" BU_SG_REL_ GW_Routing_Derivate SG_ 128 Motor_01_BZ 500;
BA_REL_ "GenSigTimeoutTime" BU_SG_REL_ Getriebe_Derivate SG_ 128 Motor_01_BZ 500;
BA_REL_ "GenSigTimeoutTime" BU_SG_REL_ PSM_Ant_Derivate SG_ 128 MO_Mom_o_ex 500;
BA_REL_ "GenSigTimeoutTime" BU_SG_REL_ GW_Routing_Derivate SG_ 128 MO_Mom_o_ex 500;
BA_REL_ "GenSigTimeoutTime" BU_SG_REL_ Getriebe_Derivate SG_ 128 MO_Mom_o_ex 500;
BA_REL_ "GenSigTimeoutTime" BU_SG_REL_ PSM_Ant_Derivate SG_ 128 MO_Mom_m_ex 500;
BA_REL_ "GenSigTimeoutTime" BU_SG_REL_ GW_Routing_Derivate SG_ 128 MO_Mom_m_ex 500;
BA_REL_ "GenSigTimeoutTime" BU_SG_REL_ Getriebe_Derivate SG_ 128 MO_Mom_m_ex 500;
BA_REL_ "GenSigTimeoutTime" BU_SG_REL_ PSM_Ant_Derivate SG_ 128 MO_Mom_Verlust 500;
BA_REL_ "GenSigTimeoutTime" BU_SG_REL_ GW_Routing_Derivate SG_ 128 MO_Mom_Verlust 500;
BA_REL_ "GenSigTimeoutTime" BU_SG_REL_ Getriebe_Derivate SG_ 128 MO_Mom_Verlust 500;
BA_REL_ "GenSigTimeoutTime" BU_SG_REL_ PSM_Ant_Derivate SG_ 128 MO_Mom_Begrenzung 500;
BA_REL_ "GenSigTimeoutTime" BU_SG_REL_ GW_Routing_Derivate SG_ 128 MO_Mom_Begrenzung 500;
BA_REL_ "GenSigTimeoutTime" BU_SG_REL_ Getriebe_Derivate SG_ 128 MO_Mom_Begrenzung 500;
BA_REL_ "GenSigTimeoutTime" BU_SG_REL_ PSM_Ant_Derivate SG_ 128 MO_Mom_Fahrerwunsch 500;
BA_REL_ "GenSigTimeoutTime" BU_SG_REL_ GW_Routing_Derivate SG_ 128 MO_Mom_Fahrerwunsch 500;
BA_REL_ "GenSigTimeoutTime" BU_SG_REL_ Getriebe_Derivate SG_ 128 MO_Mom_Fahrerwunsch 500;
BA_REL_ "GenSigTimeoutTime" BU_SG_REL_ PSM_Ant_Derivate SG_ 128 MO_Kickdown 500;
BA_REL_ "GenSigTimeoutTime" BU_SG_REL_ GW_Routing_Derivate SG_ 128 MO_Kickdown 500;
BA_REL_ "GenSigTimeoutTime" BU_SG_REL_ Getriebe_Derivate SG_ 128 MO_Kickdown 500;
BA_REL_ "GenSigTimeoutTime" BU_SG_REL_ PSM_Ant_Derivate SG_ 128 MO_KD_Fehler 500;
BA_REL_ "GenSigTimeoutTime" BU_SG_REL_ GW_Applikation_Derivate SG_ 128 MO_KD_Fehler 500;
BA_REL_ "GenSigTimeoutTime" BU_SG_REL_ GW_Routing_Derivate SG_ 128 MO_KD_Fehler 500;
BA_REL_ "GenSigTimeoutTime" BU_SG_REL_ GW_Routing_Derivate SG_ 129 MO_StartStopp_Wiederstart 500;
BA_REL_ "GenSigTimeoutTime" BU_SG_REL_ PSM_Ant_Derivate SG_ 129 MO_StartStopp_Wiederstart 500;
BA_REL_ "GenSigTimeoutTime" BU_SG_REL_ GW_Applikation_Derivate SG_ 129 MO_StartStopp_Wiederstart 500;
BA_REL_ "GenSigTimeoutTime" BU_SG_REL_ Getriebe_Derivate SG_ 129 MO_StartStopp_Wiederstart 500;
BA_REL_ "GenSigTimeoutTime" BU_SG_REL_ GW_Routing_Derivate SG_ 129 MO_StartStopp_Status 500;
BA_REL_ "GenSigTimeoutTime" BU_SG_REL_ PSM_Ant_Derivate SG_ 129 MO_StartStopp_Status 500;
BA_REL_ "GenSigTimeoutTime" BU_SG_REL_ GW_Applikation_Derivate SG_ 129 MO_StartStopp_Status 500;
BA_REL_ "GenSigTimeoutTime" BU_SG_REL_ GW_Routing_Derivate SG_ 129 MO_StartStopp_Motorstopp 500;
BA_REL_ "GenSigTimeoutTime" BU_SG_REL_ LEH_Hybrid SG_ 129 MO_StartStopp_Motorstopp 500;
BA_REL_ "GenSigTimeoutTime" BU_SG_REL_ PSM_Ant_Derivate SG_ 129 MO_StartStopp_Motorstopp 500;
BA_REL_ "GenSigTimeoutTime" BU_SG_REL_ GW_Applikation_Derivate SG_ 129 MO_StartStopp_Motorstopp 500;
BA_REL_ "GenSigTimeoutTime" BU_SG_REL_ Getriebe_Derivate SG_ 129 MO_StartStopp_Motorstopp 500;
BA_REL_ "GenSigTimeoutTime" BU_SG_REL_ GW_Routing_Derivate SG_ 129 MO_StartStopp_Fahrerwunsch 500;
BA_REL_ "GenSigTimeoutTime" BU_SG_REL_ PSM_Ant_Derivate SG_ 129 Motor_02_CHK 500;
BA_REL_ "GenSigTimeoutTime" BU_SG_REL_ GW_Routing_Derivate SG_ 129 Motor_02_CHK 500;
BA_REL_ "GenSigTimeoutTime" BU_SG_REL_ Getriebe_Derivate SG_ 129 Motor_02_CHK 500;
BA_REL_ "GenSigTimeoutTime" BU_SG_REL_ PSM_Ant_Derivate SG_ 129 Motor_02_BZ 500;
BA_REL_ "GenSigTimeoutTime" BU_SG_REL_ GW_Routing_Derivate SG_ 129 Motor_02_BZ 500;
BA_REL_ "GenSigTimeoutTime" BU_SG_REL_ Getriebe_Derivate SG_ 129 Motor_02_BZ 500;
BA_REL_ "GenSigTimeoutTime" BU_SG_REL_ PSM_Ant_Derivate SG_ 129 MO_Mom_ZWR 500;
BA_REL_ "GenSigTimeoutTime" BU_SG_REL_ Getriebe_Derivate SG_ 129 MO_Mom_ZWR 500;
BA_REL_ "GenSigTimeoutTime" BU_SG_REL_ PSM_Ant_Derivate SG_ 129 MO_Mom_Soll 500;
BA_REL_ "GenSigTimeoutTime" BU_SG_REL_ PSM_Ant_Derivate SG_ 129 MO_Mom_Ist 500;
BA_REL_ "GenSigTimeoutTime" BU_SG_REL_ Getriebe_Derivate SG_ 129 MO_Mom_Ist 500;
BA_REL_ "GenSigTimeoutTime" BU_SG_REL_ PSM_Ant_Derivate SG_ 129 MO_Status_Zylabschalt_01 500;
BA_REL_ "GenSigTimeoutTime" BU_SG_REL_ PSM_Ant_Derivate SG_ 129 MO_Status_Normalbetrieb_01 500;
BA_REL_ "GenSigTimeoutTime" BU_SG_REL_ Getriebe_Derivate SG_ 129 MO_Status_Normalbetrieb_01 500;
BA_REL_ "GenSigTimeoutTime" BU_SG_REL_ PSM_Ant_Derivate SG_ 129 MO_Momentenintegral 500;
BA_REL_ "GenSigTimeoutTime" BU_SG_REL_ Getriebe_Derivate SG_ 129 MO_Momentenintegral 500;
BA_REL_ "GenSigTimeoutTime" BU_SG_REL_ Getriebe_Derivate SG_ 129 MO_Ext_E_Fahrt_aktiv 500;
BA_REL_ "GenSigTimeoutTime" BU_SG_REL_ GW_Routing_Derivate SG_ 129 MO_Ext_E_Fahrt_aktiv 500;
BA_REL_ "GenSigTimeoutTime" BU_SG_REL_ Getriebe_Derivate SG_ 261 MO_QBit_Motormomente 500;
BA_REL_ "GenSigTimeoutTime" BU_SG_REL_ GW_Routing_Derivate SG_ 261 MO_QBit_Motormomente 500;
BA_REL_ "GenSigTimeoutTime" BU_SG_REL_ PSM_Ant_Derivate SG_ 261 MO_QBit_Motormomente 500;
BA_REL_ "GenSigTimeoutTime" BU_SG_REL_ BMS_Hybrid SG_ 261 Motor_03_CHK 500;
BA_REL_ "GenSigTimeoutTime" BU_SG_REL_ PSM_Ant_Derivate SG_ 261 Motor_03_CHK 500;
BA_REL_ "GenSigTimeoutTime" BU_SG_REL_ LEH_Hybrid SG_ 261 Motor_03_CHK 500;
BA_REL_ "GenSigTimeoutTime" BU_SG_REL_ GW_Routing_Derivate SG_ 261 Motor_03_CHK 500;
BA_REL_ "GenSigTimeoutTime" BU_SG_REL_ Getriebe_Derivate SG_ 261 Motor_03_CHK 500;
BA_REL_ "GenSigTimeoutTime" BU_SG_REL_ BMS_Hybrid SG_ 261 Motor_03_BZ 500;
BA_REL_ "GenSigTimeoutTime" BU_SG_REL_ PSM_Ant_Derivate SG_ 261 Motor_03_BZ 500;
BA_REL_ "GenSigTimeoutTime" BU_SG_REL_ LEH_Hybrid SG_ 261 Motor_03_BZ 500;
BA_REL_ "GenSigTimeoutTime" BU_SG_REL_ GW_Routing_Derivate SG_ 261 Motor_03_BZ 500;
BA_REL_ "GenSigTimeoutTime" BU_SG_REL_ Getriebe_Derivate SG_ 261 Motor_03_BZ 500;
BA_REL_ "GenSigTimeoutTime" BU_SG_REL_ BMS_Hybrid SG_ 261 MO_QBit_Fahrpedalwerte_01 500;
BA_REL_ "GenSigTimeoutTime" BU_SG_REL_ PSM_Ant_Derivate SG_ 261 MO_QBit_Fahrpedalwerte_01 500;
BA_REL_ "GenSigTimeoutTime" BU_SG_REL_ GW_Routing_Derivate SG_ 261 MO_QBit_Fahrpedalwerte_01 500;
BA_REL_ "GenSigTimeoutTime" BU_SG_REL_ Getriebe_Derivate SG_ 261 MO_QBit_Fahrpedalwerte_01 500;
BA_REL_ "GenSigTimeoutTime" BU_SG_REL_ PSM_Ant_Derivate SG_ 261 MO_QBit_Fahrer_bremst 500;
BA_REL_ "GenSigTimeoutTime" BU_SG_REL_ GW_Routing_Derivate SG_ 261 MO_QBit_Fahrer_bremst 500;
BA_REL_ "GenSigTimeoutTime" BU_SG_REL_ Getriebe_Derivate SG_ 261 MO_QBit_Fahrer_bremst 500;
BA_REL_ "GenSigTimeoutTime" BU_SG_REL_ PSM_Ant_Derivate SG_ 261 MO_QBit_Drehzahl_01 500;
BA_REL_ "GenSigTimeoutTime" BU_SG_REL_ BMS_Hybrid SG_ 261 MO_QBit_Drehzahl_01 500;
BA_REL_ "GenSigTimeoutTime" BU_SG_REL_ GW_Routing_Derivate SG_ 261 MO_QBit_Drehzahl_01 500;
BA_REL_ "GenSigTimeoutTime" BU_SG_REL_ Getriebe_Derivate SG_ 261 MO_QBit_Drehzahl_01 500;
BA_REL_ "GenSigTimeoutTime" BU_SG_REL_ LEH_Hybrid SG_ 261 MO_QBit_Drehzahl_01 500;
BA_REL_ "GenSigTimeoutTime" BU_SG_REL_ PSM_Ant_Derivate SG_ 261 MO_Drehzahl_01 500;
BA_REL_ "GenSigTimeoutTime" BU_SG_REL_ BMS_Hybrid SG_ 261 MO_Drehzahl_01 500;
BA_REL_ "GenSigTimeoutTime" BU_SG_REL_ GW_Applikation_Derivate SG_ 261 MO_Drehzahl_01 500;
BA_REL_ "GenSigTimeoutTime" BU_SG_REL_ GW_Routing_Derivate SG_ 261 MO_Drehzahl_01 500;
BA_REL_ "GenSigTimeoutTime" BU_SG_REL_ Getriebe_Derivate SG_ 261 MO_Drehzahl_01 500;
BA_REL_ "GenSigTimeoutTime" BU_SG_REL_ LEH_Hybrid SG_ 261 MO_Drehzahl_01 500;
BA_REL_ "GenSigTimeoutTime" BU_SG_REL_ PSM_Ant_Derivate SG_ 261 MO_Moment_im_Leerlauf 500;
BA_REL_ "GenSigTimeoutTime" BU_SG_REL_ GW_Routing_Derivate SG_ 261 MO_Moment_im_Leerlauf 500;
BA_REL_ "GenSigTimeoutTime" BU_SG_REL_ Getriebe_Derivate SG_ 261 MO_Moment_im_Leerlauf 500;
BA_REL_ "GenSigTimeoutTime" BU_SG_REL_ PSM_Ant_Derivate SG_ 261 MO_Interlock 500;
BA_REL_ "GenSigTimeoutTime" BU_SG_REL_ GW_Routing_Derivate SG_ 261 MO_Interlock 500;
BA_REL_ "GenSigTimeoutTime" BU_SG_REL_ PSM_Ant_Derivate SG_ 261 MO_BLS 500;
BA_REL_ "GenSigTimeoutTime" BU_SG_REL_ GW_Routing_Derivate SG_ 261 MO_BLS 500;
BA_REL_ "GenSigTimeoutTime" BU_SG_REL_ Getriebe_Derivate SG_ 261 MO_BLS 500;
BA_REL_ "GenSigTimeoutTime" BU_SG_REL_ PSM_Ant_Derivate SG_ 261 MO_Fahrer_bremst 500;
BA_REL_ "GenSigTimeoutTime" BU_SG_REL_ GW_Routing_Derivate SG_ 261 MO_Fahrer_bremst 500;
BA_REL_ "GenSigTimeoutTime" BU_SG_REL_ Getriebe_Derivate SG_ 261 MO_Fahrer_bremst 500;
BA_REL_ "GenSigTimeoutTime" BU_SG_REL_ PSM_Ant_Derivate SG_ 261 MO_Konsistenz_Bremsped 500;
BA_REL_ "GenSigTimeoutTime" BU_SG_REL_ GW_Routing_Derivate SG_ 261 MO_Konsistenz_Bremsped 500;
BA_REL_ "GenSigTimeoutTime" BU_SG_REL_ PSM_Ant_Derivate SG_ 261 MO_Kuppl_schalter 500;
BA_REL_ "GenSigTimeoutTime" BU_SG_REL_ GW_Routing_Derivate SG_ 261 MO_Kuppl_schalter 500;
BA_REL_ "GenSigTimeoutTime" BU_SG_REL_ PSM_Ant_Derivate SG_ 261 MO_Timeout_ESP 500;
BA_REL_ "GenSigTimeoutTime" BU_SG_REL_ GW_Routing_Derivate SG_ 261 MO_Timeout_ESP 500;
BA_REL_ "GenSigTimeoutTime" BU_SG_REL_ PSM_Ant_Derivate SG_ 261 MO_Motor_laeuft 500;
BA_REL_ "GenSigTimeoutTime" BU_SG_REL_ GW_Applikation_Derivate SG_ 261 MO_Motor_laeuft 500;
BA_REL_ "GenSigTimeoutTime" BU_SG_REL_ GW_Routing_Derivate SG_ 261 MO_Motor_laeuft 500;
BA_REL_ "GenSigTimeoutTime" BU_SG_REL_ Getriebe_Derivate SG_ 261 MO_Motor_laeuft 500;
BA_REL_ "GenSigTimeoutTime" BU_SG_REL_ PSM_Ant_Derivate SG_ 261 MO_Solldrehz_Leerlauf 500;
BA_REL_ "GenSigTimeoutTime" BU_SG_REL_ GW_Routing_Derivate SG_ 261 MO_Solldrehz_Leerlauf 500;
BA_REL_ "GenSigTimeoutTime" BU_SG_REL_ Getriebe_Derivate SG_ 261 MO_Solldrehz_Leerlauf 500;
BA_REL_ "GenSigTimeoutTime" BU_SG_REL_ GW_Applikation_Derivate SG_ 261 MO_Solldrehz_Leerlauf 500;
BA_REL_ "GenSigTimeoutTime" BU_SG_REL_ BMS_Hybrid SG_ 261 MO_Fahrpedalrohwert_01 500;
BA_REL_ "GenSigTimeoutTime" BU_SG_REL_ PSM_Ant_Derivate SG_ 261 MO_Fahrpedalrohwert_01 500;
BA_REL_ "GenSigTimeoutTime" BU_SG_REL_ GW_Routing_Derivate SG_ 261 MO_Fahrpedalrohwert_01 500;
BA_REL_ "GenSigTimeoutTime" BU_SG_REL_ Getriebe_Derivate SG_ 261 MO_Fahrpedalrohwert_01 500;
BA_REL_ "GenSigTimeoutTime" BU_SG_REL_ PSM_Ant_Derivate SG_ 261 MO_erste_Ungenauschwelle 500;
BA_REL_ "GenSigTimeoutTime" BU_SG_REL_ GW_Routing_Derivate SG_ 261 MO_erste_Ungenauschwelle 500;
BA_REL_ "GenSigTimeoutTime" BU_SG_REL_ Getriebe_Derivate SG_ 261 MO_erste_Ungenauschwelle 500;
BA_REL_ "GenSigTimeoutTime" BU_SG_REL_ PSM_Ant_Derivate SG_ 261 MO_QBit_Stressfaktor 500;
BA_REL_ "GenSigTimeoutTime" BU_SG_REL_ GW_Routing_Derivate SG_ 261 MO_QBit_Stressfaktor 500;
BA_REL_ "GenSigTimeoutTime" BU_SG_REL_ PSM_Ant_Derivate SG_ 261 MO_Stressfaktor 500;
BA_REL_ "GenSigTimeoutTime" BU_SG_REL_ GW_Routing_Derivate SG_ 261 MO_Stressfaktor 500;
BA_REL_ "GenSigTimeoutTime" BU_SG_REL_ PSM_Ant_Derivate SG_ 263 MO_Anzeigedrehz 500;
BA_REL_ "GenSigTimeoutTime" BU_SG_REL_ GW_Routing_Derivate SG_ 263 MO_Anzeigedrehz 500;
BA_REL_ "GenSigTimeoutTime" BU_SG_REL_ BMS_Hybrid SG_ 263 MO_KVS 500;
BA_REL_ "GenSigTimeoutTime" BU_SG_REL_ PSM_Ant_Derivate SG_ 263 MO_KVS 500;
BA_REL_ "GenSigTimeoutTime" BU_SG_REL_ GW_Routing_Derivate SG_ 263 MO_KVS 500;
BA_REL_ "GenSigTimeoutTime" BU_SG_REL_ BMS_Hybrid SG_ 263 MO_KVS_Ueberlauf 500;
BA_REL_ "GenSigTimeoutTime" BU_SG_REL_ PSM_Ant_Derivate SG_ 263 MO_KVS_Ueberlauf 500;
BA_REL_ "GenSigTimeoutTime" BU_SG_REL_ GW_Routing_Derivate SG_ 263 MO_KVS_Ueberlauf 500;
BA_REL_ "GenSigTimeoutTime" BU_SG_REL_ GW_Routing_Derivate SG_ 263 MO_Ladedruck 500;
BA_REL_ "GenSigTimeoutTime" BU_SG_REL_ PSM_Ant_Derivate SG_ 263 MO_Ladedruck 500;
BA_REL_ "GenSigTimeoutTime" BU_SG_REL_ GW_Routing_Derivate SG_ 263 MO_Oeldruck_HYB 500;
BA_REL_ "GenSigTimeoutTime" BU_SG_REL_ GW_Routing_Derivate SG_ 782 MO_Handshake_STH 500;
BA_REL_ "GenSigTimeoutTime" BU_SG_REL_ GW_Routing_Derivate SG_ 782 Motor_05_CHK 500;
BA_REL_ "GenSigTimeoutTime" BU_SG_REL_ Getriebe_Derivate SG_ 782 Motor_05_CHK 500;
BA_REL_ "GenSigTimeoutTime" BU_SG_REL_ GW_Routing_Derivate SG_ 782 Motor_05_BZ 500;
BA_REL_ "GenSigTimeoutTime" BU_SG_REL_ Getriebe_Derivate SG_ 782 Motor_05_BZ 500;
BA_REL_ "GenSigTimeoutTime" BU_SG_REL_ GW_Routing_Derivate SG_ 782 MO_EKlKomLeiRed 500;
BA_REL_ "GenSigTimeoutTime" BU_SG_REL_ BMS_Hybrid SG_ 782 MO_Freig_Reku 500;
BA_REL_ "GenSigTimeoutTime" BU_SG_REL_ GW_Routing_Derivate SG_ 782 MO_Freig_Reku 500;
BA_REL_ "GenSigTimeoutTime" BU_SG_REL_ GW_Applikation_Derivate SG_ 782 MO_Freig_Reku 500;
BA_REL_ "GenSigTimeoutTime" BU_SG_REL_ GW_Routing_Derivate SG_ 782 MO_Klima_Eingr 500;
BA_REL_ "GenSigTimeoutTime" BU_SG_REL_ GW_Routing_Derivate SG_ 782 MO_Status_Normalbetrieb_02 500;
BA_REL_ "GenSigTimeoutTime" BU_SG_REL_ GW_Routing_Derivate SG_ 782 MO_Schaltbeeinfl_Leistungsbegr 500;
BA_REL_ "GenSigTimeoutTime" BU_SG_REL_ GW_Routing_Derivate SG_ 782 MO_Schaltbeeinfl_Partikelfilter 500;
BA_REL_ "GenSigTimeoutTime" BU_SG_REL_ Getriebe_Derivate SG_ 782 MO_Schaltbeeinfl_Partikelfilter 500;
BA_REL_ "GenSigTimeoutTime" BU_SG_REL_ GW_Routing_Derivate SG_ 782 MO_Prio_MIN_Wunschdrehzahl 500;
BA_REL_ "GenSigTimeoutTime" BU_SG_REL_ Getriebe_Derivate SG_ 782 MO_Prio_MIN_Wunschdrehzahl 500;
BA_REL_ "GenSigTimeoutTime" BU_SG_REL_ GW_Routing_Derivate SG_ 782 MO_Freig_Anlass 500;
BA_REL_ "GenSigTimeoutTime" BU_SG_REL_ GW_Routing_Derivate SG_ 782 MO_Aussp_Anlass 500;
BA_REL_ "GenSigTimeoutTime" BU_SG_REL_ GW_Routing_Derivate SG_ 782 MO_MAX_Wunschdrehzahl 500;
BA_REL_ "GenSigTimeoutTime" BU_SG_REL_ Getriebe_Derivate SG_ 782 MO_MAX_Wunschdrehzahl 500;
BA_REL_ "GenSigTimeoutTime" BU_SG_REL_ GW_Routing_Derivate SG_ 782 MO_Prio_MAX_Wunschdrehzahl 500;
BA_REL_ "GenSigTimeoutTime" BU_SG_REL_ Getriebe_Derivate SG_ 782 MO_Prio_MAX_Wunschdrehzahl 500;
BA_REL_ "GenSigTimeoutTime" BU_SG_REL_ GW_Routing_Derivate SG_ 782 MO_Luftpfad_aktiv 500;
BA_REL_ "GenSigTimeoutTime" BU_SG_REL_ GW_Routing_Derivate SG_ 782 MO_v_Begrenz_Aktiv 500;
BA_REL_ "GenSigTimeoutTime" BU_SG_REL_ GW_Routing_Derivate SG_ 782 MO_v_Begrenz_Aktivierbar 500;
BA_REL_ "GenSigTimeoutTime" BU_SG_REL_ GW_Routing_Derivate SG_ 782 MO_Verbot_EKP 500;
BA_REL_ "GenSigTimeoutTime" BU_SG_REL_ GW_Routing_Derivate SG_ 782 MO_Anf_Pruefimpuls 500;
BA_REL_ "GenSigTimeoutTime" BU_SG_REL_ GW_Routing_Derivate SG_ 782 MO_Anf_KL75 500;
BA_REL_ "GenSigTimeoutTime" BU_SG_REL_ GW_Routing_Derivate SG_ 782 MO_Charisma_FahrPr 500;
BA_REL_ "GenSigTimeoutTime" BU_SG_REL_ PSM_Ant_Derivate SG_ 782 MO_Charisma_Status 500;
BA_REL_ "GenSigTimeoutTime" BU_SG_REL_ GW_Routing_Derivate SG_ 782 MO_Charisma_Status 500;
BA_REL_ "GenSigTimeoutTime" BU_SG_REL_ GW_Routing_Derivate SG_ 782 MO_Charisma_Umschaltung 500;
BA_REL_ "GenSigTimeoutTime" BU_SG_REL_ GW_Routing_Derivate SG_ 782 MO_MIN_Wunschdrehzahl 500;
BA_REL_ "GenSigTimeoutTime" BU_SG_REL_ Getriebe_Derivate SG_ 782 MO_MIN_Wunschdrehzahl 500;
BA_REL_ "GenSigTimeoutTime" BU_SG_REL_ GW_Routing_Derivate SG_ 782 MO_Drehzahlbeeinflussung 500;
BA_REL_ "GenSigTimeoutTime" BU_SG_REL_ GW_Routing_Derivate SG_ 1088 MO_Kat_Warnung 1000;
BA_REL_ "GenSigTimeoutTime" BU_SG_REL_ GW_Routing_Derivate SG_ 1088 MO_ITM_Warnung_Pumpe 1000;
BA_REL_ "GenSigTimeoutTime" BU_SG_REL_ GW_Routing_Derivate SG_ 1088 MO_HYB_Text_4 1000;
BA_REL_ "GenSigTimeoutTime" BU_SG_REL_ GW_Routing_Derivate SG_ 1088 MO_HYB_Status_HV_Ladung 1000;
BA_REL_ "GenSigTimeoutTime" BU_SG_REL_ GW_Routing_Derivate SG_ 1088 MO_Zustand_HWP 1000;
BA_REL_ "GenSigTimeoutTime" BU_SG_REL_ GW_Routing_Derivate SG_ 1088 MO_Kuehlerluefter_MUX 1000;
BA_REL_ "GenSigTimeoutTime" BU_SG_REL_ GW_Routing_Derivate SG_ 1088 MO_Kuehlerluefter_1 1000;
BA_REL_ "GenSigTimeoutTime" BU_SG_REL_ GW_Routing_Derivate SG_ 1088 MO_Kuehlerluefter_2 1000;
BA_REL_ "GenSigTimeoutTime" BU_SG_REL_ GW_Routing_Derivate SG_ 1088 WIV_Anzeige_aktiv 1000;
BA_REL_ "GenSigTimeoutTime" BU_SG_REL_ GW_Routing_Derivate SG_ 1088 WIV_Oelmin_Warn 1000;
BA_REL_ "GenSigTimeoutTime" BU_SG_REL_ GW_Routing_Derivate SG_ 1088 WIV_Sensorfehler 1000;
BA_REL_ "GenSigTimeoutTime" BU_SG_REL_ GW_Routing_Derivate SG_ 1088 WIV_Schieflage 1000;
BA_REL_ "GenSigTimeoutTime" BU_SG_REL_ GW_Routing_Derivate SG_ 1088 WIV_Oelstand 1000;
BA_REL_ "GenSigTimeoutTime" BU_SG_REL_ GW_Routing_Derivate SG_ 1088 WIV_Oelsystem_aktiv 1000;
BA_REL_ "GenSigTimeoutTime" BU_SG_REL_ GW_Routing_Derivate SG_ 1088 WIV_nicht_betriebswarm 1000;
BA_REL_ "GenSigTimeoutTime" BU_SG_REL_ GW_Routing_Derivate SG_ 1088 WIV_Ueberfuell_Warn 1000;
BA_REL_ "GenSigTimeoutTime" BU_SG_REL_ GW_Routing_Derivate SG_ 1088 WIV_laufender_Motor 1000;
BA_REL_ "GenSigTimeoutTime" BU_SG_REL_ GW_Routing_Derivate SG_ 1088 MO_Text_Motorstart 1000;
BA_REL_ "GenSigTimeoutTime" BU_SG_REL_ GW_Routing_Derivate SG_ 1088 MO_Text_MSG_Werkstatt 1000;
BA_REL_ "GenSigTimeoutTime" BU_SG_REL_ GW_Routing_Derivate SG_ 1088 MO_Text_Partikelfil_Reg 1000;
BA_REL_ "GenSigTimeoutTime" BU_SG_REL_ GW_Routing_Derivate SG_ 1088 MO_Text_Fehler_Kraftstoffsys 1000;
BA_REL_ "GenSigTimeoutTime" BU_SG_REL_ GW_Routing_Derivate SG_ 1088 WIV_Oelmenge 1000;
BA_REL_ "GenSigTimeoutTime" BU_SG_REL_ GW_Routing_Derivate SG_ 1088 MO_Systemlampe 1000;
BA_REL_ "GenSigTimeoutTime" BU_SG_REL_ GW_Routing_Derivate SG_ 1088 MO_OBD2_Lampe 1000;
BA_REL_ "GenSigTimeoutTime" BU_SG_REL_ GW_Routing_Derivate SG_ 1088 MO_Heissleuchte 1000;
BA_REL_ "GenSigTimeoutTime" BU_SG_REL_ GW_Routing_Derivate SG_ 1088 MO_Partikel_Lampe 1000;
BA_REL_ "GenSigTimeoutTime" BU_SG_REL_ GW_Routing_Derivate SG_ 1088 MO_Winterfahrprog 1000;
BA_REL_ "GenSigTimeoutTime" BU_SG_REL_ GW_Routing_Derivate SG_ 1088 WIV_Oelstand_nicht_vorhanden 1000;
BA_REL_ "GenSigTimeoutTime" BU_SG_REL_ GW_Routing_Derivate SG_ 1088 WIV_nachfuellanzeige_ein 1000;
BA_REL_ "GenSigTimeoutTime" BU_SG_REL_ GW_Routing_Derivate SG_ 1088 WIV_Ueberfuell_deaktiv 1000;
BA_REL_ "GenSigTimeoutTime" BU_SG_REL_ GW_Routing_Derivate SG_ 1088 WIV_Unterfuell_Warn 1000;
BA_REL_ "GenSigTimeoutTime" BU_SG_REL_ GW_Routing_Derivate SG_ 1088 MO_Tankdeckel_Lampe 1000;
BA_REL_ "GenSigTimeoutTime" BU_SG_REL_ GW_Routing_Derivate SG_ 1088 MO_Text_Tankdeckelwarn 1000;
BA_REL_ "GenSigTimeoutTime" BU_SG_REL_ GW_Routing_Derivate SG_ 1088 WIV_Enable_Oeldr_Motor 1000;
BA_REL_ "GenSigTimeoutTime" BU_SG_REL_ GW_Routing_Derivate SG_ 1088 WIV_Oeldr_Warn_Motor 1000;
BA_REL_ "GenSigTimeoutTime" BU_SG_REL_ GW_Routing_Derivate SG_ 1088 MO_Avus_Motorschutz 1000;
BA_REL_ "GenSigTimeoutTime" BU_SG_REL_ BMS_Hybrid SG_ 1088 MO_HYB_Fahrbereitschaft 1000;
BA_REL_ "GenSigTimeoutTime" BU_SG_REL_ GW_Applikation_Derivate SG_ 1088 MO_HYB_Fahrbereitschaft 1000;
BA_REL_ "GenSigTimeoutTime" BU_SG_REL_ GW_Routing_Derivate SG_ 1088 MO_HYB_Fahrbereitschaft 1000;
BA_REL_ "GenSigTimeoutTime" BU_SG_REL_ GW_Routing_Derivate SG_ 1088 WIV_Oeldyn_avl 1000;
BA_REL_ "GenSigTimeoutTime" BU_SG_REL_ GW_Routing_Derivate SG_ 1088 MO_HYB_Text_7 1000;
BA_REL_ "GenSigTimeoutTime" BU_SG_REL_ GW_Routing_Derivate SG_ 1088 MO_HYB_Text_6 1000;
BA_REL_ "GenSigTimeoutTime" BU_SG_REL_ GW_Routing_Derivate SG_ 1088 MO_HYB_Text_5 1000;
BA_REL_ "GenSigTimeoutTime" BU_SG_REL_ GW_Routing_Derivate SG_ 1088 MO_HYB_Text_3 1000;
BA_REL_ "GenSigTimeoutTime" BU_SG_REL_ GW_Routing_Derivate SG_ 1088 MO_HYB_Text_2 1000;
BA_REL_ "GenSigTimeoutTime" BU_SG_REL_ GW_Routing_Derivate SG_ 1088 MO_HYB_Text_1 1000;
BA_REL_ "GenSigTimeoutTime" BU_SG_REL_ GW_Routing_Derivate SG_ 1600 MO_Nachlaufzeit_Heizungspumpe 5000;
BA_REL_ "GenSigTimeoutTime" BU_SG_REL_ GW_Routing_Derivate SG_ 1600 MO_Kennfeldk 5000;
BA_REL_ "GenSigTimeoutTime" BU_SG_REL_ GW_Routing_Derivate SG_ 1600 MO_QBit_Ansaugluft_Temp 5000;
BA_REL_ "GenSigTimeoutTime" BU_SG_REL_ GW_Routing_Derivate SG_ 1600 MO_QBit_Oel_Temp 5000;
BA_REL_ "GenSigTimeoutTime" BU_SG_REL_ GW_Routing_Derivate SG_ 1600 MO_QBit_Kuehlmittel_Temp 5000;
BA_REL_ "GenSigTimeoutTime" BU_SG_REL_ Getriebe_Derivate SG_ 1600 MO_QBit_Kuehlmittel_Temp 5000;
BA_REL_ "GenSigTimeoutTime" BU_SG_REL_ LEH_Hybrid SG_ 1600 MO_QBit_Kuehlmittel_Temp 5000;
BA_REL_ "GenSigTimeoutTime" BU_SG_REL_ GW_Routing_Derivate SG_ 1600 MO_Stellgliedtest_Soundaktuator 5000;
BA_REL_ "GenSigTimeoutTime" BU_SG_REL_ GW_Applikation_Derivate SG_ 1600 MO_HYB_Fehler_HV_Netz 5000;
BA_REL_ "GenSigTimeoutTime" BU_SG_REL_ GW_Routing_Derivate SG_ 1600 MO_HYB_Fehler_HV_Netz 5000;
BA_REL_ "GenSigTimeoutTime" BU_SG_REL_ GW_Routing_Derivate SG_ 1600 MO_Absperrventil_oeffnen 5000;
BA_REL_ "GenSigTimeoutTime" BU_SG_REL_ GW_Routing_Derivate SG_ 1600 MO_Ansaugluft_Temp 5000;
BA_REL_ "GenSigTimeoutTime" BU_SG_REL_ Getriebe_Derivate SG_ 1600 MO_Ansaugluft_Temp 5000;
BA_REL_ "GenSigTimeoutTime" BU_SG_REL_ GW_Routing_Derivate SG_ 1600 MO_Oel_Temp 5000;
BA_REL_ "GenSigTimeoutTime" BU_SG_REL_ BMS_Hybrid SG_ 1600 MO_Kuehlmittel_Temp 5000;
BA_REL_ "GenSigTimeoutTime" BU_SG_REL_ GW_Applikation_Derivate SG_ 1600 MO_Kuehlmittel_Temp 5000;
BA_REL_ "GenSigTimeoutTime" BU_SG_REL_ GW_Routing_Derivate SG_ 1600 MO_Kuehlmittel_Temp 5000;
BA_REL_ "GenSigTimeoutTime" BU_SG_REL_ Getriebe_Derivate SG_ 1600 MO_Kuehlmittel_Temp 5000;
BA_REL_ "GenSigTimeoutTime" BU_SG_REL_ LEH_Hybrid SG_ 1600 MO_Kuehlmittel_Temp 5000;
BA_REL_ "GenSigTimeoutTime" BU_SG_REL_ GW_Routing_Derivate SG_ 1600 MO_Hoeheninfo 5000;
BA_REL_ "GenSigTimeoutTime" BU_SG_REL_ Getriebe_Derivate SG_ 1600 MO_Hoeheninfo 5000;
BA_REL_ "GenSigTimeoutTime" BU_SG_REL_ Getriebe_Derivate SG_ 1600 MO_Versionsinfo 5000;
BA_REL_ "GenSigTimeoutTime" BU_SG_REL_ GW_Routing_Derivate SG_ 1600 MO_Versionsinfo 5000;
BA_REL_ "GenSigTimeoutTime" BU_SG_REL_ Getriebe_Derivate SG_ 1600 MO_Getriebe_kuehlen 5000;
BA_REL_ "GenSigTimeoutTime" BU_SG_REL_ GW_Routing_Derivate SG_ 1600 MO_Getriebe_kuehlen 5000;
BA_REL_ "GenSigTimeoutTime" BU_SG_REL_ GW_Routing_Derivate SG_ 1600 MO_Mom_Traegheit_02 5000;
BA_REL_ "GenSigTimeoutTime" BU_SG_REL_ GW_Routing_Derivate SG_ 1600 MO_Heizungspumpenansteuerung 5000;
BA_REL_ "GenSigTimeoutTime" BU_SG_REL_ GW_Applikation_Derivate SG_ 1600 MO_SpannungsAnf 5000;
BA_REL_ "GenSigTimeoutTime" BU_SG_REL_ GW_Routing_Derivate SG_ 1600 MO_SpannungsAnf 5000;
BA_REL_ "GenSigTimeoutTime" BU_SG_REL_ Getriebe_Derivate SG_ 1600 MO_aktives_Getriebeheizen 5000;
BA_REL_ "GenSigTimeoutTime" BU_SG_REL_ GW_Routing_Derivate SG_ 1600 MO_aktives_Getriebeheizen 5000;
BA_REL_ "GenSigTimeoutTime" BU_SG_REL_ PSM_Ant_Derivate SG_ 1601 MO_Kraftstoffart 5000;
BA_REL_ "GenSigTimeoutTime" BU_SG_REL_ GW_Routing_Derivate SG_ 1601 MO_Kraftstoffart 5000;
BA_REL_ "GenSigTimeoutTime" BU_SG_REL_ Getriebe_Derivate SG_ 1601 MO_Kraftstoffart 5000;
BA_REL_ "GenSigTimeoutTime" BU_SG_REL_ PSM_Ant_Derivate SG_ 1601 Motor_Code_01_CHK 5000;
BA_REL_ "GenSigTimeoutTime" BU_SG_REL_ LEH_Hybrid SG_ 1601 Motor_Code_01_CHK 5000;
BA_REL_ "GenSigTimeoutTime" BU_SG_REL_ GW_Routing_Derivate SG_ 1601 Motor_Code_01_CHK 5000;
BA_REL_ "GenSigTimeoutTime" BU_SG_REL_ Getriebe_Derivate SG_ 1601 Motor_Code_01_CHK 5000;
BA_REL_ "GenSigTimeoutTime" BU_SG_REL_ PSM_Ant_Derivate SG_ 1601 Motor_Code_01_BZ 5000;
BA_REL_ "GenSigTimeoutTime" BU_SG_REL_ LEH_Hybrid SG_ 1601 Motor_Code_01_BZ 5000;
BA_REL_ "GenSigTimeoutTime" BU_SG_REL_ GW_Routing_Derivate SG_ 1601 Motor_Code_01_BZ 5000;
BA_REL_ "GenSigTimeoutTime" BU_SG_REL_ Getriebe_Derivate SG_ 1601 Motor_Code_01_BZ 5000;
BA_REL_ "GenSigTimeoutTime" BU_SG_REL_ PSM_Ant_Derivate SG_ 1601 MO_Faktor_Momente 5000;
BA_REL_ "GenSigTimeoutTime" BU_SG_REL_ GW_Routing_Derivate SG_ 1601 MO_Faktor_Momente 5000;
BA_REL_ "GenSigTimeoutTime" BU_SG_REL_ Getriebe_Derivate SG_ 1601 MO_Faktor_Momente 5000;
BA_REL_ "GenSigTimeoutTime" BU_SG_REL_ PSM_Ant_Derivate SG_ 1601 MO_Hybridfahrzeug 5000;
BA_REL_ "GenSigTimeoutTime" BU_SG_REL_ GW_Routing_Derivate SG_ 1601 MO_Hybridfahrzeug 5000;
BA_REL_ "GenSigTimeoutTime" BU_SG_REL_ PSM_Ant_Derivate SG_ 1601 MO_Code 5000;
BA_REL_ "GenSigTimeoutTime" BU_SG_REL_ GW_Routing_Derivate SG_ 1601 MO_Code 5000;
BA_REL_ "GenSigTimeoutTime" BU_SG_REL_ Getriebe_Derivate SG_ 1601 MO_Code 5000;
BA_REL_ "GenSigTimeoutTime" BU_SG_REL_ PSM_Ant_Derivate SG_ 1601 MO_Getriebe_Code 5000;
BA_REL_ "GenSigTimeoutTime" BU_SG_REL_ GW_Routing_Derivate SG_ 1601 MO_Getriebe_Code 5000;
BA_REL_ "GenSigTimeoutTime" BU_SG_REL_ Getriebe_Derivate SG_ 1601 MO_Getriebe_Code 5000;
BA_REL_ "GenSigTimeoutTime" BU_SG_REL_ GW_Routing_Derivate SG_ 1601 MO_Anzahl_Zyl 5000;
BA_REL_ "GenSigTimeoutTime" BU_SG_REL_ GW_Routing_Derivate SG_ 1601 MO_Hubraum 5000;
BA_REL_ "GenSigTimeoutTime" BU_SG_REL_ GW_Routing_Derivate SG_ 1601 MO_Ansaugsystem 5000;
BA_REL_ "GenSigTimeoutTime" BU_SG_REL_ GW_Routing_Derivate SG_ 1601 MO_Leistung 5000;
BA_REL_ "GenSigTimeoutTime" BU_SG_REL_ Getriebe_Derivate SG_ 1601 MO_Leistung 5000;
BA_REL_ "GenSigTimeoutTime" BU_SG_REL_ LEH_Hybrid SG_ 1601 MO_Abgastyp 5000;
BA_REL_ "GenSigTimeoutTime" BU_SG_REL_ BMS_Hybrid SG_ 1601 MO_Abgastyp 5000;
BA_REL_ "GenSigTimeoutTime" BU_SG_REL_ GW_Routing_Derivate SG_ 1601 MO_Abgastyp 5000;
BA_REL_ "GenSigTimeoutTime" BU_SG_REL_ Getriebe_Derivate SG_ 1601 MO_Abgastyp 5000;
BA_REL_ "GenSigTimeoutTime" BU_SG_REL_ GW_Routing_Derivate SG_ 1601 MO_Einspritzart 5000;
BA_REL_ "GenSigTimeoutTime" BU_SG_REL_ GW_Routing_Derivate SG_ 1601 MO_StartStopp_Codiert 5000;
BA_REL_ "GenSigTimeoutTime" BU_SG_REL_ Getriebe_Derivate SG_ 1601 MO_StartStopp_Codiert 5000;
BA_REL_ "HYB_Tx_Baureihe" BU_BO_REL_ GW_Routing_Derivate 793 1;
BA_REL_ "HYB_Tx_Verwendung" BU_BO_REL_ GW_Routing_Derivate 924 1;
BA_REL_ "HYB_Tx_Baureihe" BU_BO_REL_ GW_Routing_Derivate 924 2;
BA_REL_ "HYB_Tx_Baureihe" BU_BO_REL_ GW_Routing_Derivate 1604 2;
BA_REL_ "HYB_Tx_Baureihe" BU_BO_REL_ GW_Routing_Derivate 2022 2;
BA_REL_ "HYB_Tx_Baureihe" BU_BO_REL_ GW_Routing_Derivate 2021 2;
BA_REL_ "HYB_Tx_Baureihe" BU_BO_REL_ GW_Routing_Derivate 1720 2;
VAL_ 262 ESP_Status_Anfahrhilfe 0 "Aus" 1 "Ein" ;
VAL_ 262 ESP_Anforderung_EPB 1 "Anforderung_Oeffnen" 0 "keine_Anforderung" 2 "Anforderung_Schliessen" 3 "reserviert" ;
VAL_ 262 ESP_Lenkeingriff_ADS 0 "kein_Lenkeingriff" 1 "stabilisierender_Lenkeingriff" ;
VAL_ 262 ESP_Bremsruck_AWV2 1 "Bremsruck_ausgefuehrt" 0 "kein_Bremsruck_ausgefuehrt" ;
VAL_ 262 ESP_Konsistenz_AWV2 1 "Botschaft_fuer_AWV2_nicht_konsis" 0 "Botschaft_fuer_AWV2_konsistent" ;
VAL_ 262 ESP_QBit_Bremsdruck 0 "gueltiger_Wert" 1 "Ersatz_Init_oder_Fehlerwert" ;
VAL_ 262 ESP_QBit_Fahrer_bremst 0 "gueltiger_Wert" 1 "Ersatz_Init_oder_Fehlerwert" ;
VAL_ 262 ESP_Schwelle_Unterdruck 1 "Unterdruck_kleiner_gleich_450_mb" 0 "kein_Signal" 2 "Unterdruck_groesser_450_mbar" 3 "Fehler_Unterdrucksensor" ;
VAL_ 262 ESP_Bremsdruck 1023 "Fehler" ;
VAL_ 262 ESP_Fahrer_bremst 1 "Fahrer_bremst" 0 "Fahrer_bremst_nicht" ;
VAL_ 262 ESP_Verz_TSK_aktiv 0 "TSK_Verzoegerung_inaktiv" 1 "TSK_Verzoegerung_aktiv" ;
VAL_ 262 ESP_Konsistenz_TSK 1 "Botschaft_fuer_Verzoegerungsanfo" 0 "Botschaft_fuer_Verzoegerungsanfo" ;
VAL_ 262 ECD_Fehler 0 "ECD_iO" 1 "ECD_Fehler" ;
VAL_ 262 ECD_nicht_verfuegbar 0 "ECD_Funktion_verfuegbar" 1 "ECD_Funktion_nicht_verfuegbar" ;
VAL_ 262 ESP_Status_Bremsentemp 0 "Bremse nicht überhitzt" 1 "Bremse überhitzt" ;
VAL_ 262 ESP_Autohold_Standby 0 "Autohold_nicht_im_Standby" 1 "Autohold_im_Standby" ;
VAL_ 262 ESP_HDC_Standby 0 "HDC_Funktion_nicht_im_Standby" 1 "HDC_Funktion_im_Standby" ;
VAL_ 262 ESP_HBA_aktiv 1 "HBA_aktiv" 0 "HBA_nicht_aktiv" ;
VAL_ 262 ESP_Prefill_ausgeloest 1 "Prefill_ausgeloest" 0 "nicht_ausgeloest" ;
VAL_ 262 ESP_Rueckwaertsfahrt_erkannt 0 "keine_Rueckwaetsfahrt" 1 "Rueckwaertsfahrt_erkannt" ;
VAL_ 262 ESP_StartStopp_Info 2 "Motoranlauf_zwingend_notwendig_(" 3 "Systemfehler" 0 "Motorlauf_nicht_notwendig_(Stopp" 1 "Motoranlauf_nicht_zwingend_notwe" ;
VAL_ 262 ESP_Eingr_HL 1 "ESP_Eingriff_HL" 0 "kein_Eingriff" ;
VAL_ 262 ESP_Eingr_HR 0 "kein_Eingriff" 1 "ESP_Eingriff_HR" ;
VAL_ 262 ESP_Eingr_VL 1 "ESP_Eingriff_VL" 0 "kein_Eingriff" ;
VAL_ 262 ESP_Eingr_VR 0 "kein_Eingriff" 1 "ESP_Eingriff_VR" ;
VAL_ 262 ESP_BKV_Unterdruck 255 "Fehler" ;
VAL_ 262 ESP_Autohold_aktiv 1 "Autohold aktiv" 0 "Autohold inaktiv" ;
VAL_ 262 ESP_FStatus_Anfahrhilfe 0 "kein_Fehler" 1 "Fehler" ;
VAL_ 262 ESP_Verz_EPB_aktiv 0 "nicht aktiviert" 1 "aktiviert" ;
VAL_ 262 ECD_Bremslicht 0 "Aus" 1 "Ein" ;
VAL_ 262 ESP_Verzoeg_EPB_verf 0 "nicht verfuegbar" 1 "System verfuegbar" ;
VAL_ 262 ESP_Status_Bremsdruck 0 "Bremse drucklos" 1 "mit Bremsdruck" ;
VAL_ 924 KL_Beschlagsgefahr 0 "keine_Beschlagsgefahr" 1 "Beschlagsgefahr" ;
VAL_ 924 ESP_07_alt 0 "aktuell" 1 "veraltet" ;
VAL_ 924 BCM1_GLW_Fernlicht_Anf 0 "Aus" 1 "Ein" ;
VAL_ 924 BCM1_Gleitende_Leuchtw_Anf 0 "Aus" 1 "Ein" ;
VAL_ 924 BCM1_Adaptive_Lichtvert_Anf 0 "Aus" 1 "Ein" ;
VAL_ 924 ESP_Offroad_Modus 0 "kein_ESP_Offroadmodus" 1 "ESP_Offroadmodus" ;
VAL_ 924 Wischer_vorne_aktiv 1 "Wischer vorne läuft" ;
VAL_ 924 HR_Tuer_geoeffnet 1 "Tuer geoeffnet" 0 "Tuer nicht geoeffnet" ;
VAL_ 924 HL_Tuer_geoeffnet 1 "Tuer geoeffnet" 0 "Tuer nicht geoeffnet" ;
VAL_ 924 BT_Tuer_geoeffnet 1 "Tuer geoeffnet" 0 "Tuer nicht geoeffnet" ;
VAL_ 924 BCM1_02_alt 1 "veraltet" 0 "aktuell" ;
VAL_ 924 BCM1_01_alt 1 "veraltet" 0 "aktuell" ;
VAL_ 924 FT_Tuer_geoeffnet 1 "Tuer geoeffnet" 0 "Tuer nicht geoeffnet" ;
VAL_ 924 BCM1_Rueckfahrlicht_Schalter 0 "aus" 1 "betaetigt" ;
VAL_ 924 BCM1_MH_WIV_Schalter 1 "MH offen" 0 "MH geschlossen" ;
VAL_ 924 BCM1_Aussen_Temp_ungef 253 "nicht verbaut" 254 "Initwert" 255 "Fehler" ;
VAL_ 924 BCM2_03_PAG_alt 1 "veraltet" 0 "aktuell" ;
VAL_ 924 Klima_02_alt 1 "veraltet" 0 "aktuell" ;
VAL_ 924 KL_Zuheizer_Freigabe 1 "Zuheizerfreigabe" 0 "keine Freigabe Zuheizer" ;
VAL_ 924 BCM_Handshake_STH 1 "EKP-Ansteuerung durch STH-Anforderung" 0 "keine EKP-Ansteuerung durch STH-Anforderung" ;
VAL_ 924 Wischer_01_alt 1 "veraltet" 0 "aktuell" ;
VAL_ 924 TSG_BT_1_alt 1 "veraltet" 0 "aktuell" ;
VAL_ 924 TSG_HL_1_alt 1 "veraltet" 0 "aktuell" ;
VAL_ 924 TSG_HR_1_alt 1 "veraltet" 0 "aktuell" ;
VAL_ 924 Klima_Sensor_02_alt 1 "veraltet" 0 "aktuell" ;
VAL_ 924 TSG_FT_1_alt 1 "veraltet" 0 "aktuell" ;
VAL_ 924 Parkhilfe_01_alt 1 "veraltet" 0 "aktuell" ;
VAL_ 924 Fahrwerk_02_alt 1 "veraltet" 0 "aktuell" ;
VAL_ 924 BCM1_OBD_FStatus_ATemp 0 "kein Fehler" 1 "KS-" 2 "KS+" 3 "OC (Leitungsunterbrechung)" 4 "OOR+ (out of range high)" 5 "OOR- (out of range low)" 6 "RC+ (Signal unplausibel hoch)" 7 "RC- (Signal unplausibel niedrig)" 8 "KS+/OC" 9 "KS-/OC" 10 "KS-/KS+" 11 "KS-/KS+/OC (allgemeiner Fehler)" ;
VAL_ 1604 ESP_Diagnose 1 "ESP_in_Diagnose" 0 "ESP_nicht_in_Diagnose" ;
VAL_ 1604 ESP_04_alt 0 "aktuell" 1 "veraltet" ;
VAL_ 1604 ZV_Tankklappe_offen 0 "Tankklappe_geschlossen" 1 "Tankklappe_offen" ;
VAL_ 1604 BCM_Tankwunsch 0 "Fehler_keine_Drucktankfunktionalitaet" 1 "keine_Betankung_erwuenscht" 2 "Betankung_erwuenscht" ;
VAL_ 1604 ZV_verriegelt_extern_ist 1 "Fahrzeug_aussen_verriegelt_Istzustand" ;
VAL_ 1604 BCM2_02_alt 1 "veraltet" 0 "aktuell" ;
VAL_ 1604 Kessy_01_alt 1 "veraltet" 0 "aktuell" ;
VAL_ 1604 FFB_CarFinder 0 "nicht aktiv" 1 "aktiv" ;
VAL_ 1604 FFB_Auf_Taste 1 "Taste am Funkschlüssel betätigt" 0 "Taste nicht betätigt" ;
VAL_ 1604 BCM1_01_alt 1 "veraltet" 0 "aktuell" ;
VAL_ 1604 LV_Nebelschlusslicht_Anzeige 1 "Aktiv" 0 "Inaktiv" ;
VAL_ 1604 LV_Abblendlicht_re_def 1 "defekt" 0 "OK" ;
VAL_ 1604 LV_Abblendlicht_li_def 1 "defekt" 0 "OK" ;
VAL_ 1604 BM_Autobahn 1 "Aktiv" 0 "Inaktiv" ;
VAL_ 1604 BCM1_Linksverkehr 0 "Rechtsverkehr" 1 "Linksverkehr" ;
VAL_ 1604 BCM1_Licht_Dunkelheit_aktiv 1 "Licht wegen Dunkelheit aktiv, nicht bei Autobahnlicht, Tagfahrlicht oder Regenlicht" ;
VAL_ 1604 BCM1_Allwetterlicht_Anf 0 "Licht_nicht_angefordert" 1 "Licht_ist_einzuschalten" ;
VAL_ 1604 BCM1_MH_Schalter 0 "MH_geschlossen" 1 "MH_offen" ;
VAL_ 1604 BH_Blinker_re 1 "Blinkerhebel_Richtung_rechts_betaetigt" 0 "nicht_betaetigt" ;
VAL_ 1604 BH_Blinker_li 1 "Blinkerhebel_Richtung_links_betaetigt" 0 "nicht_betaetigt" ;
VAL_ 1604 SMLS_01_alt 1 "veraltet" 0 "aktuell" ;
VAL_ 1604 BCM1_02_alt 1 "veraltet" 0 "aktuell" ;
VAL_ 1604 HYB_Anf_E_Mode_alt 1 "veraltet" 0 "aktuell" ;
VAL_ 1604 HYB_Anf_E_Mode 1 "Taster betätigt" 0 "Taster nicht betätigt" ;
VAL_ 130 GE_Schaltvorgang 1 "Schaltung aktiv" 0 "keine Schaltung" ;
VAL_ 130 GE_Status_Kupplung 3 "Fehler" 2 "Kupplung geschlossen" 1 "Kupplung geregelt" 0 "Kupplung geöffnet" ;
VAL_ 130 GE_MMom_Soll 1023 "Fehler" 1022 "kein Eingriff" ;
VAL_ 130 GE_MMom_Status 3 "Änderung mit Sprung" 2 "erhöhender Getriebeeingriff" 1 "reduzierender Getriebeeingriff" 0 "keine Anforderung" ;
VAL_ 130 GE_KD_Fehler 1 "mind. ein KD-Fehler vorhanden" 0 "kein KD-Fehler" ;
VAL_ 130 GE_Verbot_Ausblendung 1 "Verbot" 0 "kein_Verbot" ;
VAL_ 130 GE_MMom_Vorhalt 1022 "keine_Anforderung" 1023 "Fehler" ;
VAL_ 130 GE_Freig_MMom_Vorhalt 1 "freigegeben" 0 "nicht_freigegeben" ;
VAL_ 131 GE_Anf_Zylabsch 0 "Umschaltung erlaubt" 1 "Umschaltung verboten" 3 "VMB-Empfehlung" ;
VAL_ 131 GE_Synchro_Wunschdrehz 511 "Fehler" ;
VAL_ 131 GE_Synchro_Zeit 255 "Fehler" ;
VAL_ 131 GE_Mom_Begr_Gradient 255 "keine Begrenzung (Init)" ;
VAL_ 131 GE_Anheb_Solldrehz_Leerlauf 255 "Fehler" ;
VAL_ 131 GE_Vorsteuermoment 510 "Init" 511 "Fehler" ;
VAL_ 131 GE_Drehzahlmesser_Daempfung 0 "normale Dämpfung" 1 "dynamische Dämpfung" ;
VAL_ 131 GE_Schubabschalt_Unt 0 "inaktiv" 1 "aktiv" ;
VAL_ 131 GE_Freigabe_Synchro 0 "inaktiv" 1 "aktiv" ;
VAL_ 131 GE_HYB_DZ_Eingriff 0 "kein_Drehzahleingriff" 1 "Slip_Start" 2 "Low_Speed_Modus" ;
VAL_ 258 GE_Waehlhebel 15 "Fehler" 14 "Tippfunktion" 13 "frei" 12 "frei" 11 "frei" 10 "frei" 9 "Position S" 8 "Position D" 7 "Position N" 6 "Position R" 5 "Position P" 4 "frei" 3 "frei" 2 "frei" 1 "Init" 0 "Zwischenstellung" ;
VAL_ 258 GE_StartStopp_Info 3 "Systemfehler" 2 "Motoranlauf zwingend notwendig (Startanforderung)" 1 "Motoranlauf nicht zwingend notwendig (Stoppverbot, keine Startanforderung, evtl. Komforteinbussen)" 0 "Motorlauf langfristig nicht notwendig (Stoppfreigabe)" ;
VAL_ 258 GE_Freig_Langfr_Schutzmom 0 "nicht freigegeben" 1 "freigegeben" ;
VAL_ 258 GE_Uefkt 1023 "Fehler" ;
VAL_ 258 GE_Zielgang 0 "Gang P/N (ausgekuppelt)" 1 "Gang 1" 2 "Gang 2" 3 "Gang 3" 4 "Gang 4" 5 "Gang 5" 6 "Gang 6" 7 "Gang 7" 8 "Gang R" 11 "Gang 8" 12 "Gang 9" 14 "Istgang nicht definiert" 15 "Fehler" ;
VAL_ 258 GE_Langfr_Schutzmom 1022 "Init" 1023 "Fehler" ;
VAL_ 258 GE_Eingangsdrehz 16382 "Init" 16383 "Fehler" ;
VAL_ 258 GE_Notlauf 0 "kein Notlauf / Init" 1 "Getriebe im Notlauf" ;
VAL_ 258 GE_Codierung_MSG 0 "Codierung iO / Init" 1 "Codierung niO" ;
VAL_ 1089 GE_OBD_AbsperrVent 0 "kein_Fehler" 12 "frei" 13 "frei" 5 "OOR-" 8 "KS+/OC" 9 "KS-/OC" 10 "KS-/KS+" 15 "frei" 3 "OC" 4 "OOR+" 6 "RC+" 7 "RC-" 11 "KS-/KS+/OC" 2 "KS+" 14 "frei" 1 "KS-" ;
VAL_ 1089 GE_Freigabe_Verfallsinfo_WFS 0 "aus" 1 "ein" ;
VAL_ 1089 GE_Index_Fahrwid 255 "Fehler" ;
VAL_ 1089 GE_Heizwunsch 0 "maximaler_Waermebedarf" 1 "kein_Waermebedarf" 2 "Kuehlbedarf" 3 "Notfall_(maximaler_Kuehlbedarf)" ;
VAL_ 1089 GE_OBD_Status 0 "MIL aus" 1 "MIL ein" ;
VAL_ 1089 GE_LFR_Adaption 0 "fuer_Adaption_geeignet" 1 "fuer_Adaption_nicht_geeignet" ;
VAL_ 1089 GE_Grenzkriechmoment 62 "Init" 63 "Fehler" ;
VAL_ 1089 GE_Charisma_FahrPr 1 "Programm_1" 2 "Programm_2" 3 "Programm_3" 4 "Programm_4" 5 "Programm_5" 6 "Programm_6" 7 "Programm_7" 0 "nicht_belegt" ;
VAL_ 1089 GE_Charisma_Status 0 "Init" 1 "verfuegbar" 2 "nicht_verfuegbar" 3 "asynchron_durch_Fahrerwunsch" ;
VAL_ 1089 GE_Charisma_Umschaltung 0 "Idle" 1 "Erkennung_Umschaltaufforderung" 2 "Steuerbotschaft_nicht_definiert" 3 "Umschaltung_verzoegert" ;
VAL_ 1089 GE_Verlustmoment 255 "Fehler" ;
VAL_ 1089 GE_amax_moeglich 511 "Wert ist nicht definiert" ;
VAL_ 1089 GE_Sumpftemperatur 255 "Fehler" ;
VAL_ 158 GE_HYB_Fehlerstatus 0 "kein_Fehler" 1 "kein_Hydraulikdruck" 2 "Anforderung_N_gleich_0" 3 "beide_Fehler" ;
VAL_ 158 GE_HYB_Freigabe_K0 0 "Freigabe_K0_oeffnen" 1 "Freigabe_K0_schliessen" ;
VAL_ 158 GE_HYB_Freigabe_LL_Reg 0 "keine_DZ_reg_erlaubt" 1 "LL_Reg_freigegeben" ;
VAL_ 158 GE_HYB_Freig_sSchl_K0 0 "keine_Anf_Schliessen_K0" 1 "Anf_Schliessen_K0" ;
VAL_ 158 GE_HYB_Freig_VM_EM_Stop 0 "VM_EM_darf_nicht_stoppen" 1 "VM_EM_darf_stoppen" ;
VAL_ 158 GE_HYB_Wiederstart 0 "kein_Wiederstart_aktiv" 1 "Wiederstart_aktiv" ;
VAL_ 158 GE_HYB_nK0 255 "Fehler" ;
VAL_ 158 GE_HYB_VZ_MomEingriff_EM 0 "positiv" 1 "negativ" ;
VAL_ 158 GE_HYB_Sportfaktor 0 "nicht_sportlich" ;
VAL_ 158 GE_HYB_VM_akt_halten 0 "keine_Empfehlung" 1 "VM_aktiv_halten_starten" ;
VAL_ 158 GE_HYB_StartAnf 0 "keine_Startanforderung" 1 "Startanforderung" ;
VAL_ 158 GE_HYB_VM_Startkontr 0 "VM_StartAnf_nicht_freigegeben" 1 "VM_StartAnf_freigegeben" ;
VAL_ 158 GE_HYB_Filt_MomAufbau 0 "keine_Beeinflussung_der_Filterung_durch_Getriebe" 7 "multiplikative_Konstante_fuer_MSG" 6 "multiplikative_Konstante_fuer_MSG" 4 "multiplikative_Konstante_fuer_MSG" 2 "multiplikative_Konstante_fuer_MSG" 1 "multiplikative_Konstante_fuer_MSG" 5 "multiplikative_Konstante_fuer_MSG" 3 "multiplikative_Konstante_fuer_MSG" ;
VAL_ 1720 KBI_Tankfuellstand_Prozent 127 "Fehler" ;
VAL_ 1720 KBI_Tankinhalt_hochaufl 16382 "Init" 16383 "Fehler" ;
VAL_ 1720 KBI_Nachtanken_erkannt 0 "Geberbetrieb" 1 "Nachtankmodus" ;
VAL_ 128 MO_Mom_o_ex 1022 "Init" 1023 "Fehler" ;
VAL_ 128 MO_Mom_m_ex 1022 "Init" 1023 "Fehler" ;
VAL_ 128 MO_Mom_Verlust 1022 "Init" 1023 "Fehler" ;
VAL_ 128 MO_Mom_Begrenzung 1022 "Init" 1023 "Fehler" ;
VAL_ 128 MO_Mom_Fahrerwunsch 1022 "Init" 1023 "Fehler" ;
VAL_ 128 MO_Kickdown 0 "kein Kickdown" 1 "Kickdown" ;
VAL_ 128 MO_KD_Fehler 1 "mind. ein KD-Fehler vorhanden" 0 "kein KD-Fehler" ;
VAL_ 129 MO_StartStopp_Wiederstart 1 "Wiederstart_aktiv" 0 "Wiederstart_inaktiv" ;
VAL_ 129 MO_StartStopp_Status 3 "Mindestens ein weiches oder hartes Veto liegt vor" 2 "Alle Vetos besagen,dass langfristig kein Motorlauf notwendig ist" 1 "Reversible Abschaltung aufgrund sicherheitsrelevanter Funktionen oder über einen Taster" 0 "Fehlerstatus erkannt oder Sicherheitsabschaltung aktiv" ;
VAL_ 129 MO_StartStopp_Motorstopp 1 "Motor_Stop_aktiv" 0 "Motor_Stop_inaktiv" ;
VAL_ 129 MO_StartStopp_Fahrerwunsch 0 "Init" 1 "Stoppverbot_durch_Fahrer" 2 "Stoppfreigabe_durch_Fahrer" 3 "Stoppanforderung_durch_Fahrer" ;
VAL_ 129 MO_Mom_ZWR 1022 "Init" 1023 "Fehler" ;
VAL_ 129 MO_Mom_Soll 1022 "Init" 1023 "Fehler" ;
VAL_ 129 MO_Mom_Ist 1022 "Init" 1023 "Fehler" ;
VAL_ 129 MO_Status_Zylabschalt_01 0 "alle Zylinder brennen" 1 "mindestens ein Zylinder wurde abgeschaltet" ;
VAL_ 129 MO_Status_Normalbetrieb_01 0 "kein Normalbetrieb" 1 "Normalbetrieb erreicht" ;
VAL_ 129 MO_Gangposition 14 "Istgang_nicht_definiert" 5 "Gang_5" 1 "Gang_1" 2 "Gang_2" 7 "Gang_7" 3 "Gang_3" 6 "Gang_6" 4 "Gang_4" 8 "Gang_8" 0 "Gang_N" 12 "Zwischengangstellung" 13 "Gang_R" 15 "Fehler" ;
VAL_ 129 MO_Ext_E_Fahrt_aktiv 1 "Rueckmeldung_E_Taster_ein" 0 "Rueckmeldung_E_Taster_aus" ;
VAL_ 261 MO_QBit_Motormomente 0 "gueltiger_Wert" 1 "Ersatz_Init_oder_Fehlerwert" ;
VAL_ 261 MO_QBit_Fahrpedalwerte_01 0 "gueltiger_Wert" 1 "Ersatz_Init_oder_Fehlerwert" ;
VAL_ 261 MO_QBit_Fahrer_bremst 0 "gueltiger_Wert" 1 "Ersatz_Init_oder_Fehlerwert" ;
VAL_ 261 MO_QBit_Drehzahl_01 0 "gueltiger_Wert" 1 "Ersatz_Init_oder_Fehlerwert" ;
VAL_ 261 MO_Drehzahl_01 65535 "Fehler" ;
VAL_ 261 MO_Moment_im_Leerlauf 0 "kein_Leergas" 1 "Leergas" ;
VAL_ 261 MO_Interlock 0 "Interlockschalter nicht betätigt" 1 "Interlockschalter betätigt" ;
VAL_ 261 MO_BLS 0 "kein Bremsen" 1 "Bremse betätigt" ;
VAL_ 261 MO_Fahrer_bremst 0 "kein Bremsen" 1 "Bremse betätigt" ;
VAL_ 261 MO_Konsistenz_Bremsped 0 "Bremspedalinformation_plausibel" 1 "Bremspedalinformation_unplausibel" ;
VAL_ 261 MO_Kuppl_schalter 0 "Schalter sagt betätigt (Ausgekuppelt)" 1 "Schalter sagt nicht betätigt (Eingekuppelt)" ;
VAL_ 261 MO_Timeout_ESP 0 "Empfang i.O." 1 "Timeout" ;
VAL_ 261 MO_Motor_laeuft 0 "Motor läuft nicht" 1 "Motor läuft autark und stabil und darf mechanisch belastet werden" ;
VAL_ 261 MO_Solldrehz_Leerlauf 255 "Fehler" ;
VAL_ 261 MO_Fahrpedalrohwert_01 255 "Fehler" ;
VAL_ 261 MO_erste_Ungenauschwelle 0 "genau" 1 "Momente ungenauer >8%" ;
VAL_ 261 MO_QBit_Stressfaktor 0 "gueltiger_Wert" 1 "Ersatz_Init_oder_Fehlerwert" ;
VAL_ 263 MO_Anzeigedrehz 4095 "Fehler" ;
VAL_ 263 MO_KVS_Ueberlauf 0 "kein Ueberlauf" 1 "Kraftstoffverbrauchsignale mindestens 1x übergelaufen" ;
VAL_ 263 MO_Ladedruck 511 "Fehler" ;
VAL_ 263 MO_Oeldruck_HYB 255 "Fehler" ;
VAL_ 263 MO_Istgang 0 "kein Gang eingelegt" 1 "1.Gang" 2 "2.Gang" 3 "3.Gang" 4 "4.Gang" 5 "5.Gang" 6 "6.Gang" ;
VAL_ 263 MO_Schaltempf_verfbar 0 "nicht verfügbar" 1 "verfügbar" ;
VAL_ 263 MO_Sollgang 0 "keine Empfehlung" 1 "1.Gang" 2 "2.Gang" 3 "3.Gang" 4 "4.Gang" 5 "5.Gang" 6 "6.Gang" ;
VAL_ 782 MO_Handshake_STH 0 "keine EKP-Ansteuerung durch STH-Anforderung" 1 "EKP-Ansteuerung durch STH-Anforderung" ;
VAL_ 782 MO_EKlKomLeiRed 0 "keine_Leistungsbegr" 1 "Leistungsbegr_75" 2 "Leistungsbegr_50" 3 "Leistungsbegr_25" ;
VAL_ 782 MO_Freig_Reku 0 "Rekuperations-Modus aus" 1 "Empfehlung Spannungsanhebung" 2 "Empfehlung Spannungsabsenkung" 3 "Rekuperationsmodus aktiv, Spannungsvariation nicht notwendig" ;
VAL_ 782 MO_Klima_Eingr 0 "kein Eingriff" 1 "Klimakompressor ausschalten" 2 "Klimakompressor Leistungsreduzierung" 3 "Klimakompressor aufgrund der Heissleuchtenvorwarnung ausschalten" ;
VAL_ 782 MO_Status_Normalbetrieb_02 0 "kein Normalbetrieb" 1 "Normalbetrieb erreicht" ;
VAL_ 782 MO_Prio_MIN_Wunschdrehzahl 0 "Wunsch" 1 "Zwang" ;
VAL_ 782 MO_Freig_Anlass 0 "Start nicht zulässig" 1 "Startfreigabe" ;
VAL_ 782 MO_Aussp_Anlass 0 "Motor läuft nicht stabil" 1 "Anlasser ausspuren (Motor läuft stabil)" ;
VAL_ 782 MO_MAX_Wunschdrehzahl 511 "Fehler" ;
VAL_ 782 MO_Prio_MAX_Wunschdrehzahl 0 "Wunsch" 1 "Zwang" ;
VAL_ 782 MO_Luftpfad_aktiv 0 "kein Eingriff oder nur Eingriff über Zündpfad" 1 "Eingriff über Luftpfad" ;
VAL_ 782 MO_v_Begrenz_Aktiv 0 "inaktiv" 1 "aktiv" ;
VAL_ 782 MO_v_Begrenz_Aktivierbar 0 "V-Begrenzung nicht möglich" 1 "V-Begrenzung möglich" ;
VAL_ 782 MO_Verbot_EKP 0 "Ansteuerung zugelassen" 1 "Ansteuerung verboten" ;
VAL_ 782 MO_Anf_Pruefimpuls 0 "keine Anforderung" 1 "Anforderung" ;
VAL_ 782 MO_Anf_KL75 0 "Anforderung KL75 ausschalten" 1 "Anforderung KL75 einschalten" ;
VAL_ 782 MO_Charisma_FahrPr 0 "nicht_belegt" 1 "Programm_1" 2 "Programm_2" 3 "Programm_3" 4 "Programm_4" 5 "Programm_5" 6 "Programm_6" 7 "Programm_7" ;
VAL_ 782 MO_Charisma_Status 0 "Init" 1 "verfuegbar" 2 "nicht_verfuegbar" 3 "asynchron_durch_Fahrerwunsch" ;
VAL_ 782 MO_Charisma_Umschaltung 0 "Idle" 1 "Erkennung_Umschaltaufforderung" 2 "Steuerbotschaft_nicht_definiert" 3 "Umschaltung_verzoegert" ;
VAL_ 782 MO_MIN_Wunschdrehzahl 255 "Fehler" ;
VAL_ 1088 MO_Kat_Warnung 0 "Lampe_aus" 1 "Lampe_ein" ;
VAL_ 1088 MO_ITM_Warnung_Pumpe 0 "keine_Warnung" 1 "ITM_Warnung" ;
VAL_ 1088 MO_HYB_Text_4 0 "kein_Text" 1 "Text_anzeigen" ;
VAL_ 1088 MO_HYB_Status_HV_Ladung 0 "HV-Ladung_nicht_notwendig" 1 "HV-Ladung_notwendig_Freigaben_erforderlich" 2 "HV-Ladung laeuf" 3 "HV-Ladung_erfolgreich_Motorstart_moeglich" 4 "HV_Ladung_abgebrochen" ;
VAL_ 1088 MO_Zustand_HWP 2 "HWP_fördert" 0 "HWP_nicht_schaltbar" 1 "HWP_fördert_nicht" 3 "reserviert" ;
VAL_ 1088 MO_Kuehlerluefter_MUX 0 "Kuehlerluefter_1" 1 "Kuehlerluefter_2" ;
VAL_ 1088 MO_Kuehlerluefter_1 126 "Init" 127 "Fehler" ;
VAL_ 1088 MO_Kuehlerluefter_2 126 "Init" 127 "Fehler" ;
VAL_ 1088 WIV_Anzeige_aktiv 0 "Anzeige aus" 1 "WIV Anzeige aktiv" ;
VAL_ 1088 WIV_Oelmin_Warn 0 "in_Ordnung" 1 "Warnung" ;
VAL_ 1088 WIV_Sensorfehler 0 "in_Ordnung" 1 "Sensor_defekt" ;
VAL_ 1088 WIV_Schieflage 0 "Fahrzeug_gerade" 1 "Fahrzeug_in_Schieflage" ;
VAL_ 1088 WIV_Oelsystem_aktiv 0 "Anzeige_aus" 1 "Anzeige_aktiv" ;
VAL_ 1088 WIV_nicht_betriebswarm 0 "Motor_warm" 1 "Motor_nicht_betriebswarm" ;
VAL_ 1088 WIV_Ueberfuell_Warn 0 "in_Ordnung" 1 "Ueberfuellwarnung" ;
VAL_ 1088 WIV_laufender_Motor 0 "Messung_moeglich" 1 "Messung_nicht_moeglich" ;
VAL_ 1088 MO_Text_Motorstart 11 "(Belegt bei VW/Audi)" 10 "(Belegt bei VW/Audi)" 9 "(Belegt bei VW/Audi)" 8 "(Vorhalt für Start/Stopp) " 7 "(Vorhalt für Start/Stopp) " 6 "(Vorhalt für Start/Stopp) " 5 "Start/Stopp temporär nicht verfügbar" 4 "Nicht belegt (Vorhalt AUDI)" 15 "Bremse treten" 14 "Waehlhebel in PN Position" 13 "Kupplung betaetigt" 12 "Motor startet" 3 "System fordert Wiederstart" 2 "StartStopp sicherheitsbedingt deaktiviert" 1 "Motor im Stoppbetrieb" 0 "keine Anzeige" ;
VAL_ 1088 MO_Systemlampe 0 "Lampe aus" 1 "Lampe ein" ;
VAL_ 1088 MO_OBD2_Lampe 0 "Lampe aus" 1 "Lampe ein" ;
VAL_ 1088 MO_Heissleuchte 0 "Lampe aus" 1 "Lampe ein" ;
VAL_ 1088 MO_Partikel_Lampe 0 "Lampe aus" 1 "Lampe ein" ;
VAL_ 1088 WIV_Oelstand_nicht_vorhanden 0 "Ölstand vorhanden" 1 "Ölstand nicht vorhanden" ;
VAL_ 1088 WIV_nachfuellanzeige_ein 0 "keine_Nachfuellanzeige" 1 "Nachfuellanzeige" ;
VAL_ 1088 WIV_Ueberfuell_deaktiv 0 "Ueberfuellwarnung_am_Kombi_aktiv" 1 "Ueberfuellwarnung_am_Kombi_deaktiv" ;
VAL_ 1088 WIV_Unterfuell_Warn 0 "in_Ordnung" 1 "Unterfuellwarnung" ;
VAL_ 1088 MO_Tankdeckel_Lampe 0 "Lampe aus" 1 "Lampe ein" ;
VAL_ 1088 MO_Text_Tankdeckelwarn 0 "kein Text" 1 "Anzeige Text Tankdeckelwarnung im Kombi" ;
VAL_ 1088 WIV_Enable_Oeldr_Motor 0 "Oeldruckauswertung_im_Kombi" 1 "Oeldruckauswertung_im_MSG" ;
VAL_ 1088 WIV_Oeldr_Warn_Motor 0 "keine_Warnung" 1 "niedrige_Oeldruckstufe_nicht_erreicht " ;
VAL_ 1088 MO_Avus_Motorschutz 0 "keine Warnung" 1 "Drehzahlwarnung Stufe 1" 2 "Drehzahlwarnung Stufe 2" 3 "Drehzahlwarnung Stufe 3" ;
VAL_ 1088 MO_HYB_Fahrbereitschaft 0 "keine_Fahrbereitschaft" 1 "Fahrbereitschaft" ;
VAL_ 1088 WIV_Oeldyn_avl 0 "Oeldyn_nicht_vorhanden" 1 "Oeldyn_vorhanden" ;
VAL_ 1088 MO_HYB_Text_7 0 "kein_Text" 1 "Text_anzeigen" ;
VAL_ 1088 MO_HYB_Text_6 1 "Text_anzeigen" 0 "kein_Text" ;
VAL_ 1088 MO_HYB_Text_5 1 "Text_anzeigen" 0 "kein_Text" ;
VAL_ 1088 MO_HYB_Text_3 0 "kein_Text" 1 "Text_anzeigen" ;
VAL_ 1088 MO_HYB_Text_2 0 "kein_Text" 1 "Text_anzeigen" ;
VAL_ 1088 MO_HYB_Text_1 1 "Text_anzeigen" 0 "kein_Text" ;
VAL_ 1600 MO_Kennfeldk 0 "keine Kennfeldkühlung vorhanden" 1 "Kennfeldkühlung vorhanden" ;
VAL_ 1600 MO_QBit_Ansaugluft_Temp 0 "gueltiger_Wert" 1 "Ersatz_Init_oder_Fehlerwert" ;
VAL_ 1600 MO_QBit_Oel_Temp 0 "gueltiger_Wert" 1 "Ersatz_Init_oder_Fehlerwert" ;
VAL_ 1600 MO_QBit_Kuehlmittel_Temp 0 "gueltiger_Wert" 1 "Ersatz_Init_oder_Fehlerwert" ;
VAL_ 1600 MO_Stellgliedtest_Soundaktuator 0 "kein_Stellgliedtest" 1 "Anforderung_des_Stellgliedtest" ;
VAL_ 1600 MO_HYB_Fehler_HV_Netz 0 "i_O" 1 "kein_generatorischer_Betrieb_moeglich" ;
VAL_ 1600 MO_Absperrventil_oeffnen 0 "nicht_verfuegbar" 1 "Ansteuerung_Ventil_zulaessig" 2 "Ventil_oeffnen_oder_geoeffnet" 3 "Ventil_schliessen_oder_geschlossen" ;
VAL_ 1600 MO_Ansaugluft_Temp 254 "Init" 255 "Fehler" ;
VAL_ 1600 MO_Oel_Temp 253 "nicht_verbaut" 254 "Init" 255 "Fehler" ;
VAL_ 1600 MO_Kuehlmittel_Temp 254 "Init" 255 "Fehler" ;
VAL_ 1600 MO_Hoeheninfo 255 "Fehler" ;
VAL_ 1600 MO_Versionsinfo 0 "zum Projektbeginn 'aufgeräumter CAN' " 1 "Motor_03_mit_10ms" 16 "MQB_mit_neuer_Momentenschnittstelle" ;
VAL_ 1600 MO_Getriebe_kuehlen 0 "nicht_kuehlen" 1 "kuehlen" ;
VAL_ 1600 MO_Heizungspumpenansteuerung 15 "nicht_verbaut" ;
VAL_ 1600 MO_SpannungsAnf 0 "keine_Anforderung" 1 "Anforderung" ;
VAL_ 1600 MO_aktives_Getriebeheizen 0 "kein_Ventil_ansteuern" 1 "Ventil_muss_angesteuert_werden" ;
VAL_ 1601 MO_Kraftstoffart 4 "Wasserstoff" 3 "Erdgas" 2 "CNG" 1 "Benzin" 0 "Diesel" ;
VAL_ 1601 MO_Faktor_Momente 0 "nicht belegt" 1 "Faktor: x 0,5Nm" 2 "Faktor: x 1,0Nm" 3 "Faktor: x 2,0Nm" ;
VAL_ 1601 MO_Hybridfahrzeug 3 "PlugIn_Hybrid" 2 "Full_Hybrid" 1 "Mild_Hybrid" 0 "kein_Hybridfahrzeug" ;
VAL_ 1601 MO_Getriebe_Code 2 "DL501" 4 "VL381" 10 "AL651" 11 "AL551, AL951, AL1000-8A" 12 "PDK_PAG" 13 "AL551_Hybrid" 15 "Handschalter (konventionell)" 16 "AQ250" 17 "AQ450" 18 "DQ200" 19 "DQ250" 20 "DQ500" 21 "SQ100" 22 "SQ200" ;
VAL_ 1601 MO_Ansaugsystem 0 "Turbo" 1 "Sauger" ;
VAL_ 1601 MO_Einspritzart 0 "MPI" 1 " FSI / TDI" ;
VAL_ 1601 MO_StartStopp_Codiert 1 "StartStopp vorhanden/verbaut" 0 "StartStopp nicht vorhanden/verbaut" ;
